VERSION "HNNBNNNYNNNNNNNNNNNNNNNNNNNNNNNNNNNNNNNNNN/4/%%%/4/'%**4NNN///"

NS_ :

BS_:

BU_: BAP_Tester ELV Gateway_Max HUD Kombi

BO_ 1624 Licht_vorne_01: 8 Gateway_Max
 SG_ Licht_Vorne_01_CRC : 0|8@1+ (1,0) [0|255] ""  Vector__XXX
 SG_ Licht_Vorne_01_BZ : 8|4@1+ (1,0) [0|15] ""  Vector__XXX
 SG_ LV_Standlicht_Anzeige : 12|1@1+ (1.0,0.0) [0.0|1] ""  Kombi
 SG_ LV_Abblendlicht_Anzeige : 13|1@1+ (1.0,0.0) [0.0|1] ""  Kombi
 SG_ LV_Fernlicht_Anzeige : 14|1@1+ (1.0,0.0) [0.0|1] ""  Kombi
 SG_ LV_Nebellicht_Anzeige : 15|1@1+ (1.0,0.0) [0.0|1] ""  Kombi
 SG_ LV_Nebelschlusslicht_Anzeige : 16|1@1+ (1.0,0.0) [0.0|1] ""  Kombi
 SG_ LV_Tagfahrlicht_Anzeige : 17|1@1+ (1.0,0.0) [0.0|1] ""  Kombi
 SG_ LV_AFL_aktiv_Anzeige : 18|1@1+ (1.0,0.0) [0.0|1] ""  Kombi
 SG_ LV_AFL_defekt : 19|1@1+ (1.0,0.0) [0.0|1] ""  Kombi
 SG_ LV_Blinker_li_def : 20|1@1+ (1.0,0.0) [0.0|1] ""  Kombi
 SG_ LV_Standlicht_li_def : 21|1@1+ (1.0,0.0) [0.0|1] ""  Kombi
 SG_ LV_Abblendlicht_li_def : 22|1@1+ (1.0,0.0) [0.0|1] ""  Kombi
 SG_ LV_Fernlicht_li_def : 23|1@1+ (1.0,0.0) [0.0|1] ""  Kombi
 SG_ LV_Nebellicht_li_def : 24|1@1+ (1.0,0.0) [0.0|1] ""  Kombi
 SG_ LV_Blk_li_Seite_def : 25|1@1+ (1.0,0.0) [0.0|1] ""  Kombi
 SG_ LV_Tagfahrlicht_li_def : 26|1@1+ (1.0,0.0) [0.0|1] ""  Kombi
 SG_ LV_FLA_aktiv_Anzeige : 27|1@1+ (1.0,0.0) [0.0|1] ""  Kombi
 SG_ LV_FLA_defekt : 28|1@1+ (1.0,0.0) [0.0|1] ""  Kombi
 SG_ LV_FLA_Sensor_blockiert : 29|1@1+ (1.0,0.0) [0.0|1] ""  Kombi
 SG_ LV_Blinker_re_def : 30|1@1+ (1.0,0.0) [0.0|1] ""  Kombi
 SG_ LV_Standlicht_re_def : 31|1@1+ (1.0,0.0) [0.0|1] ""  Kombi
 SG_ LV_Abblendlicht_re_def : 32|1@1+ (1.0,0.0) [0.0|1] ""  Kombi
 SG_ LV_Fernlicht_re_def : 33|1@1+ (1.0,0.0) [0.0|1] ""  Kombi
 SG_ LV_Nebellicht_re_def : 34|1@1+ (1.0,0.0) [0.0|1] ""  Kombi
 SG_ LV_Blk_re_Seite_def : 35|1@1+ (1.0,0.0) [0.0|1] ""  Kombi
 SG_ LV_Tagfahrlicht_re_def : 36|1@1+ (1.0,0.0) [0.0|1] ""  Kombi
 SG_ LV_Aussenlicht_def : 37|1@1+ (1.0,0.0) [0.0|1] ""  Kombi
 SG_ LV_Abblendlicht_TFL_li_def : 38|1@1+ (1.0,0.0) [0.0|1] ""  Kombi
 SG_ LV_Nebellicht_TFL_li_def : 39|1@1+ (1.0,0.0) [0.0|1] ""  Kombi
 SG_ LV_Standlicht_TFL_li_def : 40|1@1+ (1.0,0.0) [0.0|1] ""  Kombi
 SG_ LV_Abblend_Fernlicht_li_def : 41|1@1+ (1.0,0.0) [0.0|1] ""  Kombi
 SG_ LV_Abblendlicht_TFL_re_def : 42|1@1+ (1.0,0.0) [0.0|1] ""  Kombi
 SG_ LV_Nebellicht_TFL_re_def : 43|1@1+ (1.0,0.0) [0.0|1] ""  Kombi
 SG_ LV_Standlicht_TFL_re_def : 44|1@1+ (1.0,0.0) [0.0|1] ""  Kombi
 SG_ LV_Abblend_Fernlicht_re_def : 45|1@1+ (1.0,0.0) [0.0|1] ""  Kombi
 SG_ LV_Abbiegelicht_li_def : 46|1@1+ (1.0,0.0) [0.0|1] ""  Kombi
 SG_ LV_Abbiegelicht_re_def : 47|1@1+ (1.0,0.0) [0.0|1] ""  Kombi
 SG_ BCM1_Linksverkehr : 48|1@1+ (1.0,0.0) [0.0|1] ""  Vector__XXX
 SG_ BCM1_Licht_Dunkelheit_aktiv : 49|1@1+ (1.0,0.0) [0.0|1] ""  Kombi
 SG_ LV_LED_Scheinwerfer_li_def : 50|1@1+ (1.0,0.0) [0.0|1] ""  Kombi
 SG_ LV_LED_Scheinwerfer_re_def : 51|1@1+ (1.0,0.0) [0.0|1] ""  Kombi
 SG_ LV_Blinker_VL_aktiv : 52|1@1+ (1.0,0.0) [0.0|1] ""  Vector__XXX
 SG_ LV_Blinker_VR_aktiv : 53|1@1+ (1.0,0.0) [0.0|1] ""  Vector__XXX
 SG_ LV_MXB_Status_Anzeige : 54|2@1+ (1.0,0.0) [0.0|3] ""  Vector__XXX

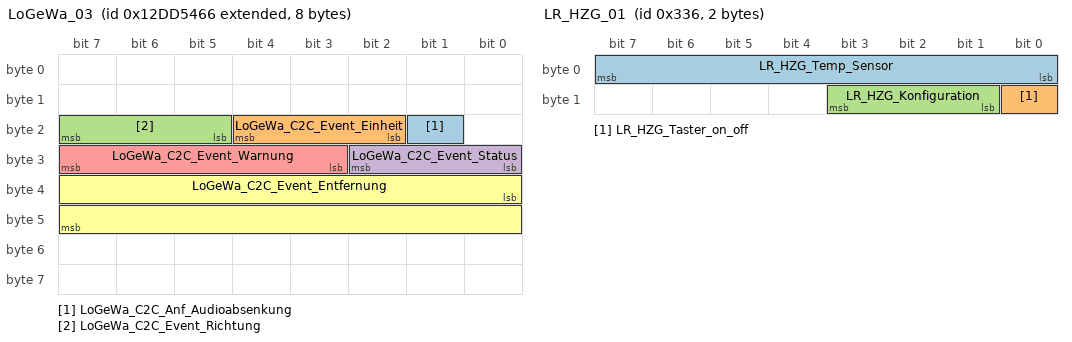
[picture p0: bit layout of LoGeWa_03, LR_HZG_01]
BO_ 2463978598 LoGeWa_03: 8 Gateway_Max
 SG_ LoGeWa_C2C_Anf_Audioabsenkung : 17|1@1+ (1.0,0.0) [0.0|1] ""  Vector__XXX
 SG_ LoGeWa_C2C_Event_Einheit : 18|3@1+ (1.0,0.0) [0.0|7] ""  HUD,Kombi
 SG_ LoGeWa_C2C_Event_Richtung : 21|3@1+ (1.0,0.0) [0.0|7] ""  HUD,Kombi
 SG_ LoGeWa_C2C_Event_Status : 24|3@1+ (1.0,0.0) [0.0|7] ""  HUD,Kombi
 SG_ LoGeWa_C2C_Event_Warnung : 27|5@1+ (1.0,0.0) [0.0|31] ""  HUD,Kombi
 SG_ LoGeWa_C2C_Event_Entfernung : 32|16@1+ (0.1,0) [0.0|6553.4] "Unit_None"  HUD,Kombi

BO_ 822 LR_HZG_01: 2 Gateway_Max
 SG_ LR_HZG_Temp_Sensor : 0|8@1+ (1,-50) [-50|104] "Unit_DegreCelsi"  Vector__XXX
 SG_ LR_HZG_Taster_on_off : 8|1@1+ (1.0,0.0) [0.0|1] ""  Vector__XXX
 SG_ LR_HZG_Konfiguration : 9|3@1+ (1.0,0.0) [0.0|7] ""  Vector__XXX

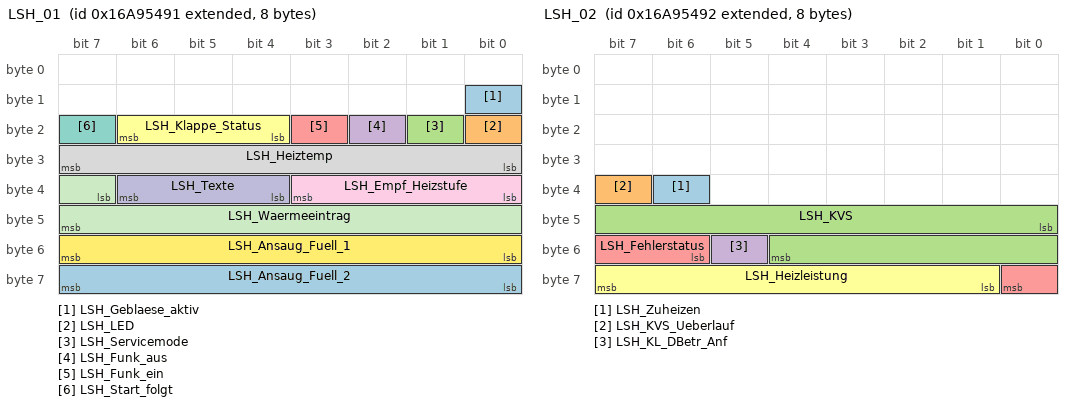
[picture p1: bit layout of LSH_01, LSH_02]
BO_ 2527679633 LSH_01: 8 Gateway_Max
 SG_ LSH_Geblaese_aktiv : 8|1@1+ (1.0,0.0) [0.0|1] ""  Gateway_Max
 SG_ LSH_LED : 16|1@1+ (1.0,0.0) [0.0|1] ""  Gateway_Max
 SG_ LSH_Servicemode : 17|1@1+ (1.0,0.0) [0.0|1] ""  Gateway_Max
 SG_ LSH_Funk_aus : 18|1@1+ (1.0,0.0) [0.0|1] ""  Gateway_Max
 SG_ LSH_Funk_ein : 19|1@1+ (1.0,0.0) [0.0|1] ""  Gateway_Max
 SG_ LSH_Klappe_Status : 20|3@1+ (1.0,0.0) [0.0|7] ""  Gateway_Max
 SG_ LSH_Start_folgt : 23|1@1+ (1.0,0.0) [0.0|1] ""  Gateway_Max
 SG_ LSH_Heiztemp : 24|8@1+ (2,-40) [-40|360] "Unit_DegreCelsi"  Gateway_Max
 SG_ LSH_Empf_Heizstufe : 32|4@1+ (1.0,0.0) [0.0|15] ""  Gateway_Max
 SG_ LSH_Texte : 36|3@1+ (1.0,0.0) [0.0|7] ""  Gateway_Max
 SG_ LSH_Waermeeintrag : 39|9@1+ (5,0) [0|2500] "Unit_Minut"  Gateway_Max
 SG_ LSH_Ansaug_Fuell_1 : 48|8@1+ (0.75,-40) [-40.00|142.25] "Unit_DegreCelsi"  Gateway_Max
 SG_ LSH_Ansaug_Fuell_2 : 56|8@1+ (0.75,-40) [-40.00|142.25] "Unit_DegreCelsi"  Gateway_Max

BO_ 2527679634 LSH_02: 8 Gateway_Max
 SG_ LSH_Zuheizen : 38|1@1+ (1.0,0.0) [0.0|1] ""  Gateway_Max
 SG_ LSH_KVS_Ueberlauf : 39|1@1+ (1.0,0.0) [0.0|1] ""  Gateway_Max
 SG_ LSH_KVS : 40|13@1+ (1,0) [0|8191] "Unit_MilliLiter"  Gateway_Max
 SG_ LSH_KL_DBetr_Anf : 53|1@1+ (1.0,0.0) [0.0|1] ""  Gateway_Max
 SG_ LSH_Fehlerstatus : 54|3@1+ (1.0,0.0) [0.0|7] ""  Gateway_Max
 SG_ LSH_Heizleistung : 57|7@1+ (1,0) [0|100] "Unit_PerCent"  Gateway_Max

BO_ 917 LWR_AFS_01: 8 Gateway_Max
 SG_ AFS_Abbiegelicht_li_Anf : 0|1@1+ (1.0,0.0) [0.0|1] ""  Vector__XXX
 SG_ AFS_Abbiegelicht_re_Anf : 1|1@1+ (1.0,0.0) [0.0|1] ""  Vector__XXX
 SG_ AFS_Abbiegelicht_Dimm_Anf : 2|1@1+ (1.0,0.0) [0.0|1] ""  Vector__XXX
 SG_ AFS_Verfuegbarkeit_GLW : 3|1@1+ (1.0,0.0) [0.0|1] ""  Vector__XXX
 SG_ AFS_Status_adaptive_LV : 4|1@1+ (1.0,0.0) [0.0|1] ""  Vector__XXX
 SG_ AFS_Fernlicht_li_defekt : 5|1@1+ (1.0,0.0) [0.0|1] ""  Vector__XXX
 SG_ AFS_Fernlicht_re_defekt : 6|1@1+ (1.0,0.0) [0.0|1] ""  Vector__XXX
 SG_ AFS_Fernlicht_Status : 7|1@1+ (1.0,0.0) [0.0|1] ""  Vector__XXX
 SG_ LWR_AFS_01_BZ : 8|4@1+ (1,0) [0|15] ""  Vector__XXX
 SG_ AFS_Lampe : 12|1@1+ (1.0,0.0) [0.0|1] ""  Kombi
 SG_ LWR_Lampe : 13|1@1+ (1.0,0.0) [0.0|1] ""  Kombi
 SG_ AFS_Fehlertext : 14|1@1+ (1.0,0.0) [0.0|1] ""  Kombi
 SG_ AFS_LED_Blinkmode : 15|1@1+ (1.0,0.0) [0.0|1] ""  Kombi
 SG_ LWR_Touristenmodus_aktiv : 16|1@1+ (1.0,0.0) [0.0|1] ""  Vector__XXX
 SG_ AFS_Charisma_FahrPr : 17|4@1+ (1.0,0.0) [0.0|15] ""  Vector__XXX
 SG_ AFS_Charisma_Status : 21|2@1+ (1.0,0.0) [0.0|3] ""  Vector__XXX
 SG_ AFS_Allwetterlicht : 24|1@1+ (1.0,0.0) [0.0|1] ""  Vector__XXX
 SG_ LWR_Touristenmodus_verbaut : 25|1@1+ (1.0,0.0) [0.0|1] ""  Vector__XXX
 SG_ AFS_adaptive_LV_verbaut : 26|1@1+ (1.0,0.0) [0.0|1] ""  Vector__XXX
 SG_ LWR_Reisemodus_Texte : 27|2@1+ (1.0,0.0) [0.0|3] ""  Kombi
 SG_ GLW_Sensor_blockiert : 29|1@1+ (1.0,0.0) [0.0|1] ""  Vector__XXX
 SG_ LWR_Pos_Schrittmotor : 32|8@1+ (0.4,0) [0.0|100.0] "Unit_PerCent"  Vector__XXX
 SG_ LWR_Hoehenwert_VL : 40|8@1+ (1,-127) [-127|126] ""  Vector__XXX
 SG_ LWR_Hoehenwert_HL : 48|8@1+ (1,-127) [-127|126] ""  Vector__XXX
 SG_ AFS_Ersatzlicht_Links : 56|1@1+ (1.0,0.0) [0.0|1] ""  Vector__XXX
 SG_ AFS_Ersatzlicht_Rechts : 57|1@1+ (1.0,0.0) [0.0|1] ""  Vector__XXX
 SG_ LWR_AFS_Grundeinstellung : 58|1@1+ (1.0,0.0) [0.0|1] ""  Vector__XXX
 SG_ LWR_AFS_Parametrisierung : 59|1@1+ (1.0,0.0) [0.0|1] ""  Vector__XXX
 SG_ LWR_Initialisierungslauf : 60|1@1+ (1.0,0.0) [0.0|1] ""  Vector__XXX
 SG_ LWR_Sicherheitsposition : 61|1@1+ (1.0,0.0) [0.0|1] ""  Vector__XXX
 SG_ LWR_Modus : 62|1@1+ (1.0,0.0) [0.0|1] ""  Vector__XXX

BO_ 1153 MainUnit_01: 8 Gateway_Max
 SG_ ZR_LoGeWa_Event_Kombiwarnung : 0|4@1+ (1.0,0.0) [0.0|15] ""  Kombi
 SG_ Nav_FoD_Status : 4|3@1+ (1.0,0.0) [0.0|7] ""  HUD,Kombi
 SG_ MIB_ASW_Diagnose : 7|1@1+ (1.0,0.0) [0.0|1] ""  Vector__XXX
 SG_ ZR_Lichter_Tag : 8|1@1+ (1.0,0.0) [0.0|1] ""  Vector__XXX
 SG_ MIB_Tongenerator_PH_verfuegbar : 9|3@1+ (1.0,0.0) [0.0|7] ""  Vector__XXX
 SG_ MMI_Counter_Bedienevent : 12|4@1+ (1.0,0.0) [0.0|15] ""  Vector__XXX
 SG_ DSSS_Warning : 16|5@1+ (1.0,0.0) [0.0|31] ""  Kombi
 SG_ ZR_Kindersicherung_RSE : 21|1@1+ (1.0,0.0) [0.0|1] ""  Vector__XXX
 SG_ ZR_RSE_aktivieren : 22|1@1+ (1.0,0.0) [0.0|1] ""  Vector__XXX
 SG_ MMI_SDS_aktiv : 23|1@1+ (1.0,0.0) [0.0|1] ""  Vector__XXX
 SG_ MU_SecondDisplay : 24|3@1+ (1.0,0.0) [0.0|7] ""  Vector__XXX
 SG_ MMI_Telefon_aktiv : 27|1@1+ (1.0,0.0) [0.0|1] ""  Vector__XXX
 SG_ MMI_Gurt_Mic_ref : 28|1@1+ (1.0,0.0) [0.0|1] ""  Vector__XXX
 SG_ ZR_Sta_Inszenierung : 29|2@1+ (1.0,0.0) [0.0|3] ""  Vector__XXX
 SG_ ZR_AppConnect_Zustand : 31|1@1+ (1.0,0.0) [0.0|1] ""  Vector__XXX
 SG_ MU_Update_Time : 32|8@1+ (0.1,0) [0.0|25.5] "Unit_Hours"  Vector__XXX
 SG_ ZR_Parken_Sondermodus : 48|4@1+ (1.0,0.0) [0.0|15] ""  Vector__XXX

BO_ 1639 Mem_BFS_01: 8 Gateway_Max
 SG_ Mem_BFS_01_CRC : 0|8@1+ (1,0) [0|255] ""  Vector__XXX
 SG_ Mem_BFS_01_BZ : 8|4@1+ (1,0) [0|15] ""  Vector__XXX
 SG_ BFS_Fond_Bed_Ack : 12|1@1+ (1.0,0.0) [0.0|1] ""  Vector__XXX
 SG_ BFS_Lehne_nicht_verriegelt : 13|1@1+ (1.0,0.0) [0.0|1] ""  Vector__XXX
 SG_ BFS_Klapptisch_offen : 14|1@1+ (1.0,0.0) [0.0|1] ""  Vector__XXX
 SG_ BFS_Gurtbringer_Sperre : 15|1@1+ (1.0,0.0) [0.0|1] ""  Vector__XXX
 SG_ BFS_Sitzsym_Fahrt_aktiv : 16|1@1+ (1.0,0.0) [0.0|1] ""  Vector__XXX
 SG_ BFS_Sitzfahrt_aktiv : 17|1@1+ (1.0,0.0) [0.0|1] ""  Vector__XXX
 SG_ BFS_SLV_aktiv : 18|1@1+ (1.0,0.0) [0.0|1] ""  Vector__XXX
 SG_ BFS_SHV_aktiv : 19|1@1+ (1.0,0.0) [0.0|1] ""  Vector__XXX
 SG_ BFS_LNV_aktiv : 20|1@1+ (1.0,0.0) [0.0|1] ""  Vector__XXX
 SG_ BFS_SNV_aktiv : 21|1@1+ (1.0,0.0) [0.0|1] ""  Vector__XXX
 SG_ BFS_KSV_aktiv : 22|1@1+ (1.0,0.0) [0.0|1] ""  Vector__XXX
 SG_ BFS_LKV_aktiv : 23|1@1+ (1.0,0.0) [0.0|1] ""  Vector__XXX
 SG_ BFS_STV_aktiv : 24|1@1+ (1.0,0.0) [0.0|1] ""  Vector__XXX
 SG_ BFS_LHV_aktiv : 25|1@1+ (1.0,0.0) [0.0|1] ""  Vector__XXX
 SG_ BFS_LWV_aktiv : 26|1@1+ (1.0,0.0) [0.0|1] ""  Vector__XXX
 SG_ BFS_GHV_aktiv : 27|1@1+ (1.0,0.0) [0.0|1] ""  Vector__XXX
 SG_ BFS_KSS_Fahrt_aktiv : 28|1@1+ (1.0,0.0) [0.0|1] ""  Vector__XXX
 SG_ BFS_MMB_lokal_Stop : 29|1@1+ (1.0,0.0) [0.0|1] ""  Vector__XXX
 SG_ BFS_Ruhestellung_Status : 30|1@1+ (1.0,0.0) [0.0|1] ""  Vector__XXX
 SG_ BFS_Seat_Locked : 31|1@1+ (1.0,0.0) [0.0|1] ""  Vector__XXX
 SG_ BFS_MMB_storage : 32|4@1+ (1.0,0.0) [0.0|15] ""  Vector__XXX
 SG_ BFS_MMB_tipp : 36|1@1+ (1.0,0.0) [0.0|1] ""  Vector__XXX
 SG_ BFS_MMB_tast : 37|1@1+ (1.0,0.0) [0.0|1] ""  Vector__XXX
 SG_ BFS_MMB_store_LED_on : 38|1@1+ (1.0,0.0) [0.0|1] ""  Vector__XXX
 SG_ BFS_MMB_storage_beep : 39|1@1+ (1.0,0.0) [0.0|1] ""  Kombi
 SG_ BFS_MMB_store : 40|1@1+ (1.0,0.0) [0.0|1] ""  Vector__XXX
 SG_ BFS_MMB_glob_stop : 41|1@1+ (1.0,0.0) [0.0|1] ""  Vector__XXX
 SG_ BFS_FSV_ausgeklappt : 42|1@1+ (1.0,0.0) [0.0|1] ""  Vector__XXX
 SG_ BFS_Klappfunktion_Aktiv : 51|1@1+ (1.0,0.0) [0.0|1] ""  Vector__XXX
 SG_ BFS_Klappfunktion_Bed_Ack : 52|2@1+ (1.0,0.0) [0.0|3] ""  Vector__XXX
 SG_ BFS_Klappfunktion_Beschraenkung : 54|2@1+ (1.0,0.0) [0.0|3] ""  Vector__XXX
 SG_ BFS_Klappfunktion_Status : 56|2@1+ (1.0,0.0) [0.0|3] ""  Vector__XXX

BO_ 2463978884 Mem_BFS_Fond_02: 8 Gateway_Max
 SG_ Mem_BFS_Fond_02_CRC : 0|8@1+ (1,0) [0|255] ""  Kombi
 SG_ Mem_BFS_Fond_02_BZ : 8|4@1+ (1,0) [0|15] ""  Kombi
 SG_ Mem_BFSFo_Warn_Dreh_entriegelt : 12|3@1+ (1.0,0.0) [0.0|7] ""  Kombi
 SG_ Mem_BFSFo_Warn_Verriegelung : 15|2@1+ (1.0,0.0) [0.0|3] ""  Vector__XXX
 SG_ HBFS_Kopfst_unten : 17|1@1+ (1.0,0.0) [0.0|1] ""  Vector__XXX
 SG_ HBFS_Fahrposition : 18|1@1+ (1.0,0.0) [0.0|1] ""  Vector__XXX
 SG_ Mem_HBFS_Seat_Attention : 24|3@1+ (1.0,0.0) [0.0|7] ""  Vector__XXX
 SG_ HBFS_Komfortposition_Status : 27|2@1+ (1.0,0.0) [0.0|3] ""  Vector__XXX
 SG_ HBFS_Komfortposition_Beschraenku : 29|2@1+ (1.0,0.0) [0.0|3] ""  Vector__XXX
 SG_ HBFS_Komfortposition_Aktiv : 31|1@1+ (1.0,0.0) [0.0|1] ""  Vector__XXX
 SG_ HBFS_Anfahrt_Komfortposition : 32|2@1+ (1.0,0.0) [0.0|3] ""  Vector__XXX
 SG_ HBFS_Anfahrt_Klappfunktion : 34|2@1+ (1.0,0.0) [0.0|3] ""  Vector__XXX
 SG_ HBFS_Klappfunktion_Status : 36|2@1+ (1.0,0.0) [0.0|3] ""  Vector__XXX
 SG_ HBFS_Klappfunktion_Beschraenkung : 38|2@1+ (1.0,0.0) [0.0|3] ""  Vector__XXX
 SG_ HBFS_EasyEntry_Aktiv : 48|1@1+ (1.0,0.0) [0.0|1] ""  Vector__XXX
 SG_ HBFS_EasyEntry_Beschraenkung : 49|2@1+ (1.0,0.0) [0.0|3] ""  Vector__XXX
 SG_ HBFS_EasyEntry_Status : 51|2@1+ (1.0,0.0) [0.0|3] ""  Vector__XXX
 SG_ HBFS_Anfahrt_EasyEntry : 53|2@1+ (1.0,0.0) [0.0|3] ""  Vector__XXX
 SG_ HBFS_Klappfunktion_Aktiv : 55|1@1+ (1.0,0.0) [0.0|1] ""  Vector__XXX
 SG_ Zielpositio_Hoeh_BFS_fur_EA_HBFS : 56|8@1+ (1,0) [0|255] ""  Vector__XXX

BO_ 2463978889 Mem_BFS_Fond_03: 8 Gateway_Max
 SG_ Mem_BFS_Fond_03_CRC : 0|8@1+ (1,0) [0|255] ""  Kombi
 SG_ Mem_BFS_Fond_03_BZ : 8|4@1+ (1,0) [0|15] ""  Kombi
 SG_ Mem_HBFSFo_Warnung_Softstop : 12|2@1+ (1.0,0.0) [0.0|3] ""  Vector__XXX
 SG_ Mem_HBFSFo_Stoerung : 14|2@1+ (1.0,0.0) [0.0|3] ""  Kombi
 SG_ Mem_HBFSFo_globaler_Lehnenwinkel : 16|8@1+ (1,0) [0|253] ""  Vector__XXX
 SG_ Mem_HBFSFo_globaler_Sitzflachenw : 24|8@1+ (1,0) [0|253] ""  Vector__XXX
 SG_ Mem_HBFSFo_Sperre_Sitzdisplay : 32|1@1+ (1.0,0.0) [0.0|1] ""  Vector__XXX
 SG_ Mem_HBFSFo_Abschaltanf_SRAB : 33|2@1+ (1.0,0.0) [0.0|3] ""  Vector__XXX
 SG_ Mem_HBFSFo_Anzeige_Komfort_HBFS : 35|3@1+ (1.0,0.0) [0.0|7] ""  Kombi
 SG_ Mem_HBFSFo_Status_Schalter_Ki_Si : 38|2@1+ (1.0,0.0) [0.0|3] ""  Vector__XXX
 SG_ Mem_HBFSFo_ARMTuer_aktiv : 40|1@1+ (1.0,0.0) [0.0|1] ""  Vector__XXX
 SG_ Mem_HBFSFo_ARMTunnel_aktiv : 41|1@1+ (1.0,0.0) [0.0|1] ""  Vector__XXX
 SG_ Mem_HBFSFo_SHV_aktiv : 42|1@1+ (1.0,0.0) [0.0|1] ""  Vector__XXX
 SG_ Mem_HBFSFo_SLV_aktiv : 43|1@1+ (1.0,0.0) [0.0|1] ""  Vector__XXX
 SG_ Mem_HBFSFo_SLV_hinten : 44|1@1+ (1.0,0.0) [0.0|1] ""  Vector__XXX
 SG_ Mem_HBFSFo_BATV_aktiv : 45|1@1+ (1.0,0.0) [0.0|1] ""  Vector__XXX
 SG_ Mem_HBFSFo_EE_Entriegl_Motor : 46|1@1+ (1.0,0.0) [0.0|1] ""  Vector__XXX
 SG_ Mem_HBFSFo_EE_Verr_Sensor_re : 47|3@1+ (1.0,0.0) [0.0|7] ""  Vector__XXX
 SG_ Mem_HBFSFo_Verr_Sensor_oben_re : 50|3@1+ (1.0,0.0) [0.0|7] ""  Vector__XXX
 SG_ Mem_HBFSFo_Verr_Sensor_unten_re : 53|3@1+ (1.0,0.0) [0.0|7] ""  Vector__XXX
 SG_ Mem_HBFSFo_LNV_aktiv : 56|1@1+ (1.0,0.0) [0.0|1] ""  Vector__XXX
 SG_ Mem_HBFSFo_SNV_aktiv : 57|1@1+ (1.0,0.0) [0.0|1] ""  Vector__XXX
 SG_ Mem_HBFSFo_KSV_aktiv : 58|1@1+ (1.0,0.0) [0.0|1] ""  Vector__XXX
 SG_ Mem_HBFSFo_LKV_aktiv : 59|1@1+ (1.0,0.0) [0.0|1] ""  Vector__XXX
 SG_ Mem_HBFSFo_STV_aktiv : 60|1@1+ (1.0,0.0) [0.0|1] ""  Vector__XXX
 SG_ Mem_HBFSFo_BANV_aktiv : 61|1@1+ (1.0,0.0) [0.0|1] ""  Vector__XXX
 SG_ Mem_HBFSFo_LED_EA_Taster : 62|2@1+ (1.0,0.0) [0.0|3] ""  Vector__XXX

BO_ 1178 Mem_FS_01: 8 Gateway_Max
 SG_ Mem_FS_01_MQB_CRC : 0|8@1+ (1,0) [0|255] ""  Vector__XXX
 SG_ Mem_FS_01_MQB_BZ : 8|4@1+ (1,0) [0|15] ""  Vector__XXX
 SG_ FS_Fond_Bed_enable : 12|1@1+ (1.0,0.0) [0.0|1] ""  Vector__XXX
 SG_ FS_Lehne_nicht_verriegelt : 13|1@1+ (1.0,0.0) [0.0|1] ""  Vector__XXX
 SG_ FS_Spezialposition_anfahren : 14|1@1+ (1.0,0.0) [0.0|1] ""  Vector__XXX
 SG_ FS_Gurtbringer_Sperre : 15|1@1+ (1.0,0.0) [0.0|1] ""  Vector__XXX
 SG_ FS_BFS_Sitzsym_Anfahrt : 16|1@1+ (1.0,0.0) [0.0|1] ""  Vector__XXX
 SG_ FS_Sitzfahrt_aktiv : 17|1@1+ (1.0,0.0) [0.0|1] ""  Vector__XXX
 SG_ FS_SLV_aktiv : 18|1@1+ (1.0,0.0) [0.0|1] ""  Vector__XXX
 SG_ FS_SHV_aktiv : 19|1@1+ (1.0,0.0) [0.0|1] ""  Vector__XXX
 SG_ FS_LNV_aktiv : 20|1@1+ (1.0,0.0) [0.0|1] ""  Vector__XXX
 SG_ FS_SNV_aktiv : 21|1@1+ (1.0,0.0) [0.0|1] ""  Vector__XXX
 SG_ FS_KSV_aktiv : 22|1@1+ (1.0,0.0) [0.0|1] ""  Vector__XXX
 SG_ FS_LKV_aktiv : 23|1@1+ (1.0,0.0) [0.0|1] ""  Vector__XXX
 SG_ FS_STV_aktiv : 24|1@1+ (1.0,0.0) [0.0|1] ""  Vector__XXX
 SG_ FS_LHV_aktiv : 25|1@1+ (1.0,0.0) [0.0|1] ""  Vector__XXX
 SG_ FS_LWV_aktiv : 26|1@1+ (1.0,0.0) [0.0|1] ""  Vector__XXX
 SG_ FS_GHV_aktiv : 27|1@1+ (1.0,0.0) [0.0|1] ""  Vector__XXX
 SG_ FS_BFS_KSS_Anfahrt : 28|1@1+ (1.0,0.0) [0.0|1] ""  Vector__XXX
 SG_ FS_MMB_lokal_Stop : 29|1@1+ (1.0,0.0) [0.0|1] ""  Vector__XXX
 SG_ FS_MMB_storage : 32|4@1+ (1.0,0.0) [0.0|15] ""  Vector__XXX
 SG_ FS_MMB_tipp : 36|1@1+ (1.0,0.0) [0.0|1] ""  Vector__XXX
 SG_ FS_MMB_tast : 37|1@1+ (1.0,0.0) [0.0|1] ""  Vector__XXX
 SG_ FS_MMB_store_LED_on : 38|1@1+ (1.0,0.0) [0.0|1] ""  Vector__XXX
 SG_ FS_MMB_storage_beep : 39|1@1+ (1.0,0.0) [0.0|1] ""  Kombi
 SG_ FS_MMB_store : 40|1@1+ (1.0,0.0) [0.0|1] ""  Vector__XXX
 SG_ FS_MMB_glob_stop : 41|1@1+ (1.0,0.0) [0.0|1] ""  Vector__XXX
 SG_ FS_EE_Fond_FS_enable : 42|1@1+ (1.0,0.0) [0.0|1] ""  Vector__XXX
 SG_ FS_EE_Fond_BFS_enable : 43|1@1+ (1.0,0.0) [0.0|1] ""  Vector__XXX
 SG_ FS_BFS_Fond_Verst_enable : 44|1@1+ (1.0,0.0) [0.0|1] ""  Vector__XXX
 SG_ FS_EE_BFS_enable : 45|1@1+ (1.0,0.0) [0.0|1] ""  Vector__XXX

BO_ 956 Mem_FS_Fond_01: 8 Gateway_Max
 SG_ Mem_FS_Fond_01_CRC : 0|8@1+ (1,0) [0|255] ""  Kombi
 SG_ Mem_FS_Fond_01_BZ : 8|4@1+ (1,0) [0|15] ""  Kombi
 SG_ Mem_FSFo_Lordose_hoch : 12|1@1+ (1.0,0.0) [0.0|1] ""  Vector__XXX
 SG_ Mem_FSFo_Lordose_runter : 13|1@1+ (1.0,0.0) [0.0|1] ""  Vector__XXX
 SG_ Mem_FSFo_Lordose_vor : 14|1@1+ (1.0,0.0) [0.0|1] ""  Vector__XXX
 SG_ Mem_FSFo_Lordose_zurueck : 15|1@1+ (1.0,0.0) [0.0|1] ""  Vector__XXX
 SG_ Mem_FSFo_Massage_Geschw : 16|3@1+ (1.0,0.0) [0.0|7] ""  Vector__XXX
 SG_ Mem_FSFo_Massage_Intens : 19|3@1+ (1.0,0.0) [0.0|7] ""  Vector__XXX
 SG_ Mem_FSFo_MMB_storage : 22|2@1+ (1.0,0.0) [0.0|3] ""  Vector__XXX
 SG_ Mem_FSFo_Massage_Prg : 24|3@1+ (1.0,0.0) [0.0|7] ""  Vector__XXX
 SG_ Mem_FSFo_MMB_tast : 27|1@1+ (1.0,0.0) [0.0|1] ""  Vector__XXX
 SG_ Mem_FSFo_MMB_tipp : 28|1@1+ (1.0,0.0) [0.0|1] ""  Vector__XXX
 SG_ Mem_FSFo_MMB_glob_Stop : 29|1@1+ (1.0,0.0) [0.0|1] ""  Vector__XXX
 SG_ Mem_FSFo_Sitztiefe_vor : 30|1@1+ (1.0,0.0) [0.0|1] ""  Vector__XXX
 SG_ Mem_FSFo_Sitztiefe_zur : 31|1@1+ (1.0,0.0) [0.0|1] ""  Vector__XXX
 SG_ Mem_FSFo_MMB_store : 32|1@1+ (1.0,0.0) [0.0|1] ""  Vector__XXX
 SG_ Mem_FSFo_MMB_storage_beep : 33|1@1+ (1.0,0.0) [0.0|1] ""  Vector__XXX
 SG_ Mem_FSFo_MMB_store_LED_on : 34|1@1+ (1.0,0.0) [0.0|1] ""  Vector__XXX
 SG_ Mem_HFSFo_EA_Taster : 35|1@1+ (1.0,0.0) [0.0|1] ""  Vector__XXX
 SG_ Mem_FSFo_MMB_lokal_Stop : 36|1@1+ (1.0,0.0) [0.0|1] ""  Vector__XXX
 SG_ Mem_FSFo_Sitzfahrt_aktiv : 37|1@1+ (1.0,0.0) [0.0|1] ""  Vector__XXX
 SG_ Mem_HFSFo_Unlocked : 38|2@1+ (1.0,0.0) [0.0|3] ""  Vector__XXX
 SG_ Mem_FSFo_Warn_Verriegelung : 40|2@1+ (1.0,0.0) [0.0|3] ""  Vector__XXX
 SG_ Mem_FSFo_Business_anfahren : 42|1@1+ (1.0,0.0) [0.0|1] ""  Vector__XXX
 SG_ Mem_FSFo_Relax_anfahren : 43|1@1+ (1.0,0.0) [0.0|1] ""  Vector__XXX
 SG_ Mem_FSFo_Warn_Dreh_entriegelt : 56|3@1+ (1.0,0.0) [0.0|7] ""  Kombi
 SG_ Mem_HFS_Seat_Attention : 59|3@1+ (1.0,0.0) [0.0|7] ""  Vector__XXX

BO_ 2463978890 Mem_FS_Fond_03: 8 Gateway_Max
 SG_ Mem_FS_Fond_03_CRC : 0|8@1+ (1,0) [0|255] ""  Kombi
 SG_ Mem_FS_Fond_03_BZ : 8|4@1+ (1,0) [0|15] ""  Kombi
 SG_ Mem_HFSFo_Warnung_Softstop : 12|2@1+ (1.0,0.0) [0.0|3] ""  Vector__XXX
 SG_ Mem_HFSFo_Stoerung : 14|2@1+ (1.0,0.0) [0.0|3] ""  Kombi
 SG_ Mem_HFSFo_globaler_Lehnenwinkel : 16|8@1+ (1,0) [0|253] ""  Vector__XXX
 SG_ Mem_HFSFo_globaler_Sitzflachenwi : 24|8@1+ (1,0) [0|253] ""  Vector__XXX
 SG_ Mem_HFSFo_Sperre_Sitzdisplay : 32|1@1+ (1.0,0.0) [0.0|1] ""  Vector__XXX
 SG_ Mem_HFSFo_Abschaltanf_SRAB : 33|2@1+ (1.0,0.0) [0.0|3] ""  Vector__XXX
 SG_ Mem_HFSFo_Anzeige_Komfort_HFS : 35|3@1+ (1.0,0.0) [0.0|7] ""  Kombi
 SG_ Mem_HFSFo_Status_Schalter_Ki_Si : 38|2@1+ (1.0,0.0) [0.0|3] ""  Vector__XXX
 SG_ Mem_HFSFo_ARMTuer_aktiv : 40|1@1+ (1.0,0.0) [0.0|1] ""  Vector__XXX
 SG_ Mem_HFSFo_ARMTunnel_aktiv : 41|1@1+ (1.0,0.0) [0.0|1] ""  Vector__XXX
 SG_ Mem_HFSFo_SHV_aktiv : 42|1@1+ (1.0,0.0) [0.0|1] ""  Vector__XXX
 SG_ Mem_HFSFo_SLV_aktiv : 43|1@1+ (1.0,0.0) [0.0|1] ""  Vector__XXX
 SG_ Mem_HFSFo_SLV_hinten : 44|1@1+ (1.0,0.0) [0.0|1] ""  Vector__XXX
 SG_ Mem_HFSFo_BATV_aktiv : 45|1@1+ (1.0,0.0) [0.0|1] ""  Vector__XXX
 SG_ Mem_HFSFo_EE_Verr_Sensor_li : 46|3@1+ (1.0,0.0) [0.0|7] ""  Vector__XXX
 SG_ Mem_HFSFo_Verr_Sensor_oben_li : 49|3@1+ (1.0,0.0) [0.0|7] ""  Vector__XXX
 SG_ Mem_HFSFo_Verr_Sensor_unten_li : 52|3@1+ (1.0,0.0) [0.0|7] ""  Vector__XXX
 SG_ Mem_HFSFo_LNV_aktiv : 55|1@1+ (1.0,0.0) [0.0|1] ""  Vector__XXX
 SG_ Mem_HFSFo_SNV_aktiv : 56|1@1+ (1.0,0.0) [0.0|1] ""  Vector__XXX
 SG_ Mem_HFSFo_KSV_aktiv : 57|1@1+ (1.0,0.0) [0.0|1] ""  Vector__XXX
 SG_ Mem_HFSFo_LKV_aktiv : 58|1@1+ (1.0,0.0) [0.0|1] ""  Vector__XXX
 SG_ Mem_HFSFo_STV_aktiv : 59|1@1+ (1.0,0.0) [0.0|1] ""  Vector__XXX
 SG_ Mem_HFSFo_BANV_aktiv : 60|1@1+ (1.0,0.0) [0.0|1] ""  Vector__XXX
 SG_ Mem_HFSFo_LED_EA_Taster : 61|2@1+ (1.0,0.0) [0.0|3] ""  Vector__XXX
 SG_ Mem_HFSFo_EA_Position : 63|1@1+ (1.0,0.0) [0.0|1] ""  Vector__XXX

BO_ 1171 MFG_01: 8 Vector__XXX
 SG_ MFG_01_CRC : 0|8@1+ (1,0) [0|255] ""  Gateway_Max
 SG_ MFG_01_BZ : 8|4@1+ (1,0) [0|15] ""  Gateway_Max
 SG_ MF_ZV_Lock : 12|1@1+ (1.0,0.0) [0.0|1] ""  Gateway_Max
 SG_ MF_Motorweiterlauf : 13|1@1+ (1.0,0.0) [0.0|1] ""  Gateway_Max,Kombi
 SG_ MF_Abzugssperre : 14|1@1+ (1.0,0.0) [0.0|1] ""  Gateway_Max
 SG_ MF_Anlassersperre : 15|1@1+ (1.0,0.0) [0.0|1] ""  Gateway_Max
 SG_ MF_Variante : 16|3@1+ (1.0,0.0) [0.0|7] ""  Gateway_Max
 SG_ MF_Schluessel_scan : 19|1@1+ (1.0,0.0) [0.0|1] ""  Gateway_Max
 SG_ MF_Laderelais : 20|1@1+ (1.0,0.0) [0.0|1] ""  Gateway_Max
 SG_ MF_StartStopp_Info : 21|2@1+ (1.0,0.0) [0.0|3] ""  Gateway_Max
 SG_ MF_Fernbed_ein : 23|1@1+ (1.0,0.0) [0.0|1] ""  Gateway_Max
 SG_ MF_Standlicht : 24|1@1+ (1.0,0.0) [0.0|1] ""  Gateway_Max
 SG_ MF_Fahrlicht : 25|1@1+ (1.0,0.0) [0.0|1] ""  Gateway_Max
 SG_ MF_interm_Fernlicht : 26|1@1+ (1.0,0.0) [0.0|1] ""  Gateway_Max
 SG_ MF_Warnblinker : 27|1@1+ (1.0,0.0) [0.0|1] ""  Gateway_Max
 SG_ MF_Fussraumbel : 28|1@1+ (1.0,0.0) [0.0|1] ""  Gateway_Max
 SG_ MF_Innenraumbel : 29|1@1+ (1.0,0.0) [0.0|1] ""  Gateway_Max
 SG_ MF_Innenraumbel_Unterdrueck : 30|1@1+ (1.0,0.0) [0.0|1] ""  Gateway_Max
 SG_ MF_Notstart : 31|1@1+ (1.0,0.0) [0.0|1] ""  Gateway_Max
 SG_ MF_Blk_li : 32|1@1+ (1.0,0.0) [0.0|1] ""  Gateway_Max
 SG_ MF_Blk_re : 33|1@1+ (1.0,0.0) [0.0|1] ""  Gateway_Max
 SG_ MF_Lichthupe : 34|1@1+ (1.0,0.0) [0.0|1] ""  Gateway_Max
 SG_ MF_Fernlicht : 35|1@1+ (1.0,0.0) [0.0|1] ""  Gateway_Max
 SG_ MF_HFS_verriegeln : 36|1@1+ (1.0,0.0) [0.0|1] ""  Gateway_Max
 SG_ MF_HFS_entriegeln : 37|1@1+ (1.0,0.0) [0.0|1] ""  Gateway_Max
 SG_ MF_HBFS_verriegeln : 38|1@1+ (1.0,0.0) [0.0|1] ""  Gateway_Max
 SG_ MF_HBFS_entriegeln : 39|1@1+ (1.0,0.0) [0.0|1] ""  Gateway_Max
 SG_ MF_Tippwischen : 40|1@1+ (1.0,0.0) [0.0|1] ""  Gateway_Max
 SG_ MF_Frontintervall : 41|1@1+ (1.0,0.0) [0.0|1] ""  Gateway_Max
 SG_ MF_Wischerstufe_1 : 42|1@1+ (1.0,0.0) [0.0|1] ""  Gateway_Max
 SG_ MF_Wischerstufe_2 : 43|1@1+ (1.0,0.0) [0.0|1] ""  Gateway_Max
 SG_ MF_Frontwaschen : 44|1@1+ (1.0,0.0) [0.0|1] ""  Gateway_Max
 SG_ MF_nachtr_Stopp_Anf : 45|1@1+ (1.0,0.0) [0.0|1] ""  Gateway_Max
 SG_ MF_Heckintervall : 46|1@1+ (1.0,0.0) [0.0|1] ""  Gateway_Max
 SG_ MF_Heckwaschen : 47|1@1+ (1.0,0.0) [0.0|1] ""  Gateway_Max
 SG_ MF_Summer : 48|1@1+ (1.0,0.0) [0.0|1] ""  Gateway_Max,Kombi
 SG_ MF_Alarm_Blinkertakt : 49|1@1+ (1.0,0.0) [0.0|1] ""  Gateway_Max
 SG_ MF_Alarm_Blinker : 50|1@1+ (1.0,0.0) [0.0|1] ""  Gateway_Max
 SG_ MF_TFL_Abschaltung : 51|1@1+ (1.0,0.0) [0.0|1] ""  Gateway_Max
 SG_ MF_interm_Takt : 52|1@1+ (1.0,0.0) [0.0|1] ""  Gateway_Max
 SG_ MF_Tuerentriegelung_hinten : 53|1@1+ (1.0,0.0) [0.0|1] ""  Gateway_Max
 SG_ MF_interm_Fahrlicht : 54|1@1+ (1.0,0.0) [0.0|1] ""  Gateway_Max
 SG_ MF_Signalhorn : 55|1@1+ (1.0,0.0) [0.0|1] ""  Gateway_Max
 SG_ MF_FH_FT_hoch : 56|1@1+ (1.0,0.0) [0.0|1] ""  Gateway_Max
 SG_ MF_FH_FT_tief : 57|1@1+ (1.0,0.0) [0.0|1] ""  Gateway_Max
 SG_ MF_FH_BT_hoch : 58|1@1+ (1.0,0.0) [0.0|1] ""  Gateway_Max
 SG_ MF_FH_BT_tief : 59|1@1+ (1.0,0.0) [0.0|1] ""  Gateway_Max
 SG_ MF_FT_verriegeln : 60|1@1+ (1.0,0.0) [0.0|1] ""  Gateway_Max
 SG_ MF_FT_entriegeln : 61|1@1+ (1.0,0.0) [0.0|1] ""  Gateway_Max
 SG_ MF_BT_verriegeln : 62|1@1+ (1.0,0.0) [0.0|1] ""  Gateway_Max
 SG_ MF_BT_entriegeln : 63|1@1+ (1.0,0.0) [0.0|1] ""  Gateway_Max

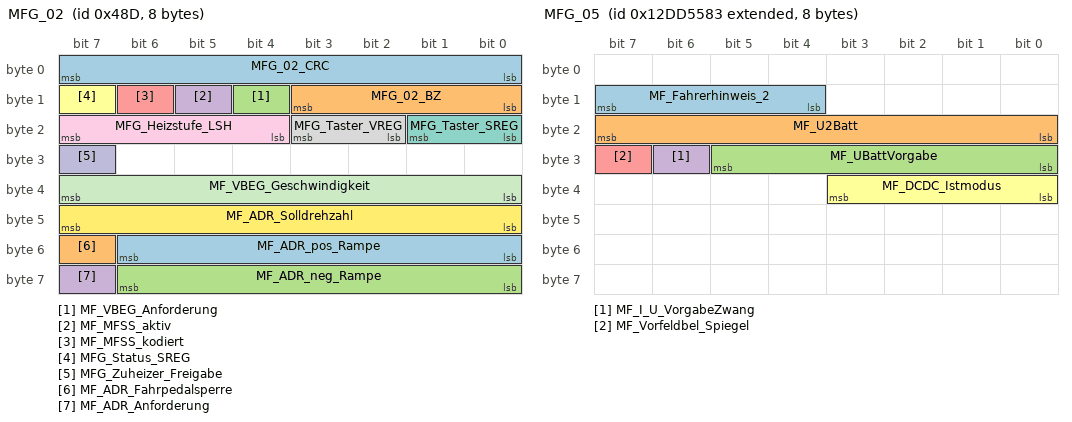
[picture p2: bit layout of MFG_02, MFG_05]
BO_ 1165 MFG_02: 8 Vector__XXX
 SG_ MFG_02_CRC : 0|8@1+ (1,0) [0|255] ""  Gateway_Max
 SG_ MFG_02_BZ : 8|4@1+ (1,0) [0|15] ""  Gateway_Max
 SG_ MF_VBEG_Anforderung : 12|1@1+ (1.0,0.0) [0.0|1] ""  Gateway_Max
 SG_ MF_MFSS_aktiv : 13|1@1+ (1.0,0.0) [0.0|1] ""  Gateway_Max
 SG_ MF_MFSS_kodiert : 14|1@1+ (1.0,0.0) [0.0|1] ""  Gateway_Max
 SG_ MFG_Status_SREG : 15|1@1+ (1.0,0.0) [0.0|1] ""  Gateway_Max
 SG_ MFG_Taster_SREG : 16|2@1+ (1.0,0.0) [0.0|3] ""  Gateway_Max
 SG_ MFG_Taster_VREG : 18|2@1+ (1.0,0.0) [0.0|3] ""  Gateway_Max
 SG_ MFG_Heizstufe_LSH : 20|4@1+ (1.0,0.0) [0.0|15] ""  Gateway_Max
 SG_ MFG_Zuheizer_Freigabe : 31|1@1+ (1.0,0.0) [0.0|1] ""  Gateway_Max
 SG_ MF_VBEG_Geschwindigkeit : 32|8@1+ (1,0) [0|254] "Unit_KiloMeterPerHour"  Gateway_Max
 SG_ MF_ADR_Solldrehzahl : 40|8@1+ (20,0) [0|5100] "Unit_MinutInver"  Gateway_Max
 SG_ MF_ADR_pos_Rampe : 48|7@1+ (10,0) [0|1000] ""  Gateway_Max
 SG_ MF_ADR_Fahrpedalsperre : 55|1@1+ (1.0,0.0) [0.0|1] ""  Gateway_Max
 SG_ MF_ADR_neg_Rampe : 56|7@1+ (10,0) [0|1000] ""  Gateway_Max
 SG_ MF_ADR_Anforderung : 63|1@1+ (1.0,0.0) [0.0|1] ""  Gateway_Max

BO_ 1164 MFG_03: 8 Vector__XXX
 SG_ MFG_Infotainment_Autark : 12|1@1+ (1.0,0.0) [0.0|1] ""  Gateway_Max
 SG_ MFG_Klappe_Status : 13|3@1+ (1.0,0.0) [0.0|7] ""  Gateway_Max
 SG_ MFG_LSH_DBetr_Ein : 16|1@1+ (1.0,0.0) [0.0|1] ""  Gateway_Max
 SG_ MFG_LSH_Betriebsdauer : 17|7@1+ (1,0) [0|120] "Unit_Minut"  Gateway_Max
 SG_ MFG_LSH_DBetr_Bestaet : 24|1@1+ (1.0,0.0) [0.0|1] ""  Gateway_Max
 SG_ MFG_LSH_Ansteuerung : 25|2@1+ (1.0,0.0) [0.0|3] ""  Gateway_Max
 SG_ MF_Radiomute : 27|1@1+ (1.0,0.0) [0.0|1] ""  Gateway_Max
 SG_ MF_Relais_2_Batterie : 28|1@1+ (1.0,0.0) [0.0|1] ""  Gateway_Max
 SG_ MF_Batteriediagnose : 29|3@1+ (1.0,0.0) [0.0|7] ""  Gateway_Max
 SG_ MFG_AppConnect_Anf : 32|2@1+ (1.0,0.0) [0.0|3] ""  Gateway_Max
 SG_ MF_Lampenausfall : 34|1@1+ (1.0,0.0) [0.0|1] ""  Gateway_Max
 SG_ MF_Blinker_L_Sta : 35|1@1+ (1.0,0.0) [0.0|1] ""  Gateway_Max
 SG_ MF_Blinker_R_Sta : 36|1@1+ (1.0,0.0) [0.0|1] ""  Gateway_Max
 SG_ MF_interm_Nebelscheinwerfer : 37|1@1+ (1.0,0.0) [0.0|1] ""  Gateway_Max
 SG_ MF_Generatordiagnose : 38|2@1+ (1.0,0.0) [0.0|3] ""  Gateway_Max
 SG_ MF_Heck_entriegeln : 40|1@1+ (1.0,0.0) [0.0|1] ""  Gateway_Max
 SG_ MF_Heck_verriegeln : 41|1@1+ (1.0,0.0) [0.0|1] ""  Gateway_Max
 SG_ MF_2BatSOCzugering : 42|1@1+ (1.0,0.0) [0.0|1] ""  Gateway_Max,Kombi
 SG_ MF_Fahrerhinweis : 43|3@1+ (1.0,0.0) [0.0|7] ""  Gateway_Max,Kombi
 SG_ MF_ZV_Unlock : 46|1@1+ (1.0,0.0) [0.0|1] ""  Gateway_Max
 SG_ MF_Tuerverriegelung_hinten : 47|1@1+ (1.0,0.0) [0.0|1] ""  Gateway_Max
 SG_ MF_2BattAb : 48|1@1+ (1.0,0.0) [0.0|1] ""  Gateway_Max,Kombi
 SG_ MF_2BattHlkAnf : 49|1@1+ (1.0,0.0) [0.0|1] ""  Gateway_Max
 SG_ MF_2BattLadWarn : 50|1@1+ (1.0,0.0) [0.0|1] ""  Gateway_Max,Kombi
 SG_ MF_2BattLlaAnf : 51|1@1+ (1.0,0.0) [0.0|1] ""  Gateway_Max
 SG_ MF_2BattSpannungsAnf : 52|2@1+ (1.0,0.0) [0.0|3] ""  Gateway_Max
 SG_ MF_NotStartAktiv : 54|1@1+ (1.0,0.0) [0.0|1] ""  Gateway_Max,Kombi
 SG_ MF_ExterneLadungWarn : 55|1@1+ (1.0,0.0) [0.0|1] ""  Gateway_Max,Kombi
 SG_ MF_LSH_Zielzeit : 56|4@1+ (10,0) [0|130] "Unit_Minut"  Gateway_Max
 SG_ MF_LSH_Abschaltstufe : 60|3@1+ (1.0,0.0) [0.0|7] ""  Gateway_Max
 SG_ MF_LSH_Einschaltverbot : 63|1@1+ (1.0,0.0) [0.0|1] ""  Gateway_Max

BO_ 2463978883 MFG_05: 8 Vector__XXX
 SG_ MF_Fahrerhinweis_2 : 12|4@1+ (1.0,0.0) [0.0|15] ""  Gateway_Max,Kombi
 SG_ MF_U2Batt : 16|8@1+ (0.01,12.5) [12.50|15.00] "Unit_Volt"  Gateway_Max
 SG_ MF_UBattVorgabe : 24|6@1+ (0.1,12) [12.0|18.0] "Unit_Volt"  Gateway_Max
 SG_ MF_I_U_VorgabeZwang : 30|1@1+ (1.0,0.0) [0.0|1] ""  Gateway_Max
 SG_ MF_Vorfeldbel_Spiegel : 31|1@1+ (1.0,0.0) [0.0|1] ""  Gateway_Max
 SG_ MF_DCDC_Istmodus : 32|4@1+ (1.0,0.0) [0.0|15] ""  Gateway_Max

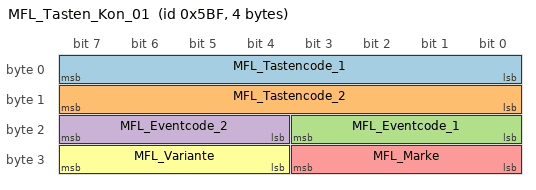
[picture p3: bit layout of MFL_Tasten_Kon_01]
BO_ 1471 MFL_Tasten_Kon_01: 4 Gateway_Max
 SG_ MFL_Tastencode_1 : 0|8@1+ (1.0,0.0) [0.0|255] ""  HUD,Kombi
 SG_ MFL_Tastencode_2 : 8|8@1+ (1.0,0.0) [0.0|255] ""  HUD,Kombi
 SG_ MFL_Eventcode_1 : 16|4@1+ (1.0,0.0) [0.0|15] ""  HUD,Kombi
 SG_ MFL_Eventcode_2 : 20|4@1+ (1.0,0.0) [0.0|15] ""  HUD,Kombi
 SG_ MFL_Marke : 24|4@1+ (1.0,0.0) [0.0|15] ""  HUD,Kombi
 SG_ MFL_Variante : 28|4@1+ (1,0) [0|15] ""  HUD,Kombi

BO_ 1600 Motor_07: 8 Gateway_Max
 SG_ MO_QBit_Ansaugluft_Temp : 0|1@1+ (1.0,0.0) [0.0|1] ""  Vector__XXX
 SG_ MO_QBit_Oel_Temp : 1|1@1+ (1.0,0.0) [0.0|1] ""  Vector__XXX
 SG_ MO_QBit_Kuehlmittel_Temp : 2|1@1+ (1.0,0.0) [0.0|1] ""  Kombi
 SG_ MO_KL15_Abschaltempfehlung : 3|1@1+ (1.0,0.0) [0.0|1] ""  Vector__XXX
 SG_ MO_HYB_Fehler_HV_Netz : 4|1@1+ (1.0,0.0) [0.0|1] ""  Vector__XXX
 SG_ MO_aktives_Getriebeheizen : 5|1@1+ (1.0,0.0) [0.0|1] ""  Vector__XXX
 SG_ MO_Absperrventil_oeffnen : 6|2@1+ (1.0,0.0) [0.0|3] ""  Vector__XXX
 SG_ MO_Ansaugluft_Temp : 8|8@1+ (0.75,-48) [-48.00|141.75] "Unit_DegreCelsi"  Vector__XXX
 SG_ MO_Oel_Temp : 16|8@1+ (1,-60) [-60|192] "Unit_DegreCelsi"  HUD,Kombi
 SG_ MO_Kuehlmittel_Temp : 24|8@1+ (0.75,-48) [-48.00|141.75] "Unit_DegreCelsi"  Kombi
 SG_ MO_Hoeheninfo : 32|8@1+ (0.00781,0) [0.00000|1.98374] ""  Vector__XXX
 SG_ MO_Kennfeldk : 40|1@1+ (1.0,0.0) [0.0|1] ""  Vector__XXX
 SG_ MO_Versionsinfo_02 : 41|5@1+ (1.0,0.0) [0.0|31] ""  Vector__XXX
 SG_ MO_QBit_Hoeheninfo : 46|1@1+ (1.0,0.0) [0.0|1] ""  Vector__XXX
 SG_ MO_Getriebe_kuehlen : 47|1@1+ (1.0,0.0) [0.0|1] ""  Vector__XXX
 SG_ MO_Mom_Traegheit_02 : 48|5@1+ (0.01,0) [0.00|0.31] "Unit_KiloGramMeterSquar"  Vector__XXX
 SG_ MO_Heizungspumpenansteuerung : 53|4@1+ (10,0) [0|100] "Unit_PerCent"  Vector__XXX
 SG_ MO_SpannungsAnf : 57|1@1+ (1.0,0.0) [0.0|1] ""  Vector__XXX
 SG_ MO_Nachlaufzeit_Heizungspumpe : 58|6@1+ (15,0) [0|945] "Unit_Secon"  Vector__XXX

BO_ 1607 Motor_09: 8 Gateway_Max
 SG_ MO_ITM_Kuehlmittel_Temp : 0|8@1+ (0.75,-48) [-45.75|143.25] "Unit_DegreCelsi"  Kombi
 SG_ MO_E85_Sensor : 8|4@1+ (10,0) [0|100] "Unit_PerCent"  Vector__XXX
 SG_ SCR_Anz_Motorstarts : 12|4@1+ (1.0,0.0) [0.0|15] ""  Vector__XXX
 SG_ SCR_Reichweite : 16|15@1+ (1,0) [0|32766] "Unit_KiloMeter"  Vector__XXX
 SG_ MO_Ethanol_Spuelhinweis : 31|1@1+ (1.0,0.0) [0.0|1] ""  Vector__XXX
 SG_ SCR_Warnstufe_1 : 32|1@1+ (1.0,0.0) [0.0|1] ""  Vector__XXX
 SG_ SCR_Warnstufe_2 : 33|1@1+ (1.0,0.0) [0.0|1] ""  Vector__XXX
 SG_ SCR_Text : 34|3@1+ (1.0,0.0) [0.0|7] ""  Vector__XXX
 SG_ SCR_Akustik : 37|2@1+ (1.0,0.0) [0.0|3] ""  Vector__XXX
 SG_ SCR_verbaut : 39|1@1+ (1.0,0.0) [0.0|1] ""  Kombi
 SG_ MO_Kraftstofffilter_Wasser : 40|1@1+ (1.0,0.0) [0.0|1] ""  Kombi
 SG_ SCR_Systemfehler : 41|1@1+ (1.0,0.0) [0.0|1] ""  Vector__XXX
 SG_ SCR_Inducement_Strategie : 42|2@1+ (1.0,0.0) [0.0|3] ""  Vector__XXX
 SG_ MO_CO2_Faktor : 44|12@1+ (1,0) [1|4094] "Unit_GramPerLiter"  Vector__XXX
 SG_ MO_MKB_MUX M  : 56|2@1+ (1.0,0.0) [0.0|3] ""  Kombi
 SG_ MO_MKB_01 m0  : 59|5@1+ (1.0,0.0) [0.0|31] ""  Kombi
 SG_ MO_MKB_02 m1  : 59|5@1+ (1.0,0.0) [0.0|31] ""  Kombi
 SG_ MO_MKB_03 m2  : 59|5@1+ (1.0,0.0) [0.0|31] ""  Kombi
 SG_ MO_MKB_04 m3  : 59|5@1+ (1.0,0.0) [0.0|31] ""  Kombi

CM_ BO_ 2527679633 "Botschaft mit Signalen der Luftzusatzheizung";
CM_ BO_ 917 "MLB";
CM_ BO_ 1639 "MLBevo";
CM_ BO_ 1178 "ab MQB 7.2";
CM_ BO_ 956 "MLBevo";
CM_ BO_ 1171 "ab MQB 7.2 gültig";
CM_ BO_ 1600 "ab MQB mit QBit Höheneinfo und MO_Versionsinfo_02";

CM_ SG_ 1624 BCM1_Licht_Dunkelheit_aktiv "Licht aktiv aufgrund von Dunkelheit (nicht bei Autobahn-, Tagfahr- oder Regenlicht)";
CM_ SG_ 1624 BCM1_Linksverkehr "Information über Aufbauzustand des Fzg:
0 = Scheinwerfer für Rechtsverkehr
1 = Scheinwerfer für Linksverkehr";
CM_ SG_ 1624 Licht_Vorne_01_CRC "Für MLB:
'Berechnung siehe Lastenheft 'Kommunikationsabsicherung für FlexRay und CAN''

Ab MQB und MLBevo:
'Berechnung siehe Lastenheft 'End-to-End Kommunikationsabsicherung''

Endwerte siehe Begleitdokument 'S-PDU Kennungsfolgen'";
CM_ SG_ 1624 LV_Abbiegelicht_li_def "Fehlerstatus Abbiegelicht vorne links
";
CM_ SG_ 1624 LV_Abbiegelicht_re_def "Fehlerstatus Abbiegelicht vorne rechts
";
CM_ SG_ 1624 LV_Abblend_Fernlicht_li_def "Fehlerstatus Abblendlicht und Fernlicht links ";
CM_ SG_ 1624 LV_Abblend_Fernlicht_re_def "Fehlerstatus Abblendlicht und Fernlicht rechts";
CM_ SG_ 1624 LV_Abblendlicht_Anzeige "Abblendlicht aktiv";
CM_ SG_ 1624 LV_Abblendlicht_li_def "Fehlerstatus Abblendlicht vorne links 
";
CM_ SG_ 1624 LV_Abblendlicht_re_def "Fehlerstatus Abblendlicht vorne rechts
";
CM_ SG_ 1624 LV_Abblendlicht_TFL_li_def "Fehlerstatus Abblendlicht und Tagfahrlicht links
";
CM_ SG_ 1624 LV_Abblendlicht_TFL_re_def "Fehlerstatus Abblendlicht und Tagfahrlicht rechts ";
CM_ SG_ 1624 LV_AFL_aktiv_Anzeige "Anzeige AFL-Funktion";
CM_ SG_ 1624 LV_AFL_defekt "Fehlerstatus AFL
";
CM_ SG_ 1624 LV_Aussenlicht_def "Aussenlicht kann nicht mehr korrekt angesteuert werden (EEPROM Codierung kann nicht mehr ausgelesen werden)
";
CM_ SG_ 1624 LV_Blinker_li_def "Fehlerstatus Blinker vorne links
";
CM_ SG_ 1624 LV_Blinker_re_def "Fehlerstatus Blinker vorne rechts
";
CM_ SG_ 1624 LV_Blinker_VL_aktiv "Blinker vorne links
";
CM_ SG_ 1624 LV_Blinker_VR_aktiv "Blinker vorne links
";
CM_ SG_ 1624 LV_Blk_li_Seite_def "Fehlerstatus Seitenblinker links
";
CM_ SG_ 1624 LV_Blk_re_Seite_def "Fehlerstatus Blinker Seite rechts
";
CM_ SG_ 1624 LV_Fernlicht_Anzeige "Fernlicht_aktiv";
CM_ SG_ 1624 LV_Fernlicht_li_def "Fehlerstatus Fernlicht vorne links
";
CM_ SG_ 1624 LV_Fernlicht_re_def "Fehlerstatus Fernlicht vorne rechts
";
CM_ SG_ 1624 LV_FLA_aktiv_Anzeige "Ansteuerung FLA-Lampe im Kombi (BCM1 Bedienmaster)";
CM_ SG_ 1624 LV_FLA_defekt "Fehlerstatus FLA (Anzeige des entsprechenden Fehlertext im Kombi)";
CM_ SG_ 1624 LV_FLA_Sensor_blockiert "Status FLA-Sensor (Anzeige des entsprechenden Fehlertext im Kombi)";
CM_ SG_ 1624 LV_LED_Scheinwerfer_li_def "Fehlerstatus LED-Scheinwerfer links
";
CM_ SG_ 1624 LV_LED_Scheinwerfer_re_def "Fehlerstatus LED-Scheinwerfer rechts";
CM_ SG_ 1624 LV_MXB_Status_Anzeige "Aktueller Status des Fernlichts / MxB zur Signalisierung im Kombi.";
CM_ SG_ 1624 LV_Nebellicht_Anzeige "Nebellicht_aktiv
";
CM_ SG_ 1624 LV_Nebellicht_li_def "Fehlerstatus Nebelscheinwerfer vorne links
";
CM_ SG_ 1624 LV_Nebellicht_re_def "Fehlerstatus Nebelscheinwerfer vorne rechts
";
CM_ SG_ 1624 LV_Nebellicht_TFL_li_def "Fehlerstatus Nebellicht und Tagfahrlicht links ";
CM_ SG_ 1624 LV_Nebellicht_TFL_re_def "Fehlerstatus Nebellicht und Tagfahrlicht rechts";
CM_ SG_ 1624 LV_Nebelschlusslicht_Anzeige "Nebelschlusslicht_aktiv
";
CM_ SG_ 1624 LV_Standlicht_Anzeige "Anzeige Standlicht
";
CM_ SG_ 1624 LV_Standlicht_li_def "Fehlerstatus Standlicht vorne links
";
CM_ SG_ 1624 LV_Standlicht_re_def "Fehlerstatus Standlicht vorne rechts
";
CM_ SG_ 1624 LV_Standlicht_TFL_li_def "Fehlerstatus Standlicht und Tagfahrlicht links ";
CM_ SG_ 1624 LV_Standlicht_TFL_re_def "Fehlerstatus Standlicht und Tagfahrlicht rechts ";
CM_ SG_ 1624 LV_Tagfahrlicht_Anzeige "Anzeige Tagfahrlicht
";
CM_ SG_ 1624 LV_Tagfahrlicht_li_def "Fehlerstatus Tagfahrlicht links
";
CM_ SG_ 1624 LV_Tagfahrlicht_re_def "Fehlerstatus Tagfahrlicht rechts";

CM_ SG_ 2463978598 LoGeWa_C2C_Anf_Audioabsenkung "Anforderung der Audioabsenkung im Infotainment, aufgrund empfangener Car-2-Car Nachricht (z.B. SonderEinsatzFahrzeuge)";
CM_ SG_ 2463978598 LoGeWa_C2C_Event_Einheit "Einheit der Entfernung des Events für Kombianzeige von Car2Car";
CM_ SG_ 2463978598 LoGeWa_C2C_Event_Entfernung "Entfernung des Events für Kombianzeige von Car2Car";
CM_ SG_ 2463978598 LoGeWa_C2C_Event_Richtung "Richtung des Events für Kombianzeige von Car2Car";
CM_ SG_ 2463978598 LoGeWa_C2C_Event_Status "Status der Anzeige des Events für Kombianzeige von Car2Car";
CM_ SG_ 2463978598 LoGeWa_C2C_Event_Warnung "Typ des Events für Kombianzeige von Car2Car";

CM_ SG_ 822 LR_HZG_Konfiguration "Konfiguration der Heizmatte der Lenkradheizung";
CM_ SG_ 822 LR_HZG_Taster_on_off "Anforderung des Schalters am MFL: Lenkradheizung aus/ein
(Regelung der LR_HZG ist im SMLS)";
CM_ SG_ 822 LR_HZG_Temp_Sensor "Temperaturwert Lenkradheizung";

CM_ SG_ 2527679633 LSH_Ansaug_Fuell_1 "Luftstandheizungsansaugtemperaturfühler 1";
CM_ SG_ 2527679633 LSH_Ansaug_Fuell_2 "Luftstandheizungsansaugtemperaturfühler 2";
CM_ SG_ 2527679633 LSH_Empf_Heizstufe "Heizstufen";
CM_ SG_ 2527679633 LSH_Funk_aus "LSH über Funksignal ausschalten";
CM_ SG_ 2527679633 LSH_Funk_ein "LSH über Funksignal einschalten";
CM_ SG_ 2527679633 LSH_Geblaese_aktiv "Anzeige der Luftstandheizung, dass das interne Gebläse aktiv ist.
0 = Gebläse inaktiv
1 = Gebläse aktiv";
CM_ SG_ 2527679633 LSH_Heiztemp "Luftheizungswärmetauschertemperatur";
CM_ SG_ 2527679633 LSH_Klappe_Status "Status Luftklappe";
CM_ SG_ 2527679633 LSH_LED "Funktionslampe Luftstandheizung";
CM_ SG_ 2527679633 LSH_Servicemode "Luftstandheizung Servicemode";
CM_ SG_ 2527679633 LSH_Start_folgt "Thema Start/Stop: Im Stop-Modus muß das KBT einen Wiederstart anfordern, da ein STH-Start notwendig ist.";
CM_ SG_ 2527679633 LSH_Texte "Anforderung der untersch. Anzeigetexte im Mitteldisplay d. Kombi.

0: Keine Anzeige
1: Kein Standheizungsbetrieb wegen Batteriemanagementeinschränkung
2: Kein Standheizungsbetrieb wegen Kraftstoffmangels
3: Kein Standheizungsbetrieb wegen internem Sy";
CM_ SG_ 2527679633 LSH_Waermeeintrag "Signal enthält die Brenndauer der Luftstandheizung in 5min-Schritten";

CM_ SG_ 2527679634 LSH_Fehlerstatus "Fehlerstatus Luftstandheizung";
CM_ SG_ 2527679634 LSH_Heizleistung "Heizleistung in %";
CM_ SG_ 2527679634 LSH_KL_DBetr_Anf "Sicherheitsabfrage der Luftstandheizung, ob Dauerstandheizbetrieb wirklich gestartet werden soll.
Bestätigungsbit für Anforderung KL_LSH_DBetr_Ein";
CM_ SG_ 2527679634 LSH_KVS "Kraftstoffverbrauch";
CM_ SG_ 2527679634 LSH_KVS_Ueberlauf "Kraftstoffverbrauch Ueberlauf";
CM_ SG_ 2527679634 LSH_Zuheizen "Rückmeldung von der Luftstandheizung, dass das Gerät im Zuheizbetrieb ist.";

CM_ SG_ 917 AFS_Abbiegelicht_Dimm_Anf "Beschreibt ob das Abbiegelicht gedimmt oder hart einschalten werden soll. Dimmkurve ist Empfänger hinterlegt.";
CM_ SG_ 917 AFS_Abbiegelicht_li_Anf "Anforderung das Abbiegelicht links einzuschalten";
CM_ SG_ 917 AFS_Abbiegelicht_re_Anf "Anforderung das Abbiegelicht rechts einzuschalten";
CM_ SG_ 917 AFS_adaptive_LV_verbaut "Verfügbarkeit der adaptiven Lichtverteilung im AFS-SG.
(Das BCM steuert mit diesem Signal die Einblendung des entsprechenden Menüs)";
CM_ SG_ 917 AFS_Allwetterlicht "Status ¿Allwetterlicht¿ - Licht für schlechte Sichtverhältnisse
(bei Defekt -> nicht aktiv)";
CM_ SG_ 917 AFS_Charisma_FahrPr "MLBevo: Aktuelles Fahrprogramm des Charisma-Teilnehmers (siehe Systemlastenheft Drive Select)
MQB: Istwert der Kennlinie (siehe Systemlastenheft MQB FPA)";
CM_ SG_ 917 AFS_Charisma_Status "Charisma Systemstatus des Charisma-Teilnehmers

Wert 0x3 ist nur für Fahrzeuge ab MQB relevant";
CM_ SG_ 917 AFS_Ersatzlicht_Links "Bei aktivierter Ersatzlichtfunktion wird das Abblendlicht ausgeschaltet und eine Ersatzlichtquelle eingeschaltet (z.Zt. B7)";
CM_ SG_ 917 AFS_Ersatzlicht_Rechts "Bei aktivierter Ersatzlichtfunktion wird das Abblendlicht ausgeschaltet und eine Ersatzlichtquelle eingeschaltet (z.Zt. B7)";
CM_ SG_ 917 AFS_Fehlertext "Fehlertext wird im Kombi angezeigt (z.Zt nur bei VW)";
CM_ SG_ 917 AFS_Fernlicht_li_defekt "Beschreibt ob das Fernlicht des linken Scheinwerfers defekt ist";
CM_ SG_ 917 AFS_Fernlicht_re_defekt "Beschreibt ob das Fernlicht des rechten Scheinwerfers defekt ist";
CM_ SG_ 917 AFS_Fernlicht_Status "Beschreibt ob das Fernlicht aktiv oder inaktiv ist";
CM_ SG_ 917 AFS_Lampe "Status der Fehlerlampe: aktuell anliegender Fehlerzustand des dynamischen oder statischen Kurvenlichtes";
CM_ SG_ 917 AFS_LED_Blinkmode "Lampe soll im Warnfall mit 1Hz blinken, wenn das Bit gesetzt ist (z.Zt nur bei VW)";
CM_ SG_ 917 AFS_Status_adaptive_LV "Gibt den Status der adaptiven Lichtverteilung an";
CM_ SG_ 917 AFS_Verfuegbarkeit_GLW "Beschreibt die Verfügbarkeit der Gleitenden Leuchtweite / Fernlichtassistenz - Verfügbarkeit bedeutet, dass die Funktion Gleitende Leuchtweite möglich ist";
CM_ SG_ 917 GLW_Sensor_blockiert "Das Signal zeigt an, dass die Kamera zur Zeit keine Sicht hat. 
Verhalten wie Fernlichassisten. 
Weiterleitung des Signals vom BCM an das KOMBI";
CM_ SG_ 917 LWR_AFS_Grundeinstellung "Grundeinstellung des Abblendlichtes am Lichteinstellkasten im Service oder Bandende mit Tester erfolgt! (auch für das dynamische Kurvernlicht)";
CM_ SG_ 917 LWR_AFS_Parametrisierung "Parametrisierung wählt die Fahrzeugvariante und die AFS-Variante aus";
CM_ SG_ 917 LWR_Hoehenwert_HL "Aktueller Höhensensorwert Hinten Links
MSS LB überträgt den Aktueller Höhensensorwert Vorne Rechts.

0x7F = 0 mm";
CM_ SG_ 917 LWR_Hoehenwert_VL "Aktueller Höhensensorwert Vorne Links

0x7F = 0 mm";
CM_ SG_ 917 LWR_Initialisierungslauf "Initialisierungslauf der Schrittmotoren, erfolgt defaultmäßig beim Motorstart";
CM_ SG_ 917 LWR_Lampe "Status der Fehlerlampe: aktuell anliegender Fehlerzustand";
CM_ SG_ 917 LWR_Modus "Schnelle oder langsame Regelart der LWR";
CM_ SG_ 917 LWR_Pos_Schrittmotor "Position des Aktuators in Prozent des maximalen Stellweges; vor dem Initialisierungslauf (Motorstart) wird der Initwert ausgegeben: 
0% : tiefste Stellung (auf Block) des Schrittmotors;
100% : maximaler Verstellweg des Schrittmotors (nicht die Grenze de";
CM_ SG_ 917 LWR_Reisemodus_Texte "Anzeige der eingestellten Verkehrsart bei aktivem Touristenlicht";
CM_ SG_ 917 LWR_Sicherheitsposition "LWR Sicherheitsposition beider Scheinwerfers";
CM_ SG_ 917 LWR_Touristenmodus_aktiv "Über MMI sendet BCM1 eine Anforderung Touristenmodus an die LWR. Diese sendet als Rückmeldung an BCM1, dass der Touristenmodus aktiv geschaltet wurde";
CM_ SG_ 917 LWR_Touristenmodus_verbaut "Verfügbarkeit der Touristenfunktion im AFS/LWR-SG.
(Das BCM steuert mit diesem Signal die Einblendung des entsprechenden Menüs)";

CM_ SG_ 1153 DSSS_Warning "DSSS - Driving Safety Support System Meldungen";
CM_ SG_ 1153 MIB_ASW_Diagnose "Diagnose Rückmeldung vom MIB zu Heckradar Entry. ASW Warnton Verfügbarkeit.";
CM_ SG_ 1153 MIB_Tongenerator_PH_verfuegbar "Verfügbarkeit des Tongenerators im MIB für die Nutzung durch die Parkhilfe";
CM_ SG_ 1153 MMI_Counter_Bedienevent "Signal wird inkrementiert, wenn Bedienevent stattgefunden hat.";
CM_ SG_ 1153 MMI_Gurt_Mic_ref "Referenzsignal für das Gurtmikrofon Steuergerät zur Signalisierung ob der Downlink aktiv oder inaktiv ist";
CM_ SG_ 1153 MMI_SDS_aktiv "Signal wird gesetzt, solange die Sprachbedienung aktiv ist.";
CM_ SG_ 1153 MU_SecondDisplay "Dient zur Überwachung der zweiten LVDS Leitung.";
CM_ SG_ 1153 MU_Update_Time "Ermöglicht auslesen der Historiendaten, wann ein Update lief";
CM_ SG_ 1153 Nav_FoD_Status "FoD Status der Navigation";
CM_ SG_ 1153 ZR_AppConnect_Zustand "Ist Zustand des AppConnect Kontextes im MIB";
CM_ SG_ 1153 ZR_Kindersicherung_RSE "Sperren der Rearseat Unit (Komplette Weckfähigkeit)";
CM_ SG_ 1153 ZR_Lichter_Tag "Berechnete Kennzeichnung des Sonnenstandes über bzw. oder unter Horizont.";
CM_ SG_ 1153 ZR_LoGeWa_Event_Kombiwarnung "Event für Kombiwarnung";
CM_ SG_ 1153 ZR_Parken_Sondermodus "Rückkanal zum pilotierten Parken zur Signalisierung Status Sondermodus";
CM_ SG_ 1153 ZR_RSE_aktivieren "Weckfähigkeit der RSE";
CM_ SG_ 1153 ZR_Sta_Inszenierung "MIB sendet Status über Inszenierungssound (welcome sound) an BCM1
Zweck: Synchronisierung mit weiteren Teilnehmern der Startupinszenierung";

CM_ SG_ 1639 BFS_Fond_Bed_Ack "Bestätigung Beifahrersitzverstellung vom Fond";
CM_ SG_ 1639 BFS_FSV_ausgeklappt "Zustandssignalisierung der el. mech. Fußstütze (eingeklappt oder ausgeklappt)";
CM_ SG_ 1639 BFS_GHV_aktiv "Verstellung Gurthoehe
";
CM_ SG_ 1639 BFS_Gurtbringer_Sperre "Freigabesignal für den Gurtzubringer";
CM_ SG_ 1639 BFS_Klappfunktion_Aktiv "Lehnenklappung aktiv";
CM_ SG_ 1639 BFS_Klappfunktion_Bed_Ack "Bestätigung Beifahrersitzklappung vom Beifahrersitz";
CM_ SG_ 1639 BFS_Klappfunktion_Beschraenkung "Signalisiert eine Verstelleinschränkung des Beifahrersitz  (für BAP Visualisierung)";
CM_ SG_ 1639 BFS_Klappfunktion_Status "dient der Signalisierung für eine Verstelleinschränkung, da der Sitz sich in Ruhestellung befindet.";
CM_ SG_ 1639 BFS_Klapptisch_offen "Signalisiert eine Verstelleinschränkung des Beifahrersitz  (für BAP Visualisierung)";
CM_ SG_ 1639 BFS_KSS_Fahrt_aktiv "Komfortseitensichtfahrt (BFS)";
CM_ SG_ 1639 BFS_KSV_aktiv "Kopfstuetzenverstellung BFS
";
CM_ SG_ 1639 BFS_Lehne_nicht_verriegelt "Fahrer Sitz Lehne Verstellung Verriegelt Status

Verwendung nur im  Bentley";
CM_ SG_ 1639 BFS_LHV_aktiv "Verstellung Lordose Höhe
";
CM_ SG_ 1639 BFS_LKV_aktiv "Verstellung Lehnenkopf
";
CM_ SG_ 1639 BFS_LNV_aktiv "Verstellung Lehnenneigung
";
CM_ SG_ 1639 BFS_LWV_aktiv "Lordose W Verstellung
";
CM_ SG_ 1639 BFS_MMB_glob_stop "Abbruch Memoryverstellung";
CM_ SG_ 1639 BFS_MMB_lokal_Stop "mit dem lokal Stop moechte man, dass ein Sitz mit Pneumatik - Lordose sich im Memoryfall wie ein Sitz mit elektromechanischer Lordose verhaelt. Nur lokler Abbruch im TIP-Betrieb.";
CM_ SG_ 1639 BFS_MMB_storage "Speichern auf Memoryposition";
CM_ SG_ 1639 BFS_MMB_storage_beep "Quittierungston Sitzmemory BFS (Anforderung Kombi)

";
CM_ SG_ 1639 BFS_MMB_store "Speichern der Sitzposition
";
CM_ SG_ 1639 BFS_MMB_store_LED_on "LED für Speichern
";
CM_ SG_ 1639 BFS_MMB_tast "Memoryverstellung im Tastbetrieb";
CM_ SG_ 1639 BFS_MMB_tipp "Memoryverstellung im Tippbetrieb";
CM_ SG_ 1639 BFS_Ruhestellung_Status "dient der Signalisierung für eine Verstelleinschränkung, da der Sitz sich in Ruhestellung befindet.";
CM_ SG_ 1639 BFS_Seat_Locked "Anzeige des gesperrten Beifahrersitzes aufgrund ungültiger Sitzposition.";
CM_ SG_ 1639 BFS_SHV_aktiv "Sitzhöhenverstellung
";
CM_ SG_ 1639 BFS_Sitzfahrt_aktiv "Aktive Sitzfahrt";
CM_ SG_ 1639 BFS_Sitzsym_Fahrt_aktiv "Sitzsymetriefahrt
";
CM_ SG_ 1639 BFS_SLV_aktiv "Sitzlängsverstellung
";
CM_ SG_ 1639 BFS_SNV_aktiv "Verstellung Sitzneigung
";
CM_ SG_ 1639 BFS_STV_aktiv "Sitztiefeverstellung
";
CM_ SG_ 1639 Mem_BFS_01_BZ "4bit Botschaftszähler, wird mit jeder Sendebotschaft inkrementiert";
CM_ SG_ 1639 Mem_BFS_01_CRC "Für MLB:
Berechnung siehe Lastenheft 'Kommunikationsabsicherung für FlexRay und CAN'
Ab MQB und MLBevo:
Berechnung siehe Lastenheft 'End-to-End Kommunikationsabsicherung'

Endwerte siehe Begleitdokument 'S-PDU Kennungsfolgen'";

CM_ SG_ 2463978884 HBFS_Anfahrt_EasyEntry "Anfahren der EasyEntry-Positionen HBFS";
CM_ SG_ 2463978884 HBFS_Anfahrt_Klappfunktion "Anfahren der Klappfunktionsposition";
CM_ SG_ 2463978884 HBFS_Anfahrt_Komfortposition "Anfahren der Komfort-Positionen HBFS";
CM_ SG_ 2463978884 HBFS_EasyEntry_Aktiv "Aktive EasyEntry fahrt";
CM_ SG_ 2463978884 HBFS_EasyEntry_Beschraenkung "Beschränkung einer EasyEntry-Fahrt";
CM_ SG_ 2463978884 HBFS_EasyEntry_Status "Status EasyEntry";
CM_ SG_ 2463978884 HBFS_Fahrposition "Fahrposition oder Ladeposition rechts";
CM_ SG_ 2463978884 HBFS_Klappfunktion_Aktiv "Lehnenklappung aktiv";
CM_ SG_ 2463978884 HBFS_Klappfunktion_Beschraenkung "Dient zur Darstellung von Vor- / Abbruchbedingungen der Klappfunktion";
CM_ SG_ 2463978884 HBFS_Klappfunktion_Status "Längsverstellung vor (Wird bei Rechtslenker vom TSG HL gesendet)";
CM_ SG_ 2463978884 HBFS_Komfortposition_Aktiv "Aktive Komfortpositionsfahrt";
CM_ SG_ 2463978884 HBFS_Komfortposition_Beschraenku "Beschränkung einer Komfortpositionsfahrt";
CM_ SG_ 2463978884 HBFS_Komfortposition_Status "Status Komfortposition";
CM_ SG_ 2463978884 HBFS_Kopfst_unten "Kopfstütze unten rechts";
CM_ SG_ 2463978884 Mem_BFS_Fond_02_BZ "4bit Botschaftszähler, wird mit jeder Sendebotschaft inkrementiert";
CM_ SG_ 2463978884 Mem_BFS_Fond_02_CRC "Für MLB:
Berechnung siehe Lastenheft 'Kommunikationsabsicherung für FlexRay und CAN'
Ab MQB und MLBevo:
Berechnung siehe Lastenheft 'End-to-End Kommunikationsabsicherung'

Endwerte siehe Begleitdokument 'S-PDU Kennungsfolgen'";
CM_ SG_ 2463978884 Mem_BFSFo_Warn_Dreh_entriegelt "Notentriegelung BFSFo
Lehnenneigung falsch BFSFo
Kissenneigung falsch BFSFo";
CM_ SG_ 2463978884 Mem_BFSFo_Warn_Verriegelung "Sitzdrehung hinten rechts";
CM_ SG_ 2463978884 Mem_HBFS_Seat_Attention "HMI Warnmeldung für unzulässige Sitzpositionen MCC";
CM_ SG_ 2463978884 Zielpositio_Hoeh_BFS_fur_EA_HBFS "Zielposition_Hoeh_FS_fur EA_HFS";

CM_ SG_ 2463978889 Mem_BFS_Fond_03_BZ "4bit Botschaftszähler, wird mit jeder Sendebotschaft inkrementiert";
CM_ SG_ 2463978889 Mem_BFS_Fond_03_CRC "Für MLB:
Berechnung siehe Lastenheft 'Kommunikationsabsicherung für FlexRay und CAN'
Ab MQB und MLBevo:
Berechnung siehe Lastenheft 'End-to-End Kommunikationsabsicherung'

Endwerte siehe Begleitdokument 'S-PDU Kennungsfolgen'";
CM_ SG_ 2463978889 Mem_HBFSFo_Abschaltanf_SRAB "Lehnenwinkel SRAB HBFS";
CM_ SG_ 2463978889 Mem_HBFSFo_Anzeige_Komfort_HBFS "Meldung Komfortposition überschritten HBFS";
CM_ SG_ 2463978889 Mem_HBFSFo_ARMTuer_aktiv "Verstellung Armlehne Tuer";
CM_ SG_ 2463978889 Mem_HBFSFo_ARMTunnel_aktiv "Verstellung Armlehne  Tunnel";
CM_ SG_ 2463978889 Mem_HBFSFo_BANV_aktiv "Verstellung Beinauflageneigung";
CM_ SG_ 2463978889 Mem_HBFSFo_BATV_aktiv "Verstellung Beinauflagentiefe";
CM_ SG_ 2463978889 Mem_HBFSFo_EE_Entriegl_Motor "EasyEntry Entriegelungsmotor rechts";
CM_ SG_ 2463978889 Mem_HBFSFo_EE_Verr_Sensor_re "EasyEntry Verriegelungssensor rechts außen";
CM_ SG_ 2463978889 Mem_HBFSFo_globaler_Lehnenwinkel "globaler Lehnenwinkel HBFS";
CM_ SG_ 2463978889 Mem_HBFSFo_globaler_Sitzflachenw "globaler Sitzflächenwinkel HBFS";
CM_ SG_ 2463978889 Mem_HBFSFo_KSV_aktiv "Verstellung Kopfstütze";
CM_ SG_ 2463978889 Mem_HBFSFo_LED_EA_Taster "EasyEntry Taster rechts LED Rotanzeige";
CM_ SG_ 2463978889 Mem_HBFSFo_LKV_aktiv "Verstellung Lehnenkopf";
CM_ SG_ 2463978889 Mem_HBFSFo_LNV_aktiv "Verstellung Lehnenneigung";
CM_ SG_ 2463978889 Mem_HBFSFo_SHV_aktiv "Verstellung Sitzhöhe";
CM_ SG_ 2463978889 Mem_HBFSFo_SLV_aktiv "Sitzlängsverstellung";
CM_ SG_ 2463978889 Mem_HBFSFo_SLV_hinten "SLV rechts (hinterste Position)";
CM_ SG_ 2463978889 Mem_HBFSFo_SNV_aktiv "Verstellung Sitzneigung";
CM_ SG_ 2463978889 Mem_HBFSFo_Sperre_Sitzdisplay "Aufforderung MCC4-ABT Sperre/Kindersicherung HBFS zu aktivieren, durch Betätigung Hardkey HBFS für kindgerechte Sitzposition";
CM_ SG_ 2463978889 Mem_HBFSFo_Status_Schalter_Ki_Si "Status Schalter HBFS an ZAE";
CM_ SG_ 2463978889 Mem_HBFSFo_Stoerung "Störung des HBFS-Sitz-SG an Kombi";
CM_ SG_ 2463978889 Mem_HBFSFo_STV_aktiv "Verstellung Sitztiefe";
CM_ SG_ 2463978889 Mem_HBFSFo_Verr_Sensor_oben_re "Lehne oben rechts (Verriegelung)";
CM_ SG_ 2463978889 Mem_HBFSFo_Verr_Sensor_unten_re "Lehne unten rechts (Verriegelung)";
CM_ SG_ 2463978889 Mem_HBFSFo_Warnung_Softstop "HMI Warnung nach Softstop Lehnenverstellung";

CM_ SG_ 1178 FS_BFS_Fond_Verst_enable "Verstellung Fond (vom MMI)
";
CM_ SG_ 1178 FS_BFS_KSS_Anfahrt "Komfortseitensicht Anfahrt BFS";
CM_ SG_ 1178 FS_BFS_Sitzsym_Anfahrt "Sitzsymetrie Anfahrt BFS";
CM_ SG_ 1178 FS_EE_BFS_enable "EasyEntry Freigabe für Befahrersitz.";
CM_ SG_ 1178 FS_EE_Fond_BFS_enable "EE Fond rechts

";
CM_ SG_ 1178 FS_EE_Fond_FS_enable "EE Fond links
";
CM_ SG_ 1178 FS_Fond_Bed_enable "Freigabe für Fondsitzverstellungen";
CM_ SG_ 1178 FS_GHV_aktiv "Verstellung Gurthöhe
";
CM_ SG_ 1178 FS_Gurtbringer_Sperre "Freigabesignal für den Gurtzubringer";
CM_ SG_ 1178 FS_KSV_aktiv "Verstellung Kopfstütze
";
CM_ SG_ 1178 FS_Lehne_nicht_verriegelt "Fahrer Sitz Lehne Verstellung Verriegelt Status

Verwendung nur im Bentley";
CM_ SG_ 1178 FS_LHV_aktiv "Verstellung Lordose Höhe
";
CM_ SG_ 1178 FS_LKV_aktiv "Verstellung Lehnenkopf
";
CM_ SG_ 1178 FS_LNV_aktiv "Verstellung Lehnenneigung
";
CM_ SG_ 1178 FS_LWV_aktiv "Verstellung Lordose W
";
CM_ SG_ 1178 FS_MMB_glob_stop "Abbruch Memoryverstellung";
CM_ SG_ 1178 FS_MMB_lokal_Stop "mit dem lokal Stop moechte man, dass ein Sitz mit Pneumatik - Lordose sich im Memoryfall wie ein Sitz mit elektromechanischer Lordose verhaelt. Nur lokler Abbruch im TIP-Betrieb.";
CM_ SG_ 1178 FS_MMB_storage "Memory-Positionstaste, Funkschlüssel-Memory-ID, Benutzerkonto-Nummer";
CM_ SG_ 1178 FS_MMB_storage_beep "Quittierungston Sitzmemory FS (Anforderung Kombi)";
CM_ SG_ 1178 FS_MMB_store "Memoryposition Speichern";
CM_ SG_ 1178 FS_MMB_store_LED_on "LED für Speichern
";
CM_ SG_ 1178 FS_MMB_tast "Memoryverstellung im Tastbetrieb";
CM_ SG_ 1178 FS_MMB_tipp "Memoryverstellung im Tippbetrieb";
CM_ SG_ 1178 FS_SHV_aktiv "Verstellung Sitzhöhe

";
CM_ SG_ 1178 FS_Sitzfahrt_aktiv "Aktive Sitzfahrt Fahrersitz
";
CM_ SG_ 1178 FS_SLV_aktiv "Sitzlängsverstellung
";
CM_ SG_ 1178 FS_SNV_aktiv "Verstellung Sitzneigung
";
CM_ SG_ 1178 FS_Spezialposition_anfahren "paralell zu diesem Signal wird eine Botschaft auf den KCAN gesendet in der spezielle Anforderungen für den Empfänger stehen. 
Dieses Signal dient zusätzlich der Checksummenabsicherung bei einer Remotverstellung ";
CM_ SG_ 1178 FS_STV_aktiv "Verstellung Sitztiefe
";
CM_ SG_ 1178 Mem_FS_01_MQB_BZ "4bit Botschaftszähler, wird mit jeder Sendebotschaft inkrementiert";
CM_ SG_ 1178 Mem_FS_01_MQB_CRC "Für MLB:
Berechnung siehe Lastenheft 'Kommunikationsabsicherung für FlexRay und CAN'
Ab MQB und MLBevo:
Berechnung siehe Lastenheft 'End-to-End Kommunikationsabsicherung'

Endwerte siehe Begleitdokument 'S-PDU Kennungsfolgen'";

CM_ SG_ 956 Mem_FS_Fond_01_BZ "4bit Botschaftszähler, wird mit jeder Sendebotschaft inkrementiert";
CM_ SG_ 956 Mem_FS_Fond_01_CRC "Für MLB:
Berechnung siehe Lastenheft 'Kommunikationsabsicherung für FlexRay und CAN'
Ab MQB und MLBevo:
Berechnung siehe Lastenheft 'End-to-End Kommunikationsabsicherung'

Endwerte siehe Begleitdokument 'S-PDU Kennungsfolgen'";
CM_ SG_ 956 Mem_FSFo_Business_anfahren "Befehl um Business Position an zufahren";
CM_ SG_ 956 Mem_FSFo_Lordose_hoch "Anforderung Lordosenwölbung nach oben zu verschieben.";
CM_ SG_ 956 Mem_FSFo_Lordose_runter "Anforderung Lordosenwölbung nach unten zu verschieben.";
CM_ SG_ 956 Mem_FSFo_Lordose_vor "Anforderung Lordosenwölbung pneumatisch zu vergrößern.";
CM_ SG_ 956 Mem_FSFo_Lordose_zurueck "Anforderung Lordosenwölbung zu verkleinern.";
CM_ SG_ 956 Mem_FSFo_Massage_Geschw "Weiterleitung  der gewünschten Massage Geschwindigkeit ans IVB und zugleich Anforderungsbestätigung für LEDs am Klima-SG.";
CM_ SG_ 956 Mem_FSFo_Massage_Intens "Weiterleitung  der gewünschten Massage Intensität ans IVB und zugleich Anforderungsbestätigung für LEDs am Klima-SG.";
CM_ SG_ 956 Mem_FSFo_Massage_Prg "Weiterleitung  des gewünschten Massageprogramms ans IVB und zugleich Anforderungsbestätigung für LEDs am Klima-SG.";
CM_ SG_ 956 Mem_FSFo_MMB_glob_Stop "Globaler Abbruch für automatische Funktionen";
CM_ SG_ 956 Mem_FSFo_MMB_lokal_Stop "mit dem lokal Stop moechte man, dass ein Sitz mit Pneumatik - Lordose sich im Memoryfall wie ein Sitz mit elektromechanischer Lordose verhaelt. Nur lokler Abbruch im TIP-Betrieb.";
CM_ SG_ 956 Mem_FSFo_MMB_storage "Angabe der zu speichernden oder einzustellenden Memoryposition";
CM_ SG_ 956 Mem_FSFo_MMB_storage_beep "Quittierungston Sitzmemory  (Anforderung Kombi)";
CM_ SG_ 956 Mem_FSFo_MMB_store "Aufforderung Memory-Position Mem_HL_MMB_store zu speichern";
CM_ SG_ 956 Mem_FSFo_MMB_store_LED_on "LED zur Anzeige der Speicherbereitschaft";
CM_ SG_ 956 Mem_FSFo_MMB_tast "Einstellung der Memoryposition im  Tastbetrieb";
CM_ SG_ 956 Mem_FSFo_MMB_tipp "Einstellung der Memoryposition im  Tippbetrieb";
CM_ SG_ 956 Mem_FSFo_Relax_anfahren "Befehl um Relax Position an zufahren";
CM_ SG_ 956 Mem_FSFo_Sitzfahrt_aktiv "Signalisiert eine aktive Sitzfahrt.";
CM_ SG_ 956 Mem_FSFo_Sitztiefe_vor "Anforderung Sitztiefe nach vorne zu verlängern.";
CM_ SG_ 956 Mem_FSFo_Sitztiefe_zur "Anforderung Sitztiefe nach vorne zu verlängern.";
CM_ SG_ 956 Mem_FSFo_Warn_Dreh_entriegelt "Notentriegelung FSFo
Lehnenneigung falsch FSFo
Kissenneigung falsch FSFo";
CM_ SG_ 956 Mem_FSFo_Warn_Verriegelung "Sitzdrehung hinten links";
CM_ SG_ 956 Mem_HFS_Seat_Attention "HMI Warnmeldung für unzulässige Sitzpositionen MCC";
CM_ SG_ 956 Mem_HFSFo_EA_Taster "EasyEntry Taster links";
CM_ SG_ 956 Mem_HFSFo_Unlocked "Warnmeldung Drehteller nicht verriegelt, besessen und Fahrzeug wird in Bewegung versetzt";

CM_ SG_ 2463978890 Mem_FS_Fond_03_BZ "4bit Botschaftszähler, wird mit jeder Sendebotschaft inkrementiert";
CM_ SG_ 2463978890 Mem_FS_Fond_03_CRC "Für MLB:
Berechnung siehe Lastenheft 'Kommunikationsabsicherung für FlexRay und CAN'
Ab MQB und MLBevo:
Berechnung siehe Lastenheft 'End-to-End Kommunikationsabsicherung'

Endwerte siehe Begleitdokument 'S-PDU Kennungsfolgen'";
CM_ SG_ 2463978890 Mem_HFSFo_Abschaltanf_SRAB "Lehnenwinkel SRAB HFS";
CM_ SG_ 2463978890 Mem_HFSFo_Anzeige_Komfort_HFS "Meldung Komfortposition überschritten HFS";
CM_ SG_ 2463978890 Mem_HFSFo_ARMTuer_aktiv "Verstellung Armlehne Tuer";
CM_ SG_ 2463978890 Mem_HFSFo_ARMTunnel_aktiv "Verstellung Armlehne Tunnel";
CM_ SG_ 2463978890 Mem_HFSFo_BANV_aktiv "Verstellung Beinauflageneigung";
CM_ SG_ 2463978890 Mem_HFSFo_BATV_aktiv "Verstellung Beinauflagentiefe";
CM_ SG_ 2463978890 Mem_HFSFo_EA_Position "Sitz links EA Position";
CM_ SG_ 2463978890 Mem_HFSFo_EE_Verr_Sensor_li "EasyEntry Verriegelungssensor links außen & innen";
CM_ SG_ 2463978890 Mem_HFSFo_globaler_Lehnenwinkel "globaler Lehnenwinkel HFS";
CM_ SG_ 2463978890 Mem_HFSFo_globaler_Sitzflachenwi "globaler Sitzflächenwinkel HFS";
CM_ SG_ 2463978890 Mem_HFSFo_KSV_aktiv "Verstellung Kopfstütze";
CM_ SG_ 2463978890 Mem_HFSFo_LED_EA_Taster "EasyEntry Taster links LED Rotanzeige";
CM_ SG_ 2463978890 Mem_HFSFo_LKV_aktiv "Verstellung Lehnenkopf";
CM_ SG_ 2463978890 Mem_HFSFo_LNV_aktiv "Verstellung Lehnenneigung";
CM_ SG_ 2463978890 Mem_HFSFo_SHV_aktiv "Verstellung Sitzhöhe";
CM_ SG_ 2463978890 Mem_HFSFo_SLV_aktiv "Sitzlängsverstellung";
CM_ SG_ 2463978890 Mem_HFSFo_SLV_hinten "SLV links (hinterste Position)";
CM_ SG_ 2463978890 Mem_HFSFo_SNV_aktiv "Verstellung Sitzneigung";
CM_ SG_ 2463978890 Mem_HFSFo_Sperre_Sitzdisplay "Aufforderung MCC4-ABT Sperre/Kindersicherung HFS zu aktivieren, durch Betätigung Hardkey HFS für kindgerechte Sitzposition";
CM_ SG_ 2463978890 Mem_HFSFo_Status_Schalter_Ki_Si "Status Schalter HFS an ZAE";
CM_ SG_ 2463978890 Mem_HFSFo_Stoerung "Störung des HFS-Sitz-SG an Kombi";
CM_ SG_ 2463978890 Mem_HFSFo_STV_aktiv "Verstellung Sitztiefe";
CM_ SG_ 2463978890 Mem_HFSFo_Verr_Sensor_oben_li "Lehne oben links (Verriegelung)";
CM_ SG_ 2463978890 Mem_HFSFo_Verr_Sensor_unten_li "Lehne unten links (Verriegelung)";
CM_ SG_ 2463978890 Mem_HFSFo_Warnung_Softstop "HMI Warnung nach Softstop Lehnenverstellung";

CM_ SG_ 1171 MF_Abzugssperre "Schlüsselabzugssperre";
CM_ SG_ 1171 MF_Alarm_Blinker "Taxialarmblinken, wie DWA ohne Fanfare";
CM_ SG_ 1171 MF_Alarm_Blinkertakt "Ansteuerung Blinker bei Alarm. Signal wird getaktet.
0 = Blinker für Alarm aus
1 = Blinker für Alarm ein";
CM_ SG_ 1171 MF_Anlassersperre "Notarzt 230V-Steckdose";
CM_ SG_ 1171 MF_Blk_li "Versehrte oder Fahrschule; Prio über Fernbedienung ein";
CM_ SG_ 1171 MF_Blk_re "Versehrte oder Fahrschule; Prio über Fernbedienung ein";
CM_ SG_ 1171 MF_BT_entriegeln "Beifahrertür entriegeln";
CM_ SG_ 1171 MF_BT_verriegeln "Beifahrertür verriegeln";
CM_ SG_ 1171 MF_Fahrlicht "statisch oder auch mit Blink_modi für interm.  Fahrlicht";
CM_ SG_ 1171 MF_Fernbed_ein "Fernbedienung für Petri+Lehr; Versehrte und Fahrschule";
CM_ SG_ 1171 MF_Fernlicht "Versehrte oder Fahrschule; Oder-Verknüpfung";
CM_ SG_ 1171 MF_FH_BT_hoch "Versehrte";
CM_ SG_ 1171 MF_FH_BT_tief "Versehrte";
CM_ SG_ 1171 MF_FH_FT_hoch "Versehrte";
CM_ SG_ 1171 MF_FH_FT_tief "Versehrte";
CM_ SG_ 1171 MF_Frontintervall "Versehrte oder Fahrschule; Oder-Verknüpfung";
CM_ SG_ 1171 MF_Frontwaschen "Versehrte oder Fahrschule; Oder-Verknüpfung";
CM_ SG_ 1171 MF_FT_entriegeln "Fahrertür entriegeln";
CM_ SG_ 1171 MF_FT_verriegeln "Fahrertür verriegeln";
CM_ SG_ 1171 MF_Fussraumbel "Fussraumbeleuchtung, Fahrschule";
CM_ SG_ 1171 MF_HBFS_entriegeln "Hinten Beifahrertür entriegeln";
CM_ SG_ 1171 MF_HBFS_verriegeln "Hinten Beifahrertür verriegeln";
CM_ SG_ 1171 MF_Heckintervall "Versehrte oder Fahrschule; Oder-Verknüpfung";
CM_ SG_ 1171 MF_Heckwaschen "Versehrte oder Fahrschule; Oder-Verknüpfung";
CM_ SG_ 1171 MF_HFS_entriegeln "Hinten Fahrertür entriegeln";
CM_ SG_ 1171 MF_HFS_verriegeln "Hinten Fahrertür verriegeln";
CM_ SG_ 1171 MF_Innenraumbel "sämtliche Beleuchtungen akitivieren (Fussraum, Tür u.a.)";
CM_ SG_ 1171 MF_Innenraumbel_Unterdrueck "Unterdrückung des Innenlichts/Fussraumbeleuchtung, sowie Schließblinken";
CM_ SG_ 1171 MF_interm_Fahrlicht "Ansteuerung intermittierendes Abblendlicht";
CM_ SG_ 1171 MF_interm_Fernlicht "mit Blink_modi für SoSi oder Taxialarm";
CM_ SG_ 1171 MF_interm_Takt "Taktung von intermittierenden Fernlicht/Fahrlicht bei einer Einsatzfahrt
0 = Licht aus
1 = Licht ein";
CM_ SG_ 1171 MF_Laderelais "Signal für die Auswertung zur Anzeige der Batterie-Schwach-Anzeige im Kombi";
CM_ SG_ 1171 MF_Lichthupe "Versehrte oder Fahrschule; Oder-Verknuepfung
";
CM_ SG_ 1171 MF_Motorweiterlauf "Motorstop Behoerdenfahrzeug";
CM_ SG_ 1171 MF_nachtr_Stopp_Anf "Dieses Signal dient dem Motor als Trigger, dass ein nachträglicher Motorstopp eingeleitet werden kann, wenn es die Bedingungen des StSt Koordinators dies zulassen.";
CM_ SG_ 1171 MF_Notstart "Signal zeigt an, dass ein Notstart über DBMC erfolgte.

Verwendung in Verbindung mit Signal MF_Variante = DBMC.";
CM_ SG_ 1171 MF_Schluessel_scan "Anforderung eines Innenraumscans - Schlüsselsuche";
CM_ SG_ 1171 MF_Signalhorn "Versehrte, Fahrschule oder Taxi (bei Alarm)";
CM_ SG_ 1171 MF_Standlicht "statisch oder auch mit Blink_modi für Taxialarm";
CM_ SG_ 1171 MF_StartStopp_Info "Stopp-Freigabe und Start-Anforderung an den Start-Stopp-Koordinator";
CM_ SG_ 1171 MF_Summer "Warnsummer für Funkhauptschalter und Fahrschulpedal";
CM_ SG_ 1171 MF_TFL_Abschaltung "Abschaltung des Tagfahrlicht
0 = keine Auswirkung
1 = Tagfahrlicht deaktiviert";
CM_ SG_ 1171 MF_Tippwischen "Versehrte oder Fahrschule; Oder-Verknüpfung";
CM_ SG_ 1171 MF_Tuerentriegelung_hinten "Bei von innen verriegelten Fahrzeug Türen hinten entriegeln
0 = keine Auswirkung
1 = Türen hinten entriegeln
";
CM_ SG_ 1171 MF_Variante "Sonderfahrzeugvariante
0 = keine Sonderfunktion 
1 = Sondersignalfahrzeug
2 = Taxi 
3 = Fahrhilfe 
4 = Fahrschule+Extra 
5 = SSF
6 =  DBMC
7 = Arbeitsmaschine";
CM_ SG_ 1171 MF_Warnblinker "Versehrte";
CM_ SG_ 1171 MF_Wischerstufe_1 "Versehrte oder Fahrschule; Oder-Verknüpfung";
CM_ SG_ 1171 MF_Wischerstufe_2 "Versehrte oder Fahrschule; Oder-Verknüpfung";
CM_ SG_ 1171 MF_ZV_Lock "Verriegelungsanforderung durch MFG analog Meldung einer Locktasterbetätigung durch TSG.";
CM_ SG_ 1171 MFG_01_BZ "4bit Botschaftszähler, wird in jeder Sendebotschaft inkrementiert
";
CM_ SG_ 1171 MFG_01_CRC "Für MLB:
'Berechnung siehe Lastenheft 'Kommunikationsabsicherung für FlexRay und CAN''

Ab MQB und MLBevo:
'Berechnung siehe Lastenheft 'End-to-End Kommunikationsabsicherung''

Endwerte siehe Begleitdokument 'S-PDU Kennungsfolgen'";

CM_ SG_ 1165 MF_ADR_Anforderung "Anforderung der Arbeitsdrehzahlanhebung";
CM_ SG_ 1165 MF_ADR_Fahrpedalsperre "Aktivierung der Fahrpedalsperre";
CM_ SG_ 1165 MF_ADR_neg_Rampe "Gradient Abschaltung ADR";
CM_ SG_ 1165 MF_ADR_pos_Rampe "Gradient Drehzahl Einschaltung ADR";
CM_ SG_ 1165 MF_ADR_Solldrehzahl "Solldrehzahl der Arbeitsdrehzahlregelung";
CM_ SG_ 1165 MF_MFSS_aktiv "Status der Funktion Motor-Fern-Start-Stopp";
CM_ SG_ 1165 MF_MFSS_kodiert "MFG/ KFG zeigt Kodierstatus auf MFSS";
CM_ SG_ 1165 MF_VBEG_Anforderung "Anforderung Geschwindigkeitsbegrenzung";
CM_ SG_ 1165 MF_VBEG_Geschwindigkeit "Geschwindigkeitsbegrenzung KFG";
CM_ SG_ 1165 MFG_02_BZ "Botschaftszähler";
CM_ SG_ 1165 MFG_02_CRC "Für MLB:
'Berechnung siehe Lastenheft 'Kommunikationsabsicherung für FlexRay und CAN''

Ab MQB und MLBevo:
'Berechnung siehe Lastenheft 'End-to-End Kommunikationsabsicherung''

Endwerte siehe Begleitdokument 'S-PDU Kennungsfolgen'

Kennungsfolge:";
CM_ SG_ 1165 MFG_Heizstufe_LSH "Vom Klimabedienteil gesendete Heizstufe der Luftstandheizung";
CM_ SG_ 1165 MFG_Status_SREG "Über das Signal wird dem Motorsteuergerät der Freischaltstatus der Funktion Stand Regeneration (SREG) übermittelt.";
CM_ SG_ 1165 MFG_Taster_SREG "Über den Taster SREG wird die Funktion im MSG aktiviert. Ein fehlerhafter Schaltzustand wird berücksichtigt";
CM_ SG_ 1165 MFG_Taster_VREG "Über den Taster VREG wird die Funktion im MSG aktiviert. Ein fehlerhafter Schaltzustand wird berücksichtigt";
CM_ SG_ 1165 MFG_Zuheizer_Freigabe "Freigabe Zuheizer";

CM_ SG_ 1164 MF_2BatSOCzugering "Anzeige bei geringer Ladung der Zweitbatterie";
CM_ SG_ 1164 MF_2BattAb "Batterie Ab Warnung der Zweitbatterie";
CM_ SG_ 1164 MF_2BattHlkAnf "Anforderung einer HLK - Stufe an das BEM";
CM_ SG_ 1164 MF_2BattLadWarn "Anzeige das bei Motorlauf die Zweitbatterie entladen wird im KI";
CM_ SG_ 1164 MF_2BattLlaAnf "Anforderung einer Drehzahlanhebung an das BEM";
CM_ SG_ 1164 MF_2BattSpannungsAnf "Mindestspannugnsanforderung der Zusatbatterie an den BEM";
CM_ SG_ 1164 MF_Batteriediagnose "Erstellt für Zusatzbatterie Crafter";
CM_ SG_ 1164 MF_Blinker_L_Sta "Status Blinker links Sonderaufbauten";
CM_ SG_ 1164 MF_Blinker_R_Sta "Status Blinker rechts Sonderaufbauten";
CM_ SG_ 1164 MF_ExterneLadungWarn "Warnung bei Motorlauf das externer Ladestecker gesteckt ist im KI";
CM_ SG_ 1164 MF_Fahrerhinweis "Fahrerhinweis Kombiinstrument";
CM_ SG_ 1164 MF_Generatordiagnose "Neu erstellt für Crafter";
CM_ SG_ 1164 MF_Heck_entriegeln "Entriegelung Heck über KFG";
CM_ SG_ 1164 MF_Heck_verriegeln "Verriegelung Heck über KFG";
CM_ SG_ 1164 MF_interm_Nebelscheinwerfer "Intermittierender Nebelscheinwerfer bei einer Einsatzfahrt";
CM_ SG_ 1164 MF_Lampenausfall "Meldung Lampenausfall Aufbauhersteller";
CM_ SG_ 1164 MF_LSH_Abschaltstufe "Abschaltstufen der Luftstandheizung an der Zweitbatterie. Das Signal dient der Steuerung des Klima SG an der ersten Batterie und der LSH an der zweiten Batterie durch das Zweitbatterie Em im KFG";
CM_ SG_ 1164 MF_LSH_Einschaltverbot "Statussignal für das Einschaltverbot der Luftstandheizung an der Zweitbatterie, Steuerung durch das Zweitbatterie EM im KFG.
0 volle Verfuegbarkeit Standheizung/-lueftung
1 Standheizung/-lueftung nicht aktivierbar";
CM_ SG_ 1164 MF_LSH_Zielzeit "Definition der Zielzeit für die Luftstandheizung an der zweiten Batterie, Steuerung durch das Zweitbatterie EM im KFG.";
CM_ SG_ 1164 MF_NotStartAktiv "Anzeige Notstart Aktiv für den Zeitraum der Schließung des Notstartrelais";
CM_ SG_ 1164 MF_Radiomute "Wird bei Sonderfahrzeugen wie Polizei dafür verwendet, um das Radio bei einem eingehenden Funkspruch zu muten.";
CM_ SG_ 1164 MF_Relais_2_Batterie "Zeigt den Zustand des vom KFG angesteuerten Laderelais einer verbauten 2. Batterie an";
CM_ SG_ 1164 MF_Tuerverriegelung_hinten "Internes Verriegeln der hinteren Türen";
CM_ SG_ 1164 MF_ZV_Unlock "Globales entriegeln über KFG";
CM_ SG_ 1164 MFG_AppConnect_Anf "AppConnect Anforderung durch das KFG";
CM_ SG_ 1164 MFG_Infotainment_Autark "Das Signal gibt an ob die Energieversorgung für ein Infotainment im Fahrzeug Autarkbetrieb sichergestellt ist";
CM_ SG_ 1164 MFG_Klappe_Status "Einstellung der Luftklappenposition an der Luftstandheizung";
CM_ SG_ 1164 MFG_LSH_Ansteuerung "Ansteuerung LSH";
CM_ SG_ 1164 MFG_LSH_Betriebsdauer "Betriebsdauer LSH";
CM_ SG_ 1164 MFG_LSH_DBetr_Bestaet "Bestätigung des KFGs an die LSH, dass Dauerbetrieb tatsächlich angefordert ist.";
CM_ SG_ 1164 MFG_LSH_DBetr_Ein "Dauerbetrieb der Luftstandheizung Ein";

CM_ SG_ 2463978883 MF_DCDC_Istmodus "aktuelle Betriebsart des NV DC/DC Wandlers";
CM_ SG_ 2463978883 MF_Fahrerhinweis_2 "Fahrerhinweis Kombiinstrument für Camperfunktionen";
CM_ SG_ 2463978883 MF_I_U_VorgabeZwang "Ladestrom und Spannungsvorgabe sind als Zwangsvorgaben der Zusatzbatterie zu behandeln";
CM_ SG_ 2463978883 MF_U2Batt "Spannung der Zweitbatterie";
CM_ SG_ 2463978883 MF_UBattVorgabe "Ladespannungsempfehlung Zusatz Batterie";
CM_ SG_ 2463978883 MF_Vorfeldbel_Spiegel "Schaltet die Vorfeldbeleuchtung der Außenspiegel";

CM_ SG_ 1471 MFL_Eventcode_1 "Siehe Q-LAH MFL-Protokoll";
CM_ SG_ 1471 MFL_Eventcode_2 "Siehe Q-LAH MFL-Protokoll";
CM_ SG_ 1471 MFL_Marke "Marke für markenspezifische Variantennummer des MFL";
CM_ SG_ 1471 MFL_Tastencode_1 "Beschreibt die Funktion einer fest zugeordneten Taste/Walze auf dem MFL. Bei Betätigung ändert sich der Wert von 0x0 auf den jeweiligen Tastencode.";
CM_ SG_ 1471 MFL_Tastencode_2 "Beschreibt die Funktion einer fest zugeordneten Taste/Walze auf dem MFL. Ist MFL_Tastencode_1 wegen Betätigung einer Taste/Walze bereits mit einem Wert ungleich 0x0 belegt, so ändert sich bei Betätigung einer weiteren Taste/Walze der Wert dieses Signals v";
CM_ SG_ 1471 MFL_Variante "Markenspezifische Variantennummer des MFL";

CM_ SG_ 1600 MO_Absperrventil_oeffnen "Signal an Klima-SG das Absperrrventil anzusteuern. Ab D4 auch 0x3 Ventil_schließen.

Im MQB wird hier der Soll-Status des Absperrventils ausgegeben.
Achtung: bei z. B. klemmendem Ventil entspricht das Signal nicht dem tatsächlichen Status!";
CM_ SG_ 1600 MO_aktives_Getriebeheizen "Information für Getriebe, ob ein Ventil für Getriebheizen angesteuert werden muss";
CM_ SG_ 1600 MO_Ansaugluft_Temp "In Fahrzeugen ohne Außentemperatur vom Kombi kann aus der Ansauglufttemperatur auf die Außentemperatur geschlossen werden. Beim SDI ist das mit einer gewissen Genauigkeit gegeben. Genutzt wird es vom ASG.";
CM_ SG_ 1600 MO_Getriebe_kuehlen "Anforderung Getriebekühlventilansteuerung";
CM_ SG_ 1600 MO_Heizungspumpenansteuerung "Anforderung Heizungspumpenansteuerung
MQB und Hybrid: Status der Heizungsunterstützungspumpe am MSG
";
CM_ SG_ 1600 MO_Hoeheninfo "Korrekturfaktor Höhe (1 entspricht 1013 mbar)";
CM_ SG_ 1600 MO_HYB_Fehler_HV_Netz "Im HV-Bordnetz ist fehlerbedingt kein generatorischer Betrieb möglich. Das 12V-Bordnetz wird über den DC/DC-Wandler allein aus der Traktionsbatterie gespeist. Um diesen Zustand möglichst lange aufrechterhalten zu können, sollten Komfort-Verbraucher abgesc";
CM_ SG_ 1600 MO_Kennfeldk "Die Kennfeldkühlung ist in diesem Fahrzeug verbaut und hat keinen Systemfehler";
CM_ SG_ 1600 MO_KL15_Abschaltempfehlung "Kessy Abschaltempfehlung nach Verlassen des Fahrzeugs";
CM_ SG_ 1600 MO_Kuehlmittel_Temp "Kuehlmitteltemperatur";
CM_ SG_ 1600 MO_Mom_Traegheit_02 "Massenträgheit (J) der Motors bzw. der Antriebsmaschinen in kgm².

Zur Berücksichtigung des E-Motor in Hybrid-Projekten:
in MLB-Projekten wird nur der J-Wert des Verbrennungsmotors und nicht der J-Wert des E-Motors berücksichtigt.
In MQB/MLBevo-Projek";
CM_ SG_ 1600 MO_Nachlaufzeit_Heizungspumpe "Nachlaufzeit für Heizungspumpe für Turboladerschutz";
CM_ SG_ 1600 MO_Oel_Temp "Realer Meßbereich ca. -40..150 Grad";
CM_ SG_ 1600 MO_QBit_Ansaugluft_Temp "
";
CM_ SG_ 1600 MO_QBit_Hoeheninfo "Qualifizierungsbit der Höheninfo. Gesetzt bei Ersatzwert, Init oder Fehler.";
CM_ SG_ 1600 MO_QBit_Kuehlmittel_Temp "
";
CM_ SG_ 1600 MO_SpannungsAnf "Forderung des Motor-SGs zur Spannungsanhebung";
CM_ SG_ 1600 MO_Versionsinfo_02 "Versioninformation vom Motor zur Steuerung bei inkompatiblen KMatrix-Änderung bzw. Einführung von neuen Funktionen, die in den Empfängern verriegelt werden müssen. Zu jedem Ereignis wird ein fixer Zählerstand zugeordnet, um dem Empfänger die funktionale Ä";

CM_ SG_ 1607 MO_CO2_Faktor "dynamischer Umrechnungsfaktor von l in CO2";
CM_ SG_ 1607 MO_E85_Sensor "Information über den E85 Gehalt (%-mass.) im Ottokraftstoff";
CM_ SG_ 1607 MO_Ethanol_Spuelhinweis "Hinweis das der Fahrer beim nächsten Tanken Ethanol armen Sprit tanken soll.";
CM_ SG_ 1607 MO_ITM_Kuehlmittel_Temp "Kuehlmitteltemperatur: Ersatzkühlmitteltemperatur für Motoren mit ITM (Thermomanagement)

ACHTUNG: Ab MQB wird in diesem Signal das Anzeigeplateau durch das MSG dargestellt!";
CM_ SG_ 1607 MO_Kraftstofffilter_Wasser "Für Schlechtkraftstoffländer wird das Wasserabscheidevolumen im Dieselkraftstofffilter mit einem  Wassersensor überwacht. Ist das Volumen erschöpft, erfolgt im Kombi eine entsprechende Anzeige.";
CM_ SG_ 1607 MO_MKB_01 "Motorkennbuchstabe 1";
CM_ SG_ 1607 MO_MKB_02 "Motorkennbuchstabe 2";
CM_ SG_ 1607 MO_MKB_03 "Motorkennbuchstabe 3";
CM_ SG_ 1607 MO_MKB_04 "Motorkennbuchstabe 4";
CM_ SG_ 1607 MO_MKB_MUX "Die vier Motorkennbuchstaben werden gemultiplext in MO_MKB übertragen. Das Signal MO_MKB_MUX stellt das Steuersignal für diesen Multiplexer dar.";
CM_ SG_ 1607 SCR_Akustik "Ansteuerung von Summer/Gong bei Aktivieren der SCR-Warnungen.
Bedienung des Signals nur bei Dieseln mit SCR-System. Andere senden Initwert.";
CM_ SG_ 1607 SCR_Anz_Motorstarts "Anzahl noch möglicher Motorstarts, wenn Reichweite = 0 ist
0..13 = Anzeige 'x mögliche Restarts'
14 = Eingeschränkte Fahrfunktion (z. Zt. Audi)
15 = keine Einschränkung (Anzeige Reichweite)
Bedienung des Signals nur bei Dieseln mit SCR-System.";
CM_ SG_ 1607 SCR_Inducement_Strategie "Art des Motor-Inducement-Konzepts. Abhängig von diesem Signal sind die Warntexte zwischen 'Kein Motorstart (in...km)' und 'eingeschränkte Fahrbarkeit (in ...km)' auszuwählen.";
CM_ SG_ 1607 SCR_Reichweite "Gesamtreichweite in km der aktuellen SCR-Tankfüllung, sofern die Reichweite kleiner 2400 km ist. Bei einer Reichweite größer 2400 km wird grundsätzlich der Initwert (32767) übertragen. Bedienung des Signals nur bei Dieseln mit SCR-System.";
CM_ SG_ 1607 SCR_Systemfehler "Ansteuerung Anzeige für SCR-Systemfehler";
CM_ SG_ 1607 SCR_Text "Warntext (z. B. in Kombination mit SCR Warnstufe und SCR-Systemfehler).
Bedienung des Signals nur bei Dieseln mit SCR-System. Andere senden Initwert.";
CM_ SG_ 1607 SCR_verbaut "Die SCR-Signale deren Initwert ungleich 0 sind, werden nur dann ausgewertet, wenn SCR_verbaut == 1 den Verbau des SCR Systems zeigt.";
CM_ SG_ 1607 SCR_Warnstufe_1 "Ansteuerung der SCR Füllstandswarnlampe (Stufe 1) (gelbe Lampe) SCR_Warnstufe_1 (Prio 2).
Bedienung des Signals nur bei Dieseln mit SCR-System. Andere senden Initwert.";
CM_ SG_ 1607 SCR_Warnstufe_2 "Ansteuerung der SCR Füllstandswarnlampe (Stufe 2) (Blinkbit für gelbe Lampe oder rote Lampe) SCR_Warnstufe_2 (Prio 1).
Bedienung des Signals nur bei Dieseln mit SCR-System. Andere senden Initwert.";
BA_DEF_REL_ BU_SG_REL_  "GenSigTimeoutTime" INT 0 65535;
BA_DEF_ BO_  "DiagRequest" ENUM "No", "Yes";
BA_DEF_ BO_  "DiagResponse" ENUM "No", "Yes";
BA_DEF_ BO_  "DiagState" ENUM "No", "Yes";
BA_DEF_ BO_  "GenMsgChkConstant" HEX 0 4095;
BA_DEF_ BO_  "GenMsgCycleTime" INT 0 65535;
BA_DEF_ BO_  "GenMsgCycleTimeFast" INT 0 65535;
BA_DEF_ BO_  "GenMsgDelayTime" INT 0 100000;
BA_DEF_ BO_  "GenMsgILSupport" ENUM "No", "Yes";
BA_DEF_ BO_  "GenMsgNrOfRepetition" INT 0 100;
BA_DEF_ BO_  "GenMsgPDUConstants" STRING;
BA_DEF_ BO_  "GenMsgSendType" ENUM "Cyclic", "not_used", "not_used", "not_used", "not_used", "not_used", "not_used", "IfActive", "NoMsgSendType";
BA_DEF_ BO_  "GenMsgStartDelayTime" INT 0 100000;
BA_DEF_ BO_  "NmMessage" ENUM "No", "Yes";
BA_DEF_ BO_  "NmhMessage" ENUM "No", "Yes";
BA_DEF_ BO_  "MsgType" ENUM "Application", "NM ", "NMH", "TP2.0", "ISO-TP ", "BAP", "EID", "KS", "XCP_PRE_CONFIGURED", "XCP_RUNTIME_CONFIGURED";
BA_DEF_ BO_  "VAGTP20_API" HEX 0 255;
BA_DEF_ BO_  "VAGTP20_DynConnection" ENUM "No", "Yes";
BA_DEF_ BO_  "VAGTP20_DynSetup" ENUM "No", "Yes";
BA_DEF_ BO_  "VAGTP20_StatConnection" ENUM "No", "Yes";
BA_DEF_ BO_  "CANFD_BRS" ENUM "0", "1";
BA_DEF_ BO_  "VFrameFormat" ENUM "StandardCAN", "ExtendedCAN", "reserved", "reserved", "reserved", "reserved", "reserved", "reserved", "reserved", "reserved", "reserved", "reserved", "reserved", "reserved", "StandardCAN_FD", "ExtendedCAN_FD";
BA_DEF_ SG_  "GenSigActiveRepetitions" INT -2147483648 2147483647;
BA_DEF_ SG_  "GenSigInactiveValue" INT -2147483648 2147483647;
BA_DEF_ SG_  "GenSigSendType" ENUM "Cyclic", "OnWrite", "OnWriteWithRepetition", "OnChange", "OnChangeWithRepetition", "IfActive", "IfActiveWithRepetition", "NoSigSendType", "OnChangeAndIfActive", "OnChangeAndIfActiveWithRepetition";
BA_DEF_ SG_  "GenSigStartValue" INT -2147483648 2147483647;
BA_DEF_ SG_  "NWM-WakeupAllowed" ENUM "No", "Yes";
BA_DEF_ SG_  "GenSigFuncType" ENUM "NoFunction", "MsgCounter", "CRC-8", "XOR", "XOR-2", "DatedBit", "SW-Kl15", "CHK", "Constant", "Protocol", "CRC-8-SAE_J1850", "CRC-32", "DataLength", "DataID", "MsgCounter16", "SOK-Signatur", "Cluster";
BA_DEF_ SG_  "GenSigSwitchedByIgnition" ENUM "No", "Yes";
BA_DEF_ SG_  "Fehlerwert" HEX 0 2147483647;
BA_DEF_ SG_  "GenSigMissingSourceValue" HEX 0 2147483647;
BA_DEF_DEF_REL_  "GenSigTimeoutTime" 0;
BA_DEF_DEF_  "DiagRequest" "No";
BA_DEF_DEF_  "DiagResponse" "No";
BA_DEF_DEF_  "DiagState" "No";
BA_DEF_DEF_  "GenMsgChkConstant" 0;
BA_DEF_DEF_  "GenMsgCycleTime" 0;
BA_DEF_DEF_  "GenMsgCycleTimeFast" 0;
BA_DEF_DEF_  "GenMsgDelayTime" 0;
BA_DEF_DEF_  "GenMsgILSupport" "No";
BA_DEF_DEF_  "GenMsgNrOfRepetition" 0;
BA_DEF_DEF_  "GenMsgPDUConstants" "";
BA_DEF_DEF_  "GenMsgSendType" "NoMsgSendType";
BA_DEF_DEF_  "GenMsgStartDelayTime" 0;
BA_DEF_DEF_  "NmMessage" "No";
BA_DEF_DEF_  "NmhMessage" "No";
BA_DEF_DEF_  "MsgType" "Application";
BA_DEF_DEF_  "VAGTP20_API" 0;
BA_DEF_DEF_  "VAGTP20_DynConnection" "No";
BA_DEF_DEF_  "VAGTP20_DynSetup" "No";
BA_DEF_DEF_  "VAGTP20_StatConnection" "No";
BA_DEF_DEF_  "CANFD_BRS" "1";
BA_DEF_DEF_  "VFrameFormat" "StandardCAN";
BA_DEF_DEF_  "GenSigActiveRepetitions" 0;
BA_DEF_DEF_  "GenSigInactiveValue" 0;
BA_DEF_DEF_  "GenSigSendType" "NoSigSendType";
BA_DEF_DEF_  "GenSigStartValue" 0;
BA_DEF_DEF_  "NWM-WakeupAllowed" "No";
BA_DEF_DEF_  "GenSigFuncType" "NoFunction";
BA_DEF_DEF_  "GenSigSwitchedByIgnition" "Yes";
BA_DEF_DEF_  "Fehlerwert" 0;
BA_DEF_DEF_  "GenSigMissingSourceValue" 0;
BA_ "GenMsgCycleTime" BO_ 1624 1000;
BA_ "GenMsgDelayTime" BO_ 1624 50;
BA_ "GenMsgILSupport" BO_ 1624 1;
BA_ "GenMsgPDUConstants" BO_ 1624 "0x46,0x0f,0xe0,0xcc,0xbe,0xb1,0xd7,0xf1,0x1f,0x31,0xc1,0x25,0xb4,0x3e,0xc8,0xa3";
BA_ "GenMsgSendType" BO_ 1624 0;
BA_ "VFrameFormat" BO_ 1624 14;
BA_ "GenMsgCycleTime" BO_ 2463978598 200;
BA_ "GenMsgDelayTime" BO_ 2463978598 100;
BA_ "GenMsgILSupport" BO_ 2463978598 1;
BA_ "GenMsgSendType" BO_ 2463978598 0;
BA_ "VFrameFormat" BO_ 2463978598 15;
BA_ "GenMsgCycleTime" BO_ 822 120;
BA_ "GenMsgILSupport" BO_ 822 1;
BA_ "GenMsgSendType" BO_ 822 0;
BA_ "VFrameFormat" BO_ 822 14;
BA_ "GenMsgCycleTime" BO_ 2527679633 200;
BA_ "GenMsgILSupport" BO_ 2527679633 1;
BA_ "GenMsgSendType" BO_ 2527679633 0;
BA_ "VFrameFormat" BO_ 2527679633 15;
BA_ "GenMsgCycleTime" BO_ 2527679634 200;
BA_ "GenMsgILSupport" BO_ 2527679634 1;
BA_ "GenMsgSendType" BO_ 2527679634 0;
BA_ "VFrameFormat" BO_ 2527679634 15;
BA_ "GenMsgCycleTime" BO_ 917 100;
BA_ "GenMsgDelayTime" BO_ 917 10;
BA_ "GenMsgILSupport" BO_ 917 1;
BA_ "GenMsgSendType" BO_ 917 0;
BA_ "VFrameFormat" BO_ 917 14;
BA_ "GenMsgCycleTime" BO_ 1153 500;
BA_ "GenMsgCycleTimeFast" BO_ 1153 50;
BA_ "GenMsgDelayTime" BO_ 1153 50;
BA_ "GenMsgILSupport" BO_ 1153 1;
BA_ "GenMsgNrOfRepetition" BO_ 1153 5;
BA_ "GenMsgSendType" BO_ 1153 0;
BA_ "VFrameFormat" BO_ 1153 14;
BA_ "GenMsgCycleTime" BO_ 1639 100;
BA_ "GenMsgDelayTime" BO_ 1639 50;
BA_ "GenMsgILSupport" BO_ 1639 1;
BA_ "GenMsgPDUConstants" BO_ 1639 "0x65,0x98,0x5a,0x75,0xc8,0xc2,0xb1,0x73,0xa5,0xf4,0x72,0xf2,0x8d,0x20,0x9b,0x78";
BA_ "GenMsgSendType" BO_ 1639 0;
BA_ "VFrameFormat" BO_ 1639 14;
BA_ "GenMsgCycleTime" BO_ 2463978884 100;
BA_ "GenMsgDelayTime" BO_ 2463978884 50;
BA_ "GenMsgILSupport" BO_ 2463978884 1;
BA_ "GenMsgPDUConstants" BO_ 2463978884 "0xe5,0x1a,0x9d,0xab,0x5b,0x8f,0x46,0xd8,0x47,0x5f,0xa6,0x05,0x25,0x58,0xbd,0x17";
BA_ "GenMsgSendType" BO_ 2463978884 0;
BA_ "VFrameFormat" BO_ 2463978884 15;
BA_ "GenMsgCycleTime" BO_ 2463978889 200;
BA_ "GenMsgDelayTime" BO_ 2463978889 50;
BA_ "GenMsgILSupport" BO_ 2463978889 1;
BA_ "GenMsgPDUConstants" BO_ 2463978889 "0xb9,0x10,0x32,0xe5,0x9c,0x92,0x71,0x3d,0x4d,0x6d,0x46,0x18,0xa9,0xf3,0x7d,0x37";
BA_ "GenMsgSendType" BO_ 2463978889 0;
BA_ "VFrameFormat" BO_ 2463978889 15;
BA_ "GenMsgCycleTime" BO_ 1178 100;
BA_ "GenMsgDelayTime" BO_ 1178 50;
BA_ "GenMsgILSupport" BO_ 1178 1;
BA_ "GenMsgPDUConstants" BO_ 1178 "0xd0,0xc5,0xac,0x82,0xb1,0xfb,0x24,0x4d,0xc0,0x20,0x4b,0xbc,0x86,0x3b,0x22,0x25";
BA_ "GenMsgSendType" BO_ 1178 0;
BA_ "VFrameFormat" BO_ 1178 14;
BA_ "GenMsgCycleTime" BO_ 956 100;
BA_ "GenMsgDelayTime" BO_ 956 50;
BA_ "GenMsgILSupport" BO_ 956 1;
BA_ "GenMsgPDUConstants" BO_ 956 "0x44,0xca,0xd6,0xa3,0x16,0x1a,0x1d,0x9c,0xe3,0x55,0x85,0xe0,0x9b,0x82,0x8b,0xeb";
BA_ "GenMsgSendType" BO_ 956 0;
BA_ "VFrameFormat" BO_ 956 14;
BA_ "GenMsgCycleTime" BO_ 2463978890 200;
BA_ "GenMsgDelayTime" BO_ 2463978890 50;
BA_ "GenMsgILSupport" BO_ 2463978890 1;
BA_ "GenMsgPDUConstants" BO_ 2463978890 "0xba,0xd2,0x62,0x4e,0x72,0xe8,0x4b,0xd9,0x35,0x68,0x92,0x0d,0x5d,0xae,0xf6,0x50";
BA_ "GenMsgSendType" BO_ 2463978890 0;
BA_ "VFrameFormat" BO_ 2463978890 15;
BA_ "GenMsgChkConstant" BO_ 1171 151;
BA_ "GenMsgCycleTime" BO_ 1171 200;
BA_ "GenMsgDelayTime" BO_ 1171 20;
BA_ "GenMsgILSupport" BO_ 1171 1;
BA_ "GenMsgPDUConstants" BO_ 1171 "0x97,0x97,0x97,0x97,0x97,0x97,0x97,0x97,0x97,0x97,0x97,0x97,0x97,0x97,0x97,0x97";
BA_ "GenMsgSendType" BO_ 1171 0;
BA_ "VFrameFormat" BO_ 1171 14;
BA_ "GenMsgCycleTime" BO_ 1165 200;
BA_ "GenMsgILSupport" BO_ 1165 1;
BA_ "GenMsgPDUConstants" BO_ 1165 "0x84,0xcb,0x82,0xa1,0x41,0xe2,0xfa,0x9a,0x90,0x5e,0x51,0xe3,0xe8,0xc4,0x7f,0xf1";
BA_ "GenMsgSendType" BO_ 1165 0;
BA_ "VFrameFormat" BO_ 1165 14;
BA_ "GenMsgCycleTime" BO_ 1164 200;
BA_ "GenMsgCycleTimeFast" BO_ 1164 50;
BA_ "GenMsgDelayTime" BO_ 1164 20;
BA_ "GenMsgILSupport" BO_ 1164 1;
BA_ "GenMsgNrOfRepetition" BO_ 1164 5;
BA_ "GenMsgSendType" BO_ 1164 0;
BA_ "VFrameFormat" BO_ 1164 14;
BA_ "GenMsgCycleTime" BO_ 2463978883 100;
BA_ "GenMsgILSupport" BO_ 2463978883 1;
BA_ "GenMsgSendType" BO_ 2463978883 0;
BA_ "VFrameFormat" BO_ 2463978883 15;
BA_ "GenMsgCycleTimeFast" BO_ 1471 1000;
BA_ "GenMsgDelayTime" BO_ 1471 30;
BA_ "GenMsgILSupport" BO_ 1471 1;
BA_ "GenMsgNrOfRepetition" BO_ 1471 5;
BA_ "VFrameFormat" BO_ 1471 14;
BA_ "GenMsgCycleTime" BO_ 1600 500;
BA_ "GenMsgILSupport" BO_ 1600 1;
BA_ "GenMsgSendType" BO_ 1600 0;
BA_ "VFrameFormat" BO_ 1600 14;
BA_ "GenMsgCycleTime" BO_ 1607 500;
BA_ "GenMsgILSupport" BO_ 1607 1;
BA_ "GenMsgSendType" BO_ 1607 0;
BA_ "VFrameFormat" BO_ 1607 14;
BA_ "GenSigSendType" SG_ 1624 BCM1_Licht_Dunkelheit_aktiv 3;
BA_ "GenSigSwitchedByIgnition" SG_ 1624 BCM1_Licht_Dunkelheit_aktiv 0;
BA_ "GenSigSendType" SG_ 1624 BCM1_Linksverkehr 0;
BA_ "GenSigSwitchedByIgnition" SG_ 1624 BCM1_Linksverkehr 0;
BA_ "GenSigSendType" SG_ 1624 Licht_Vorne_01_BZ 0;
BA_ "GenSigFuncType" SG_ 1624 Licht_Vorne_01_BZ 1;
BA_ "GenSigSendType" SG_ 1624 Licht_Vorne_01_CRC 0;
BA_ "GenSigFuncType" SG_ 1624 Licht_Vorne_01_CRC 2;
BA_ "GenSigSendType" SG_ 1624 LV_Abbiegelicht_li_def 0;
BA_ "GenSigSwitchedByIgnition" SG_ 1624 LV_Abbiegelicht_li_def 0;
BA_ "GenSigSendType" SG_ 1624 LV_Abbiegelicht_re_def 0;
BA_ "GenSigSwitchedByIgnition" SG_ 1624 LV_Abbiegelicht_re_def 0;
BA_ "GenSigSendType" SG_ 1624 LV_Abblend_Fernlicht_li_def 0;
BA_ "GenSigSwitchedByIgnition" SG_ 1624 LV_Abblend_Fernlicht_li_def 0;
BA_ "GenSigSendType" SG_ 1624 LV_Abblend_Fernlicht_re_def 0;
BA_ "GenSigSwitchedByIgnition" SG_ 1624 LV_Abblend_Fernlicht_re_def 0;
BA_ "GenSigSendType" SG_ 1624 LV_Abblendlicht_Anzeige 3;
BA_ "GenSigSwitchedByIgnition" SG_ 1624 LV_Abblendlicht_Anzeige 0;
BA_ "GenSigSendType" SG_ 1624 LV_Abblendlicht_li_def 0;
BA_ "GenSigSwitchedByIgnition" SG_ 1624 LV_Abblendlicht_li_def 0;
BA_ "GenSigSendType" SG_ 1624 LV_Abblendlicht_re_def 0;
BA_ "GenSigSwitchedByIgnition" SG_ 1624 LV_Abblendlicht_re_def 0;
BA_ "GenSigSendType" SG_ 1624 LV_Abblendlicht_TFL_li_def 0;
BA_ "GenSigSwitchedByIgnition" SG_ 1624 LV_Abblendlicht_TFL_li_def 0;
BA_ "GenSigSendType" SG_ 1624 LV_Abblendlicht_TFL_re_def 0;
BA_ "GenSigSwitchedByIgnition" SG_ 1624 LV_Abblendlicht_TFL_re_def 0;
BA_ "GenSigSendType" SG_ 1624 LV_AFL_aktiv_Anzeige 3;
BA_ "GenSigSwitchedByIgnition" SG_ 1624 LV_AFL_aktiv_Anzeige 0;
BA_ "GenSigSendType" SG_ 1624 LV_AFL_defekt 3;
BA_ "GenSigSwitchedByIgnition" SG_ 1624 LV_AFL_defekt 0;
BA_ "GenSigSendType" SG_ 1624 LV_Aussenlicht_def 0;
BA_ "GenSigSwitchedByIgnition" SG_ 1624 LV_Aussenlicht_def 0;
BA_ "GenSigSendType" SG_ 1624 LV_Blinker_li_def 0;
BA_ "GenSigSwitchedByIgnition" SG_ 1624 LV_Blinker_li_def 0;
BA_ "GenSigSendType" SG_ 1624 LV_Blinker_re_def 0;
BA_ "GenSigSwitchedByIgnition" SG_ 1624 LV_Blinker_re_def 0;
BA_ "GenSigSendType" SG_ 1624 LV_Blinker_VL_aktiv 3;
BA_ "GenSigSwitchedByIgnition" SG_ 1624 LV_Blinker_VL_aktiv 0;
BA_ "GenSigSendType" SG_ 1624 LV_Blinker_VR_aktiv 3;
BA_ "GenSigSwitchedByIgnition" SG_ 1624 LV_Blinker_VR_aktiv 0;
BA_ "GenSigSendType" SG_ 1624 LV_Blk_li_Seite_def 0;
BA_ "GenSigSwitchedByIgnition" SG_ 1624 LV_Blk_li_Seite_def 0;
BA_ "GenSigSendType" SG_ 1624 LV_Blk_re_Seite_def 0;
BA_ "GenSigSwitchedByIgnition" SG_ 1624 LV_Blk_re_Seite_def 0;
BA_ "GenSigSendType" SG_ 1624 LV_Fernlicht_Anzeige 3;
BA_ "GenSigSwitchedByIgnition" SG_ 1624 LV_Fernlicht_Anzeige 0;
BA_ "GenSigSendType" SG_ 1624 LV_Fernlicht_li_def 0;
BA_ "GenSigSwitchedByIgnition" SG_ 1624 LV_Fernlicht_li_def 0;
BA_ "GenSigSendType" SG_ 1624 LV_Fernlicht_re_def 0;
BA_ "GenSigSwitchedByIgnition" SG_ 1624 LV_Fernlicht_re_def 0;
BA_ "GenSigSendType" SG_ 1624 LV_FLA_aktiv_Anzeige 3;
BA_ "GenSigSwitchedByIgnition" SG_ 1624 LV_FLA_aktiv_Anzeige 0;
BA_ "GenSigSendType" SG_ 1624 LV_FLA_defekt 0;
BA_ "GenSigSwitchedByIgnition" SG_ 1624 LV_FLA_defekt 0;
BA_ "GenSigSendType" SG_ 1624 LV_FLA_Sensor_blockiert 0;
BA_ "GenSigSwitchedByIgnition" SG_ 1624 LV_FLA_Sensor_blockiert 0;
BA_ "GenSigSendType" SG_ 1624 LV_LED_Scheinwerfer_li_def 0;
BA_ "GenSigSwitchedByIgnition" SG_ 1624 LV_LED_Scheinwerfer_li_def 0;
BA_ "GenSigSendType" SG_ 1624 LV_LED_Scheinwerfer_re_def 0;
BA_ "GenSigSwitchedByIgnition" SG_ 1624 LV_LED_Scheinwerfer_re_def 0;
BA_ "GenSigSendType" SG_ 1624 LV_MXB_Status_Anzeige 3;
BA_ "GenSigSwitchedByIgnition" SG_ 1624 LV_MXB_Status_Anzeige 0;
BA_ "GenSigSendType" SG_ 1624 LV_Nebellicht_Anzeige 3;
BA_ "GenSigSwitchedByIgnition" SG_ 1624 LV_Nebellicht_Anzeige 0;
BA_ "GenSigSendType" SG_ 1624 LV_Nebellicht_li_def 0;
BA_ "GenSigSwitchedByIgnition" SG_ 1624 LV_Nebellicht_li_def 0;
BA_ "GenSigSendType" SG_ 1624 LV_Nebellicht_re_def 0;
BA_ "GenSigSwitchedByIgnition" SG_ 1624 LV_Nebellicht_re_def 0;
BA_ "GenSigSendType" SG_ 1624 LV_Nebellicht_TFL_li_def 0;
BA_ "GenSigSwitchedByIgnition" SG_ 1624 LV_Nebellicht_TFL_li_def 0;
BA_ "GenSigSendType" SG_ 1624 LV_Nebellicht_TFL_re_def 0;
BA_ "GenSigSwitchedByIgnition" SG_ 1624 LV_Nebellicht_TFL_re_def 0;
BA_ "GenSigSendType" SG_ 1624 LV_Nebelschlusslicht_Anzeige 3;
BA_ "GenSigSwitchedByIgnition" SG_ 1624 LV_Nebelschlusslicht_Anzeige 0;
BA_ "GenSigSendType" SG_ 1624 LV_Standlicht_Anzeige 3;
BA_ "GenSigSwitchedByIgnition" SG_ 1624 LV_Standlicht_Anzeige 0;
BA_ "GenSigSendType" SG_ 1624 LV_Standlicht_li_def 0;
BA_ "GenSigSwitchedByIgnition" SG_ 1624 LV_Standlicht_li_def 0;
BA_ "GenSigSendType" SG_ 1624 LV_Standlicht_re_def 0;
BA_ "GenSigSwitchedByIgnition" SG_ 1624 LV_Standlicht_re_def 0;
BA_ "GenSigSendType" SG_ 1624 LV_Standlicht_TFL_li_def 0;
BA_ "GenSigSwitchedByIgnition" SG_ 1624 LV_Standlicht_TFL_li_def 0;
BA_ "GenSigSendType" SG_ 1624 LV_Standlicht_TFL_re_def 0;
BA_ "GenSigSwitchedByIgnition" SG_ 1624 LV_Standlicht_TFL_re_def 0;
BA_ "GenSigSendType" SG_ 1624 LV_Tagfahrlicht_Anzeige 3;
BA_ "GenSigSwitchedByIgnition" SG_ 1624 LV_Tagfahrlicht_Anzeige 0;
BA_ "GenSigSendType" SG_ 1624 LV_Tagfahrlicht_li_def 0;
BA_ "GenSigSwitchedByIgnition" SG_ 1624 LV_Tagfahrlicht_li_def 0;
BA_ "GenSigSendType" SG_ 1624 LV_Tagfahrlicht_re_def 0;
BA_ "GenSigSwitchedByIgnition" SG_ 1624 LV_Tagfahrlicht_re_def 0;
BA_ "GenSigSendType" SG_ 2463978598 LoGeWa_C2C_Anf_Audioabsenkung 3;
BA_ "GenSigSwitchedByIgnition" SG_ 2463978598 LoGeWa_C2C_Anf_Audioabsenkung 0;
BA_ "GenSigSendType" SG_ 2463978598 LoGeWa_C2C_Event_Einheit 0;
BA_ "GenSigSendType" SG_ 2463978598 LoGeWa_C2C_Event_Entfernung 0;
BA_ "GenSigStartValue" SG_ 2463978598 LoGeWa_C2C_Event_Entfernung 65535;
BA_ "GenSigSendType" SG_ 2463978598 LoGeWa_C2C_Event_Richtung 0;
BA_ "GenSigSendType" SG_ 2463978598 LoGeWa_C2C_Event_Status 3;
BA_ "GenSigSendType" SG_ 2463978598 LoGeWa_C2C_Event_Warnung 0;
BA_ "GenSigSwitchedByIgnition" SG_ 2463978598 LoGeWa_C2C_Event_Warnung 0;
BA_ "GenSigSendType" SG_ 822 LR_HZG_Konfiguration 0;
BA_ "GenSigSwitchedByIgnition" SG_ 822 LR_HZG_Konfiguration 0;
BA_ "GenSigSendType" SG_ 822 LR_HZG_Taster_on_off 0;
BA_ "GenSigSwitchedByIgnition" SG_ 822 LR_HZG_Taster_on_off 0;
BA_ "GenSigSendType" SG_ 822 LR_HZG_Temp_Sensor 0;
BA_ "GenSigStartValue" SG_ 822 LR_HZG_Temp_Sensor 254;
BA_ "GenSigSwitchedByIgnition" SG_ 822 LR_HZG_Temp_Sensor 0;
BA_ "GenSigSendType" SG_ 2527679633 LSH_Ansaug_Fuell_1 0;
BA_ "GenSigStartValue" SG_ 2527679633 LSH_Ansaug_Fuell_1 254;
BA_ "GenSigSwitchedByIgnition" SG_ 2527679633 LSH_Ansaug_Fuell_1 0;
BA_ "Fehlerwert" SG_ 2527679633 LSH_Ansaug_Fuell_1 255;
BA_ "GenSigSendType" SG_ 2527679633 LSH_Ansaug_Fuell_2 0;
BA_ "GenSigStartValue" SG_ 2527679633 LSH_Ansaug_Fuell_2 254;
BA_ "GenSigSwitchedByIgnition" SG_ 2527679633 LSH_Ansaug_Fuell_2 0;
BA_ "Fehlerwert" SG_ 2527679633 LSH_Ansaug_Fuell_2 255;
BA_ "GenSigSendType" SG_ 2527679633 LSH_Empf_Heizstufe 0;
BA_ "GenSigSwitchedByIgnition" SG_ 2527679633 LSH_Empf_Heizstufe 0;
BA_ "Fehlerwert" SG_ 2527679633 LSH_Empf_Heizstufe 15;
BA_ "GenSigSendType" SG_ 2527679633 LSH_Funk_aus 0;
BA_ "GenSigSwitchedByIgnition" SG_ 2527679633 LSH_Funk_aus 0;
BA_ "GenSigSendType" SG_ 2527679633 LSH_Funk_ein 0;
BA_ "GenSigSwitchedByIgnition" SG_ 2527679633 LSH_Funk_ein 0;
BA_ "GenSigSendType" SG_ 2527679633 LSH_Geblaese_aktiv 0;
BA_ "GenSigSwitchedByIgnition" SG_ 2527679633 LSH_Geblaese_aktiv 0;
BA_ "GenSigSendType" SG_ 2527679633 LSH_Heiztemp 0;
BA_ "GenSigStartValue" SG_ 2527679633 LSH_Heiztemp 254;
BA_ "GenSigSwitchedByIgnition" SG_ 2527679633 LSH_Heiztemp 0;
BA_ "Fehlerwert" SG_ 2527679633 LSH_Heiztemp 255;
BA_ "GenSigSendType" SG_ 2527679633 LSH_Klappe_Status 0;
BA_ "GenSigSwitchedByIgnition" SG_ 2527679633 LSH_Klappe_Status 0;
BA_ "GenSigSendType" SG_ 2527679633 LSH_LED 0;
BA_ "GenSigSwitchedByIgnition" SG_ 2527679633 LSH_LED 0;
BA_ "GenSigSendType" SG_ 2527679633 LSH_Servicemode 0;
BA_ "GenSigSwitchedByIgnition" SG_ 2527679633 LSH_Servicemode 0;
BA_ "GenSigSendType" SG_ 2527679633 LSH_Start_folgt 0;
BA_ "GenSigSwitchedByIgnition" SG_ 2527679633 LSH_Start_folgt 0;
BA_ "GenSigSendType" SG_ 2527679633 LSH_Texte 0;
BA_ "GenSigSwitchedByIgnition" SG_ 2527679633 LSH_Texte 0;
BA_ "GenSigSendType" SG_ 2527679633 LSH_Waermeeintrag 0;
BA_ "GenSigStartValue" SG_ 2527679633 LSH_Waermeeintrag 510;
BA_ "GenSigSwitchedByIgnition" SG_ 2527679633 LSH_Waermeeintrag 0;
BA_ "Fehlerwert" SG_ 2527679633 LSH_Waermeeintrag 511;
BA_ "GenSigSendType" SG_ 2527679634 LSH_Fehlerstatus 0;
BA_ "GenSigSwitchedByIgnition" SG_ 2527679634 LSH_Fehlerstatus 0;
BA_ "GenSigSendType" SG_ 2527679634 LSH_Heizleistung 0;
BA_ "GenSigSwitchedByIgnition" SG_ 2527679634 LSH_Heizleistung 0;
BA_ "GenSigSendType" SG_ 2527679634 LSH_KL_DBetr_Anf 0;
BA_ "GenSigSwitchedByIgnition" SG_ 2527679634 LSH_KL_DBetr_Anf 0;
BA_ "GenSigSendType" SG_ 2527679634 LSH_KVS 0;
BA_ "GenSigSwitchedByIgnition" SG_ 2527679634 LSH_KVS 0;
BA_ "GenSigSendType" SG_ 2527679634 LSH_KVS_Ueberlauf 0;
BA_ "GenSigSwitchedByIgnition" SG_ 2527679634 LSH_KVS_Ueberlauf 0;
BA_ "GenSigSendType" SG_ 2527679634 LSH_Zuheizen 0;
BA_ "GenSigSwitchedByIgnition" SG_ 2527679634 LSH_Zuheizen 0;
BA_ "GenSigSendType" SG_ 917 AFS_Abbiegelicht_Dimm_Anf 0;
BA_ "GenSigSendType" SG_ 917 AFS_Abbiegelicht_li_Anf 0;
BA_ "GenSigSendType" SG_ 917 AFS_Abbiegelicht_re_Anf 0;
BA_ "GenSigSendType" SG_ 917 AFS_adaptive_LV_verbaut 0;
BA_ "GenSigSendType" SG_ 917 AFS_Allwetterlicht 0;
BA_ "GenSigSendType" SG_ 917 AFS_Charisma_FahrPr 0;
BA_ "GenSigSendType" SG_ 917 AFS_Charisma_Status 0;
BA_ "GenSigSendType" SG_ 917 AFS_Ersatzlicht_Links 0;
BA_ "GenSigSendType" SG_ 917 AFS_Ersatzlicht_Rechts 0;
BA_ "GenSigSendType" SG_ 917 AFS_Fehlertext 0;
BA_ "GenSigSendType" SG_ 917 AFS_Fernlicht_li_defekt 0;
BA_ "GenSigSendType" SG_ 917 AFS_Fernlicht_re_defekt 0;
BA_ "GenSigSendType" SG_ 917 AFS_Fernlicht_Status 3;
BA_ "GenSigSendType" SG_ 917 AFS_Lampe 0;
BA_ "GenSigSendType" SG_ 917 AFS_LED_Blinkmode 0;
BA_ "GenSigSendType" SG_ 917 AFS_Status_adaptive_LV 0;
BA_ "GenSigStartValue" SG_ 917 AFS_Status_adaptive_LV 1;
BA_ "GenSigSendType" SG_ 917 AFS_Verfuegbarkeit_GLW 0;
BA_ "GenSigStartValue" SG_ 917 AFS_Verfuegbarkeit_GLW 1;
BA_ "GenSigSendType" SG_ 917 GLW_Sensor_blockiert 0;
BA_ "GenSigSendType" SG_ 917 LWR_AFS_01_BZ 0;
BA_ "GenSigFuncType" SG_ 917 LWR_AFS_01_BZ 1;
BA_ "GenSigSendType" SG_ 917 LWR_AFS_Grundeinstellung 0;
BA_ "GenSigSendType" SG_ 917 LWR_AFS_Parametrisierung 0;
BA_ "GenSigSendType" SG_ 917 LWR_Hoehenwert_HL 0;
BA_ "GenSigStartValue" SG_ 917 LWR_Hoehenwert_HL 254;
BA_ "Fehlerwert" SG_ 917 LWR_Hoehenwert_HL 255;
BA_ "GenSigSendType" SG_ 917 LWR_Hoehenwert_VL 0;
BA_ "GenSigStartValue" SG_ 917 LWR_Hoehenwert_VL 254;
BA_ "Fehlerwert" SG_ 917 LWR_Hoehenwert_VL 255;
BA_ "GenSigSendType" SG_ 917 LWR_Initialisierungslauf 0;
BA_ "GenSigSendType" SG_ 917 LWR_Lampe 0;
BA_ "GenSigSendType" SG_ 917 LWR_Modus 0;
BA_ "GenSigSendType" SG_ 917 LWR_Pos_Schrittmotor 0;
BA_ "GenSigStartValue" SG_ 917 LWR_Pos_Schrittmotor 254;
BA_ "Fehlerwert" SG_ 917 LWR_Pos_Schrittmotor 255;
BA_ "GenSigSendType" SG_ 917 LWR_Reisemodus_Texte 0;
BA_ "GenSigSendType" SG_ 917 LWR_Sicherheitsposition 0;
BA_ "GenSigSendType" SG_ 917 LWR_Touristenmodus_aktiv 0;
BA_ "GenSigSendType" SG_ 917 LWR_Touristenmodus_verbaut 0;
BA_ "GenSigSendType" SG_ 1153 DSSS_Warning 3;
BA_ "GenSigSwitchedByIgnition" SG_ 1153 DSSS_Warning 0;
BA_ "GenSigSendType" SG_ 1153 MIB_ASW_Diagnose 0;
BA_ "GenSigSwitchedByIgnition" SG_ 1153 MIB_ASW_Diagnose 0;
BA_ "GenSigSendType" SG_ 1153 MIB_Tongenerator_PH_verfuegbar 3;
BA_ "GenSigSwitchedByIgnition" SG_ 1153 MIB_Tongenerator_PH_verfuegbar 0;
BA_ "GenSigSendType" SG_ 1153 MMI_Counter_Bedienevent 0;
BA_ "GenSigSwitchedByIgnition" SG_ 1153 MMI_Counter_Bedienevent 0;
BA_ "GenSigSendType" SG_ 1153 MMI_Gurt_Mic_ref 3;
BA_ "GenSigSwitchedByIgnition" SG_ 1153 MMI_Gurt_Mic_ref 0;
BA_ "GenSigSendType" SG_ 1153 MMI_SDS_aktiv 3;
BA_ "GenSigSwitchedByIgnition" SG_ 1153 MMI_SDS_aktiv 0;
BA_ "GenSigSendType" SG_ 1153 MMI_Telefon_aktiv 3;
BA_ "GenSigSwitchedByIgnition" SG_ 1153 MMI_Telefon_aktiv 0;
BA_ "GenSigSendType" SG_ 1153 MU_SecondDisplay 3;
BA_ "GenSigSwitchedByIgnition" SG_ 1153 MU_SecondDisplay 0;
BA_ "GenSigSendType" SG_ 1153 MU_Update_Time 0;
BA_ "GenSigSwitchedByIgnition" SG_ 1153 MU_Update_Time 0;
BA_ "GenSigSendType" SG_ 1153 Nav_FoD_Status 0;
BA_ "GenSigSwitchedByIgnition" SG_ 1153 Nav_FoD_Status 0;
BA_ "GenSigSendType" SG_ 1153 ZR_AppConnect_Zustand 4;
BA_ "GenSigSwitchedByIgnition" SG_ 1153 ZR_AppConnect_Zustand 0;
BA_ "GenSigSendType" SG_ 1153 ZR_Kindersicherung_RSE 3;
BA_ "GenSigSwitchedByIgnition" SG_ 1153 ZR_Kindersicherung_RSE 0;
BA_ "GenSigSendType" SG_ 1153 ZR_Lichter_Tag 3;
BA_ "GenSigSwitchedByIgnition" SG_ 1153 ZR_Lichter_Tag 0;
BA_ "GenSigSendType" SG_ 1153 ZR_LoGeWa_Event_Kombiwarnung 3;
BA_ "GenSigSwitchedByIgnition" SG_ 1153 ZR_LoGeWa_Event_Kombiwarnung 0;
BA_ "GenSigSendType" SG_ 1153 ZR_Parken_Sondermodus 3;
BA_ "GenSigSwitchedByIgnition" SG_ 1153 ZR_Parken_Sondermodus 0;
BA_ "GenSigSendType" SG_ 1153 ZR_RSE_aktivieren 3;
BA_ "GenSigSwitchedByIgnition" SG_ 1153 ZR_RSE_aktivieren 0;
BA_ "GenSigSendType" SG_ 1153 ZR_Sta_Inszenierung 4;
BA_ "GenSigSwitchedByIgnition" SG_ 1153 ZR_Sta_Inszenierung 0;
BA_ "GenSigSendType" SG_ 1639 BFS_Fond_Bed_Ack 3;
BA_ "GenSigSwitchedByIgnition" SG_ 1639 BFS_Fond_Bed_Ack 0;
BA_ "GenSigSendType" SG_ 1639 BFS_FSV_ausgeklappt 0;
BA_ "GenSigSwitchedByIgnition" SG_ 1639 BFS_FSV_ausgeklappt 0;
BA_ "GenSigSendType" SG_ 1639 BFS_GHV_aktiv 3;
BA_ "GenSigSwitchedByIgnition" SG_ 1639 BFS_GHV_aktiv 0;
BA_ "GenSigSendType" SG_ 1639 BFS_Gurtbringer_Sperre 0;
BA_ "GenSigSwitchedByIgnition" SG_ 1639 BFS_Gurtbringer_Sperre 0;
BA_ "GenSigSendType" SG_ 1639 BFS_Klappfunktion_Aktiv 3;
BA_ "GenSigSwitchedByIgnition" SG_ 1639 BFS_Klappfunktion_Aktiv 0;
BA_ "GenSigSendType" SG_ 1639 BFS_Klappfunktion_Bed_Ack 3;
BA_ "GenSigSwitchedByIgnition" SG_ 1639 BFS_Klappfunktion_Bed_Ack 0;
BA_ "GenSigSendType" SG_ 1639 BFS_Klappfunktion_Beschraenkung 3;
BA_ "GenSigSwitchedByIgnition" SG_ 1639 BFS_Klappfunktion_Beschraenkung 0;
BA_ "GenSigSendType" SG_ 1639 BFS_Klappfunktion_Status 3;
BA_ "GenSigSwitchedByIgnition" SG_ 1639 BFS_Klappfunktion_Status 0;
BA_ "GenSigSendType" SG_ 1639 BFS_Klapptisch_offen 3;
BA_ "GenSigSwitchedByIgnition" SG_ 1639 BFS_Klapptisch_offen 0;
BA_ "GenSigSendType" SG_ 1639 BFS_KSS_Fahrt_aktiv 3;
BA_ "GenSigSwitchedByIgnition" SG_ 1639 BFS_KSS_Fahrt_aktiv 0;
BA_ "GenSigSendType" SG_ 1639 BFS_KSV_aktiv 3;
BA_ "GenSigSwitchedByIgnition" SG_ 1639 BFS_KSV_aktiv 0;
BA_ "GenSigSendType" SG_ 1639 BFS_Lehne_nicht_verriegelt 3;
BA_ "GenSigSwitchedByIgnition" SG_ 1639 BFS_Lehne_nicht_verriegelt 0;
BA_ "GenSigSendType" SG_ 1639 BFS_LHV_aktiv 3;
BA_ "GenSigSwitchedByIgnition" SG_ 1639 BFS_LHV_aktiv 0;
BA_ "GenSigSendType" SG_ 1639 BFS_LKV_aktiv 3;
BA_ "GenSigSwitchedByIgnition" SG_ 1639 BFS_LKV_aktiv 0;
BA_ "GenSigSendType" SG_ 1639 BFS_LNV_aktiv 3;
BA_ "GenSigSwitchedByIgnition" SG_ 1639 BFS_LNV_aktiv 0;
BA_ "GenSigSendType" SG_ 1639 BFS_LWV_aktiv 3;
BA_ "GenSigSwitchedByIgnition" SG_ 1639 BFS_LWV_aktiv 0;
BA_ "GenSigSendType" SG_ 1639 BFS_MMB_glob_stop 3;
BA_ "GenSigSwitchedByIgnition" SG_ 1639 BFS_MMB_glob_stop 0;
BA_ "GenSigSendType" SG_ 1639 BFS_MMB_lokal_Stop 3;
BA_ "GenSigSwitchedByIgnition" SG_ 1639 BFS_MMB_lokal_Stop 0;
BA_ "GenSigSendType" SG_ 1639 BFS_MMB_storage 3;
BA_ "GenSigSwitchedByIgnition" SG_ 1639 BFS_MMB_storage 0;
BA_ "GenSigSendType" SG_ 1639 BFS_MMB_storage_beep 3;
BA_ "GenSigSwitchedByIgnition" SG_ 1639 BFS_MMB_storage_beep 0;
BA_ "GenSigSendType" SG_ 1639 BFS_MMB_store 3;
BA_ "GenSigSwitchedByIgnition" SG_ 1639 BFS_MMB_store 0;
BA_ "GenSigSendType" SG_ 1639 BFS_MMB_store_LED_on 3;
BA_ "GenSigSwitchedByIgnition" SG_ 1639 BFS_MMB_store_LED_on 0;
BA_ "GenSigSendType" SG_ 1639 BFS_MMB_tast 3;
BA_ "GenSigSwitchedByIgnition" SG_ 1639 BFS_MMB_tast 0;
BA_ "GenSigSendType" SG_ 1639 BFS_MMB_tipp 3;
BA_ "GenSigSwitchedByIgnition" SG_ 1639 BFS_MMB_tipp 0;
BA_ "GenSigSendType" SG_ 1639 BFS_Ruhestellung_Status 3;
BA_ "GenSigSwitchedByIgnition" SG_ 1639 BFS_Ruhestellung_Status 0;
BA_ "GenSigSendType" SG_ 1639 BFS_Seat_Locked 0;
BA_ "GenSigSwitchedByIgnition" SG_ 1639 BFS_Seat_Locked 0;
BA_ "GenSigSendType" SG_ 1639 BFS_SHV_aktiv 3;
BA_ "GenSigSwitchedByIgnition" SG_ 1639 BFS_SHV_aktiv 0;
BA_ "GenSigSendType" SG_ 1639 BFS_Sitzfahrt_aktiv 3;
BA_ "GenSigSwitchedByIgnition" SG_ 1639 BFS_Sitzfahrt_aktiv 0;
BA_ "GenSigSendType" SG_ 1639 BFS_Sitzsym_Fahrt_aktiv 3;
BA_ "GenSigSwitchedByIgnition" SG_ 1639 BFS_Sitzsym_Fahrt_aktiv 0;
BA_ "GenSigSendType" SG_ 1639 BFS_SLV_aktiv 3;
BA_ "GenSigSwitchedByIgnition" SG_ 1639 BFS_SLV_aktiv 0;
BA_ "GenSigSendType" SG_ 1639 BFS_SNV_aktiv 3;
BA_ "GenSigSwitchedByIgnition" SG_ 1639 BFS_SNV_aktiv 0;
BA_ "GenSigSendType" SG_ 1639 BFS_STV_aktiv 3;
BA_ "GenSigSwitchedByIgnition" SG_ 1639 BFS_STV_aktiv 0;
BA_ "GenSigSendType" SG_ 1639 Mem_BFS_01_BZ 0;
BA_ "GenSigFuncType" SG_ 1639 Mem_BFS_01_BZ 1;
BA_ "GenSigSwitchedByIgnition" SG_ 1639 Mem_BFS_01_BZ 0;
BA_ "GenSigSendType" SG_ 1639 Mem_BFS_01_CRC 0;
BA_ "GenSigFuncType" SG_ 1639 Mem_BFS_01_CRC 2;
BA_ "GenSigSwitchedByIgnition" SG_ 1639 Mem_BFS_01_CRC 0;
BA_ "GenSigSendType" SG_ 2463978884 HBFS_Anfahrt_EasyEntry 3;
BA_ "GenSigSwitchedByIgnition" SG_ 2463978884 HBFS_Anfahrt_EasyEntry 0;
BA_ "GenSigSendType" SG_ 2463978884 HBFS_Anfahrt_Klappfunktion 3;
BA_ "GenSigSwitchedByIgnition" SG_ 2463978884 HBFS_Anfahrt_Klappfunktion 0;
BA_ "GenSigSendType" SG_ 2463978884 HBFS_Anfahrt_Komfortposition 3;
BA_ "GenSigSwitchedByIgnition" SG_ 2463978884 HBFS_Anfahrt_Komfortposition 0;
BA_ "GenSigSendType" SG_ 2463978884 HBFS_EasyEntry_Aktiv 3;
BA_ "GenSigSwitchedByIgnition" SG_ 2463978884 HBFS_EasyEntry_Aktiv 0;
BA_ "GenSigSendType" SG_ 2463978884 HBFS_EasyEntry_Beschraenkung 3;
BA_ "GenSigSwitchedByIgnition" SG_ 2463978884 HBFS_EasyEntry_Beschraenkung 0;
BA_ "GenSigSendType" SG_ 2463978884 HBFS_EasyEntry_Status 3;
BA_ "GenSigSwitchedByIgnition" SG_ 2463978884 HBFS_EasyEntry_Status 0;
BA_ "GenSigSendType" SG_ 2463978884 HBFS_Fahrposition 3;
BA_ "GenSigSwitchedByIgnition" SG_ 2463978884 HBFS_Fahrposition 0;
BA_ "GenSigSendType" SG_ 2463978884 HBFS_Klappfunktion_Aktiv 3;
BA_ "GenSigSwitchedByIgnition" SG_ 2463978884 HBFS_Klappfunktion_Aktiv 0;
BA_ "GenSigSendType" SG_ 2463978884 HBFS_Klappfunktion_Beschraenkung 3;
BA_ "GenSigSwitchedByIgnition" SG_ 2463978884 HBFS_Klappfunktion_Beschraenkung 0;
BA_ "GenSigSendType" SG_ 2463978884 HBFS_Klappfunktion_Status 3;
BA_ "GenSigSwitchedByIgnition" SG_ 2463978884 HBFS_Klappfunktion_Status 0;
BA_ "GenSigSendType" SG_ 2463978884 HBFS_Komfortposition_Aktiv 3;
BA_ "GenSigSwitchedByIgnition" SG_ 2463978884 HBFS_Komfortposition_Aktiv 0;
BA_ "GenSigSendType" SG_ 2463978884 HBFS_Komfortposition_Beschraenku 3;
BA_ "GenSigSwitchedByIgnition" SG_ 2463978884 HBFS_Komfortposition_Beschraenku 0;
BA_ "GenSigSendType" SG_ 2463978884 HBFS_Komfortposition_Status 3;
BA_ "GenSigSwitchedByIgnition" SG_ 2463978884 HBFS_Komfortposition_Status 0;
BA_ "GenSigSendType" SG_ 2463978884 HBFS_Kopfst_unten 3;
BA_ "GenSigSwitchedByIgnition" SG_ 2463978884 HBFS_Kopfst_unten 0;
BA_ "GenSigSendType" SG_ 2463978884 Mem_BFS_Fond_02_BZ 0;
BA_ "GenSigFuncType" SG_ 2463978884 Mem_BFS_Fond_02_BZ 1;
BA_ "GenSigSwitchedByIgnition" SG_ 2463978884 Mem_BFS_Fond_02_BZ 0;
BA_ "GenSigSendType" SG_ 2463978884 Mem_BFS_Fond_02_CRC 0;
BA_ "GenSigFuncType" SG_ 2463978884 Mem_BFS_Fond_02_CRC 2;
BA_ "GenSigSwitchedByIgnition" SG_ 2463978884 Mem_BFS_Fond_02_CRC 0;
BA_ "GenSigSendType" SG_ 2463978884 Mem_BFSFo_Warn_Dreh_entriegelt 3;
BA_ "GenSigSwitchedByIgnition" SG_ 2463978884 Mem_BFSFo_Warn_Dreh_entriegelt 0;
BA_ "GenSigSendType" SG_ 2463978884 Mem_BFSFo_Warn_Verriegelung 3;
BA_ "GenSigSwitchedByIgnition" SG_ 2463978884 Mem_BFSFo_Warn_Verriegelung 0;
BA_ "GenSigSendType" SG_ 2463978884 Mem_HBFS_Seat_Attention 3;
BA_ "GenSigSwitchedByIgnition" SG_ 2463978884 Mem_HBFS_Seat_Attention 0;
BA_ "Fehlerwert" SG_ 2463978884 Mem_HBFS_Seat_Attention 7;
BA_ "GenSigSendType" SG_ 2463978884 Zielpositio_Hoeh_BFS_fur_EA_HBFS 3;
BA_ "GenSigSwitchedByIgnition" SG_ 2463978884 Zielpositio_Hoeh_BFS_fur_EA_HBFS 0;
BA_ "GenSigSendType" SG_ 2463978889 Mem_BFS_Fond_03_BZ 0;
BA_ "GenSigFuncType" SG_ 2463978889 Mem_BFS_Fond_03_BZ 1;
BA_ "GenSigSwitchedByIgnition" SG_ 2463978889 Mem_BFS_Fond_03_BZ 0;
BA_ "GenSigSendType" SG_ 2463978889 Mem_BFS_Fond_03_CRC 0;
BA_ "GenSigFuncType" SG_ 2463978889 Mem_BFS_Fond_03_CRC 2;
BA_ "GenSigSwitchedByIgnition" SG_ 2463978889 Mem_BFS_Fond_03_CRC 0;
BA_ "GenSigSendType" SG_ 2463978889 Mem_HBFSFo_Abschaltanf_SRAB 3;
BA_ "GenSigStartValue" SG_ 2463978889 Mem_HBFSFo_Abschaltanf_SRAB 2;
BA_ "GenSigSwitchedByIgnition" SG_ 2463978889 Mem_HBFSFo_Abschaltanf_SRAB 0;
BA_ "Fehlerwert" SG_ 2463978889 Mem_HBFSFo_Abschaltanf_SRAB 3;
BA_ "GenSigSendType" SG_ 2463978889 Mem_HBFSFo_Anzeige_Komfort_HBFS 3;
BA_ "GenSigSwitchedByIgnition" SG_ 2463978889 Mem_HBFSFo_Anzeige_Komfort_HBFS 0;
BA_ "GenSigSendType" SG_ 2463978889 Mem_HBFSFo_ARMTuer_aktiv 3;
BA_ "GenSigSwitchedByIgnition" SG_ 2463978889 Mem_HBFSFo_ARMTuer_aktiv 0;
BA_ "GenSigSendType" SG_ 2463978889 Mem_HBFSFo_ARMTunnel_aktiv 3;
BA_ "GenSigSwitchedByIgnition" SG_ 2463978889 Mem_HBFSFo_ARMTunnel_aktiv 0;
BA_ "GenSigSendType" SG_ 2463978889 Mem_HBFSFo_BANV_aktiv 3;
BA_ "GenSigSwitchedByIgnition" SG_ 2463978889 Mem_HBFSFo_BANV_aktiv 0;
BA_ "GenSigSendType" SG_ 2463978889 Mem_HBFSFo_BATV_aktiv 3;
BA_ "GenSigSwitchedByIgnition" SG_ 2463978889 Mem_HBFSFo_BATV_aktiv 0;
BA_ "GenSigSendType" SG_ 2463978889 Mem_HBFSFo_EE_Entriegl_Motor 3;
BA_ "GenSigSwitchedByIgnition" SG_ 2463978889 Mem_HBFSFo_EE_Entriegl_Motor 0;
BA_ "GenSigSendType" SG_ 2463978889 Mem_HBFSFo_EE_Verr_Sensor_re 3;
BA_ "GenSigSwitchedByIgnition" SG_ 2463978889 Mem_HBFSFo_EE_Verr_Sensor_re 0;
BA_ "Fehlerwert" SG_ 2463978889 Mem_HBFSFo_EE_Verr_Sensor_re 5;
BA_ "GenSigSendType" SG_ 2463978889 Mem_HBFSFo_globaler_Lehnenwinkel 0;
BA_ "GenSigStartValue" SG_ 2463978889 Mem_HBFSFo_globaler_Lehnenwinkel 254;
BA_ "GenSigSwitchedByIgnition" SG_ 2463978889 Mem_HBFSFo_globaler_Lehnenwinkel 0;
BA_ "Fehlerwert" SG_ 2463978889 Mem_HBFSFo_globaler_Lehnenwinkel 255;
BA_ "GenSigSendType" SG_ 2463978889 Mem_HBFSFo_globaler_Sitzflachenw 0;
BA_ "GenSigStartValue" SG_ 2463978889 Mem_HBFSFo_globaler_Sitzflachenw 254;
BA_ "GenSigSwitchedByIgnition" SG_ 2463978889 Mem_HBFSFo_globaler_Sitzflachenw 0;
BA_ "Fehlerwert" SG_ 2463978889 Mem_HBFSFo_globaler_Sitzflachenw 255;
BA_ "GenSigSendType" SG_ 2463978889 Mem_HBFSFo_KSV_aktiv 3;
BA_ "GenSigSwitchedByIgnition" SG_ 2463978889 Mem_HBFSFo_KSV_aktiv 0;
BA_ "GenSigSendType" SG_ 2463978889 Mem_HBFSFo_LED_EA_Taster 3;
BA_ "GenSigSwitchedByIgnition" SG_ 2463978889 Mem_HBFSFo_LED_EA_Taster 0;
BA_ "GenSigSendType" SG_ 2463978889 Mem_HBFSFo_LKV_aktiv 3;
BA_ "GenSigSwitchedByIgnition" SG_ 2463978889 Mem_HBFSFo_LKV_aktiv 0;
BA_ "GenSigSendType" SG_ 2463978889 Mem_HBFSFo_LNV_aktiv 3;
BA_ "GenSigSwitchedByIgnition" SG_ 2463978889 Mem_HBFSFo_LNV_aktiv 0;
BA_ "GenSigSendType" SG_ 2463978889 Mem_HBFSFo_SHV_aktiv 3;
BA_ "GenSigSwitchedByIgnition" SG_ 2463978889 Mem_HBFSFo_SHV_aktiv 0;
BA_ "GenSigSendType" SG_ 2463978889 Mem_HBFSFo_SLV_aktiv 3;
BA_ "GenSigSwitchedByIgnition" SG_ 2463978889 Mem_HBFSFo_SLV_aktiv 0;
BA_ "GenSigSendType" SG_ 2463978889 Mem_HBFSFo_SLV_hinten 3;
BA_ "GenSigSwitchedByIgnition" SG_ 2463978889 Mem_HBFSFo_SLV_hinten 0;
BA_ "GenSigSendType" SG_ 2463978889 Mem_HBFSFo_SNV_aktiv 3;
BA_ "GenSigSwitchedByIgnition" SG_ 2463978889 Mem_HBFSFo_SNV_aktiv 0;
BA_ "GenSigSendType" SG_ 2463978889 Mem_HBFSFo_Sperre_Sitzdisplay 3;
BA_ "GenSigSwitchedByIgnition" SG_ 2463978889 Mem_HBFSFo_Sperre_Sitzdisplay 0;
BA_ "GenSigSendType" SG_ 2463978889 Mem_HBFSFo_Status_Schalter_Ki_Si 3;
BA_ "GenSigStartValue" SG_ 2463978889 Mem_HBFSFo_Status_Schalter_Ki_Si 2;
BA_ "GenSigSwitchedByIgnition" SG_ 2463978889 Mem_HBFSFo_Status_Schalter_Ki_Si 0;
BA_ "Fehlerwert" SG_ 2463978889 Mem_HBFSFo_Status_Schalter_Ki_Si 3;
BA_ "GenSigSendType" SG_ 2463978889 Mem_HBFSFo_Stoerung 3;
BA_ "GenSigSwitchedByIgnition" SG_ 2463978889 Mem_HBFSFo_Stoerung 0;
BA_ "GenSigSendType" SG_ 2463978889 Mem_HBFSFo_STV_aktiv 3;
BA_ "GenSigSwitchedByIgnition" SG_ 2463978889 Mem_HBFSFo_STV_aktiv 0;
BA_ "GenSigSendType" SG_ 2463978889 Mem_HBFSFo_Verr_Sensor_oben_re 3;
BA_ "GenSigSwitchedByIgnition" SG_ 2463978889 Mem_HBFSFo_Verr_Sensor_oben_re 0;
BA_ "Fehlerwert" SG_ 2463978889 Mem_HBFSFo_Verr_Sensor_oben_re 5;
BA_ "GenSigSendType" SG_ 2463978889 Mem_HBFSFo_Verr_Sensor_unten_re 3;
BA_ "GenSigSwitchedByIgnition" SG_ 2463978889 Mem_HBFSFo_Verr_Sensor_unten_re 0;
BA_ "Fehlerwert" SG_ 2463978889 Mem_HBFSFo_Verr_Sensor_unten_re 5;
BA_ "GenSigSendType" SG_ 2463978889 Mem_HBFSFo_Warnung_Softstop 3;
BA_ "GenSigSwitchedByIgnition" SG_ 2463978889 Mem_HBFSFo_Warnung_Softstop 0;
BA_ "Fehlerwert" SG_ 2463978889 Mem_HBFSFo_Warnung_Softstop 3;
BA_ "GenSigSendType" SG_ 1178 FS_BFS_Fond_Verst_enable 3;
BA_ "GenSigSwitchedByIgnition" SG_ 1178 FS_BFS_Fond_Verst_enable 0;
BA_ "GenSigSendType" SG_ 1178 FS_BFS_KSS_Anfahrt 3;
BA_ "GenSigSwitchedByIgnition" SG_ 1178 FS_BFS_KSS_Anfahrt 0;
BA_ "GenSigSendType" SG_ 1178 FS_BFS_Sitzsym_Anfahrt 3;
BA_ "GenSigSwitchedByIgnition" SG_ 1178 FS_BFS_Sitzsym_Anfahrt 0;
BA_ "GenSigSendType" SG_ 1178 FS_EE_BFS_enable 3;
BA_ "GenSigSwitchedByIgnition" SG_ 1178 FS_EE_BFS_enable 0;
BA_ "GenSigSendType" SG_ 1178 FS_EE_Fond_BFS_enable 3;
BA_ "GenSigSwitchedByIgnition" SG_ 1178 FS_EE_Fond_BFS_enable 0;
BA_ "GenSigSendType" SG_ 1178 FS_EE_Fond_FS_enable 3;
BA_ "GenSigSwitchedByIgnition" SG_ 1178 FS_EE_Fond_FS_enable 0;
BA_ "GenSigSendType" SG_ 1178 FS_Fond_Bed_enable 3;
BA_ "GenSigSwitchedByIgnition" SG_ 1178 FS_Fond_Bed_enable 0;
BA_ "GenSigSendType" SG_ 1178 FS_GHV_aktiv 3;
BA_ "GenSigSwitchedByIgnition" SG_ 1178 FS_GHV_aktiv 0;
BA_ "GenSigSendType" SG_ 1178 FS_Gurtbringer_Sperre 0;
BA_ "GenSigSwitchedByIgnition" SG_ 1178 FS_Gurtbringer_Sperre 0;
BA_ "GenSigSendType" SG_ 1178 FS_KSV_aktiv 3;
BA_ "GenSigSwitchedByIgnition" SG_ 1178 FS_KSV_aktiv 0;
BA_ "GenSigSendType" SG_ 1178 FS_Lehne_nicht_verriegelt 3;
BA_ "GenSigSwitchedByIgnition" SG_ 1178 FS_Lehne_nicht_verriegelt 0;
BA_ "GenSigSendType" SG_ 1178 FS_LHV_aktiv 3;
BA_ "GenSigSwitchedByIgnition" SG_ 1178 FS_LHV_aktiv 0;
BA_ "GenSigSendType" SG_ 1178 FS_LKV_aktiv 3;
BA_ "GenSigSwitchedByIgnition" SG_ 1178 FS_LKV_aktiv 0;
BA_ "GenSigSendType" SG_ 1178 FS_LNV_aktiv 3;
BA_ "GenSigSwitchedByIgnition" SG_ 1178 FS_LNV_aktiv 0;
BA_ "GenSigSendType" SG_ 1178 FS_LWV_aktiv 3;
BA_ "GenSigSwitchedByIgnition" SG_ 1178 FS_LWV_aktiv 0;
BA_ "GenSigSendType" SG_ 1178 FS_MMB_glob_stop 3;
BA_ "GenSigSwitchedByIgnition" SG_ 1178 FS_MMB_glob_stop 0;
BA_ "GenSigSendType" SG_ 1178 FS_MMB_lokal_Stop 3;
BA_ "GenSigSwitchedByIgnition" SG_ 1178 FS_MMB_lokal_Stop 0;
BA_ "GenSigSendType" SG_ 1178 FS_MMB_storage 3;
BA_ "GenSigSwitchedByIgnition" SG_ 1178 FS_MMB_storage 0;
BA_ "GenSigSendType" SG_ 1178 FS_MMB_storage_beep 3;
BA_ "GenSigSwitchedByIgnition" SG_ 1178 FS_MMB_storage_beep 0;
BA_ "GenSigSendType" SG_ 1178 FS_MMB_store 3;
BA_ "GenSigSwitchedByIgnition" SG_ 1178 FS_MMB_store 0;
BA_ "GenSigSendType" SG_ 1178 FS_MMB_store_LED_on 3;
BA_ "GenSigSwitchedByIgnition" SG_ 1178 FS_MMB_store_LED_on 0;
BA_ "GenSigSendType" SG_ 1178 FS_MMB_tast 3;
BA_ "GenSigSwitchedByIgnition" SG_ 1178 FS_MMB_tast 0;
BA_ "GenSigSendType" SG_ 1178 FS_MMB_tipp 3;
BA_ "GenSigSwitchedByIgnition" SG_ 1178 FS_MMB_tipp 0;
BA_ "GenSigSendType" SG_ 1178 FS_SHV_aktiv 3;
BA_ "GenSigSwitchedByIgnition" SG_ 1178 FS_SHV_aktiv 0;
BA_ "GenSigSendType" SG_ 1178 FS_Sitzfahrt_aktiv 3;
BA_ "GenSigSwitchedByIgnition" SG_ 1178 FS_Sitzfahrt_aktiv 0;
BA_ "GenSigSendType" SG_ 1178 FS_SLV_aktiv 3;
BA_ "GenSigSwitchedByIgnition" SG_ 1178 FS_SLV_aktiv 0;
BA_ "GenSigSendType" SG_ 1178 FS_SNV_aktiv 3;
BA_ "GenSigSwitchedByIgnition" SG_ 1178 FS_SNV_aktiv 0;
BA_ "GenSigSendType" SG_ 1178 FS_Spezialposition_anfahren 3;
BA_ "GenSigSwitchedByIgnition" SG_ 1178 FS_Spezialposition_anfahren 0;
BA_ "GenSigSendType" SG_ 1178 FS_STV_aktiv 3;
BA_ "GenSigSwitchedByIgnition" SG_ 1178 FS_STV_aktiv 0;
BA_ "GenSigSendType" SG_ 1178 Mem_FS_01_MQB_BZ 0;
BA_ "GenSigFuncType" SG_ 1178 Mem_FS_01_MQB_BZ 1;
BA_ "GenSigSwitchedByIgnition" SG_ 1178 Mem_FS_01_MQB_BZ 0;
BA_ "GenSigSendType" SG_ 1178 Mem_FS_01_MQB_CRC 0;
BA_ "GenSigFuncType" SG_ 1178 Mem_FS_01_MQB_CRC 2;
BA_ "GenSigSwitchedByIgnition" SG_ 1178 Mem_FS_01_MQB_CRC 0;
BA_ "GenSigSendType" SG_ 956 Mem_FS_Fond_01_BZ 0;
BA_ "GenSigFuncType" SG_ 956 Mem_FS_Fond_01_BZ 1;
BA_ "GenSigSwitchedByIgnition" SG_ 956 Mem_FS_Fond_01_BZ 0;
BA_ "GenSigSendType" SG_ 956 Mem_FS_Fond_01_CRC 0;
BA_ "GenSigFuncType" SG_ 956 Mem_FS_Fond_01_CRC 2;
BA_ "GenSigSwitchedByIgnition" SG_ 956 Mem_FS_Fond_01_CRC 0;
BA_ "GenSigSendType" SG_ 956 Mem_FSFo_Business_anfahren 3;
BA_ "GenSigSwitchedByIgnition" SG_ 956 Mem_FSFo_Business_anfahren 0;
BA_ "GenSigSendType" SG_ 956 Mem_FSFo_Lordose_hoch 3;
BA_ "GenSigSwitchedByIgnition" SG_ 956 Mem_FSFo_Lordose_hoch 0;
BA_ "GenSigSendType" SG_ 956 Mem_FSFo_Lordose_runter 3;
BA_ "GenSigSwitchedByIgnition" SG_ 956 Mem_FSFo_Lordose_runter 0;
BA_ "GenSigSendType" SG_ 956 Mem_FSFo_Lordose_vor 3;
BA_ "GenSigSwitchedByIgnition" SG_ 956 Mem_FSFo_Lordose_vor 0;
BA_ "GenSigSendType" SG_ 956 Mem_FSFo_Lordose_zurueck 3;
BA_ "GenSigSwitchedByIgnition" SG_ 956 Mem_FSFo_Lordose_zurueck 0;
BA_ "GenSigSendType" SG_ 956 Mem_FSFo_Massage_Geschw 3;
BA_ "GenSigSwitchedByIgnition" SG_ 956 Mem_FSFo_Massage_Geschw 0;
BA_ "GenSigSendType" SG_ 956 Mem_FSFo_Massage_Intens 3;
BA_ "GenSigSwitchedByIgnition" SG_ 956 Mem_FSFo_Massage_Intens 0;
BA_ "GenSigSendType" SG_ 956 Mem_FSFo_Massage_Prg 3;
BA_ "GenSigSwitchedByIgnition" SG_ 956 Mem_FSFo_Massage_Prg 0;
BA_ "GenSigSendType" SG_ 956 Mem_FSFo_MMB_glob_Stop 3;
BA_ "GenSigSwitchedByIgnition" SG_ 956 Mem_FSFo_MMB_glob_Stop 0;
BA_ "GenSigSendType" SG_ 956 Mem_FSFo_MMB_lokal_Stop 3;
BA_ "GenSigSwitchedByIgnition" SG_ 956 Mem_FSFo_MMB_lokal_Stop 0;
BA_ "GenSigSendType" SG_ 956 Mem_FSFo_MMB_storage 3;
BA_ "GenSigSwitchedByIgnition" SG_ 956 Mem_FSFo_MMB_storage 0;
BA_ "GenSigSendType" SG_ 956 Mem_FSFo_MMB_storage_beep 3;
BA_ "GenSigSwitchedByIgnition" SG_ 956 Mem_FSFo_MMB_storage_beep 0;
BA_ "GenSigSendType" SG_ 956 Mem_FSFo_MMB_store 3;
BA_ "GenSigSwitchedByIgnition" SG_ 956 Mem_FSFo_MMB_store 0;
BA_ "GenSigSendType" SG_ 956 Mem_FSFo_MMB_store_LED_on 3;
BA_ "GenSigSwitchedByIgnition" SG_ 956 Mem_FSFo_MMB_store_LED_on 0;
BA_ "GenSigSendType" SG_ 956 Mem_FSFo_MMB_tast 3;
BA_ "GenSigSwitchedByIgnition" SG_ 956 Mem_FSFo_MMB_tast 0;
BA_ "GenSigSendType" SG_ 956 Mem_FSFo_MMB_tipp 3;
BA_ "GenSigSwitchedByIgnition" SG_ 956 Mem_FSFo_MMB_tipp 0;
BA_ "GenSigSendType" SG_ 956 Mem_FSFo_Relax_anfahren 3;
BA_ "GenSigSwitchedByIgnition" SG_ 956 Mem_FSFo_Relax_anfahren 0;
BA_ "GenSigSendType" SG_ 956 Mem_FSFo_Sitzfahrt_aktiv 3;
BA_ "GenSigSwitchedByIgnition" SG_ 956 Mem_FSFo_Sitzfahrt_aktiv 0;
BA_ "GenSigSendType" SG_ 956 Mem_FSFo_Sitztiefe_vor 3;
BA_ "GenSigSwitchedByIgnition" SG_ 956 Mem_FSFo_Sitztiefe_vor 0;
BA_ "GenSigSendType" SG_ 956 Mem_FSFo_Sitztiefe_zur 3;
BA_ "GenSigSwitchedByIgnition" SG_ 956 Mem_FSFo_Sitztiefe_zur 0;
BA_ "GenSigSendType" SG_ 956 Mem_FSFo_Warn_Dreh_entriegelt 3;
BA_ "GenSigSwitchedByIgnition" SG_ 956 Mem_FSFo_Warn_Dreh_entriegelt 0;
BA_ "GenSigSendType" SG_ 956 Mem_FSFo_Warn_Verriegelung 3;
BA_ "GenSigSwitchedByIgnition" SG_ 956 Mem_FSFo_Warn_Verriegelung 0;
BA_ "GenSigSendType" SG_ 956 Mem_HFS_Seat_Attention 3;
BA_ "GenSigSwitchedByIgnition" SG_ 956 Mem_HFS_Seat_Attention 0;
BA_ "Fehlerwert" SG_ 956 Mem_HFS_Seat_Attention 7;
BA_ "GenSigSendType" SG_ 956 Mem_HFSFo_EA_Taster 3;
BA_ "GenSigSwitchedByIgnition" SG_ 956 Mem_HFSFo_EA_Taster 0;
BA_ "GenSigSendType" SG_ 956 Mem_HFSFo_Unlocked 3;
BA_ "GenSigSwitchedByIgnition" SG_ 956 Mem_HFSFo_Unlocked 0;
BA_ "GenSigSendType" SG_ 2463978890 Mem_FS_Fond_03_BZ 0;
BA_ "GenSigFuncType" SG_ 2463978890 Mem_FS_Fond_03_BZ 1;
BA_ "GenSigSwitchedByIgnition" SG_ 2463978890 Mem_FS_Fond_03_BZ 0;
BA_ "GenSigSendType" SG_ 2463978890 Mem_FS_Fond_03_CRC 0;
BA_ "GenSigFuncType" SG_ 2463978890 Mem_FS_Fond_03_CRC 2;
BA_ "GenSigSwitchedByIgnition" SG_ 2463978890 Mem_FS_Fond_03_CRC 0;
BA_ "GenSigSendType" SG_ 2463978890 Mem_HFSFo_Abschaltanf_SRAB 3;
BA_ "GenSigStartValue" SG_ 2463978890 Mem_HFSFo_Abschaltanf_SRAB 2;
BA_ "GenSigSwitchedByIgnition" SG_ 2463978890 Mem_HFSFo_Abschaltanf_SRAB 0;
BA_ "Fehlerwert" SG_ 2463978890 Mem_HFSFo_Abschaltanf_SRAB 3;
BA_ "GenSigSendType" SG_ 2463978890 Mem_HFSFo_Anzeige_Komfort_HFS 3;
BA_ "GenSigSwitchedByIgnition" SG_ 2463978890 Mem_HFSFo_Anzeige_Komfort_HFS 0;
BA_ "GenSigSendType" SG_ 2463978890 Mem_HFSFo_ARMTuer_aktiv 3;
BA_ "GenSigSwitchedByIgnition" SG_ 2463978890 Mem_HFSFo_ARMTuer_aktiv 0;
BA_ "GenSigSendType" SG_ 2463978890 Mem_HFSFo_ARMTunnel_aktiv 3;
BA_ "GenSigSwitchedByIgnition" SG_ 2463978890 Mem_HFSFo_ARMTunnel_aktiv 0;
BA_ "GenSigSendType" SG_ 2463978890 Mem_HFSFo_BANV_aktiv 3;
BA_ "GenSigSwitchedByIgnition" SG_ 2463978890 Mem_HFSFo_BANV_aktiv 0;
BA_ "GenSigSendType" SG_ 2463978890 Mem_HFSFo_BATV_aktiv 3;
BA_ "GenSigSwitchedByIgnition" SG_ 2463978890 Mem_HFSFo_BATV_aktiv 0;
BA_ "GenSigSendType" SG_ 2463978890 Mem_HFSFo_EA_Position 3;
BA_ "GenSigSwitchedByIgnition" SG_ 2463978890 Mem_HFSFo_EA_Position 0;
BA_ "GenSigSendType" SG_ 2463978890 Mem_HFSFo_EE_Verr_Sensor_li 3;
BA_ "GenSigSwitchedByIgnition" SG_ 2463978890 Mem_HFSFo_EE_Verr_Sensor_li 0;
BA_ "Fehlerwert" SG_ 2463978890 Mem_HFSFo_EE_Verr_Sensor_li 5;
BA_ "GenSigSendType" SG_ 2463978890 Mem_HFSFo_globaler_Lehnenwinkel 0;
BA_ "GenSigStartValue" SG_ 2463978890 Mem_HFSFo_globaler_Lehnenwinkel 254;
BA_ "GenSigSwitchedByIgnition" SG_ 2463978890 Mem_HFSFo_globaler_Lehnenwinkel 0;
BA_ "Fehlerwert" SG_ 2463978890 Mem_HFSFo_globaler_Lehnenwinkel 255;
BA_ "GenSigSendType" SG_ 2463978890 Mem_HFSFo_globaler_Sitzflachenwi 0;
BA_ "GenSigStartValue" SG_ 2463978890 Mem_HFSFo_globaler_Sitzflachenwi 254;
BA_ "GenSigSwitchedByIgnition" SG_ 2463978890 Mem_HFSFo_globaler_Sitzflachenwi 0;
BA_ "Fehlerwert" SG_ 2463978890 Mem_HFSFo_globaler_Sitzflachenwi 255;
BA_ "GenSigSendType" SG_ 2463978890 Mem_HFSFo_KSV_aktiv 3;
BA_ "GenSigSwitchedByIgnition" SG_ 2463978890 Mem_HFSFo_KSV_aktiv 0;
BA_ "GenSigSendType" SG_ 2463978890 Mem_HFSFo_LED_EA_Taster 3;
BA_ "GenSigSwitchedByIgnition" SG_ 2463978890 Mem_HFSFo_LED_EA_Taster 0;
BA_ "GenSigSendType" SG_ 2463978890 Mem_HFSFo_LKV_aktiv 3;
BA_ "GenSigSwitchedByIgnition" SG_ 2463978890 Mem_HFSFo_LKV_aktiv 0;
BA_ "GenSigSendType" SG_ 2463978890 Mem_HFSFo_LNV_aktiv 3;
BA_ "GenSigSwitchedByIgnition" SG_ 2463978890 Mem_HFSFo_LNV_aktiv 0;
BA_ "GenSigSendType" SG_ 2463978890 Mem_HFSFo_SHV_aktiv 3;
BA_ "GenSigSwitchedByIgnition" SG_ 2463978890 Mem_HFSFo_SHV_aktiv 0;
BA_ "GenSigSendType" SG_ 2463978890 Mem_HFSFo_SLV_aktiv 3;
BA_ "GenSigSwitchedByIgnition" SG_ 2463978890 Mem_HFSFo_SLV_aktiv 0;
BA_ "GenSigSendType" SG_ 2463978890 Mem_HFSFo_SLV_hinten 3;
BA_ "GenSigSwitchedByIgnition" SG_ 2463978890 Mem_HFSFo_SLV_hinten 0;
BA_ "GenSigSendType" SG_ 2463978890 Mem_HFSFo_SNV_aktiv 3;
BA_ "GenSigSwitchedByIgnition" SG_ 2463978890 Mem_HFSFo_SNV_aktiv 0;
BA_ "GenSigSendType" SG_ 2463978890 Mem_HFSFo_Sperre_Sitzdisplay 3;
BA_ "GenSigSwitchedByIgnition" SG_ 2463978890 Mem_HFSFo_Sperre_Sitzdisplay 0;
BA_ "GenSigSendType" SG_ 2463978890 Mem_HFSFo_Status_Schalter_Ki_Si 3;
BA_ "GenSigStartValue" SG_ 2463978890 Mem_HFSFo_Status_Schalter_Ki_Si 2;
BA_ "GenSigSwitchedByIgnition" SG_ 2463978890 Mem_HFSFo_Status_Schalter_Ki_Si 0;
BA_ "Fehlerwert" SG_ 2463978890 Mem_HFSFo_Status_Schalter_Ki_Si 3;
BA_ "GenSigSendType" SG_ 2463978890 Mem_HFSFo_Stoerung 3;
BA_ "GenSigSwitchedByIgnition" SG_ 2463978890 Mem_HFSFo_Stoerung 0;
BA_ "GenSigSendType" SG_ 2463978890 Mem_HFSFo_STV_aktiv 3;
BA_ "GenSigSwitchedByIgnition" SG_ 2463978890 Mem_HFSFo_STV_aktiv 0;
BA_ "GenSigSendType" SG_ 2463978890 Mem_HFSFo_Verr_Sensor_oben_li 3;
BA_ "GenSigSwitchedByIgnition" SG_ 2463978890 Mem_HFSFo_Verr_Sensor_oben_li 0;
BA_ "Fehlerwert" SG_ 2463978890 Mem_HFSFo_Verr_Sensor_oben_li 5;
BA_ "GenSigSendType" SG_ 2463978890 Mem_HFSFo_Verr_Sensor_unten_li 3;
BA_ "GenSigSwitchedByIgnition" SG_ 2463978890 Mem_HFSFo_Verr_Sensor_unten_li 0;
BA_ "Fehlerwert" SG_ 2463978890 Mem_HFSFo_Verr_Sensor_unten_li 5;
BA_ "GenSigSendType" SG_ 2463978890 Mem_HFSFo_Warnung_Softstop 3;
BA_ "GenSigSwitchedByIgnition" SG_ 2463978890 Mem_HFSFo_Warnung_Softstop 0;
BA_ "Fehlerwert" SG_ 2463978890 Mem_HFSFo_Warnung_Softstop 3;
BA_ "GenSigSendType" SG_ 1171 MF_Abzugssperre 3;
BA_ "GenSigSwitchedByIgnition" SG_ 1171 MF_Abzugssperre 0;
BA_ "GenSigSendType" SG_ 1171 MF_Alarm_Blinker 3;
BA_ "GenSigSwitchedByIgnition" SG_ 1171 MF_Alarm_Blinker 0;
BA_ "GenSigSendType" SG_ 1171 MF_Alarm_Blinkertakt 3;
BA_ "GenSigSwitchedByIgnition" SG_ 1171 MF_Alarm_Blinkertakt 0;
BA_ "GenSigSendType" SG_ 1171 MF_Anlassersperre 3;
BA_ "GenSigSwitchedByIgnition" SG_ 1171 MF_Anlassersperre 0;
BA_ "GenSigSendType" SG_ 1171 MF_Blk_li 3;
BA_ "GenSigSwitchedByIgnition" SG_ 1171 MF_Blk_li 0;
BA_ "GenSigSendType" SG_ 1171 MF_Blk_re 3;
BA_ "GenSigSwitchedByIgnition" SG_ 1171 MF_Blk_re 0;
BA_ "GenSigSendType" SG_ 1171 MF_BT_entriegeln 3;
BA_ "GenSigSwitchedByIgnition" SG_ 1171 MF_BT_entriegeln 0;
BA_ "GenSigSendType" SG_ 1171 MF_BT_verriegeln 3;
BA_ "GenSigSwitchedByIgnition" SG_ 1171 MF_BT_verriegeln 0;
BA_ "GenSigSendType" SG_ 1171 MF_Fahrlicht 3;
BA_ "GenSigSwitchedByIgnition" SG_ 1171 MF_Fahrlicht 0;
BA_ "GenSigSendType" SG_ 1171 MF_Fernbed_ein 3;
BA_ "GenSigSwitchedByIgnition" SG_ 1171 MF_Fernbed_ein 0;
BA_ "GenSigSendType" SG_ 1171 MF_Fernlicht 3;
BA_ "GenSigSwitchedByIgnition" SG_ 1171 MF_Fernlicht 0;
BA_ "GenSigSendType" SG_ 1171 MF_FH_BT_hoch 3;
BA_ "GenSigSwitchedByIgnition" SG_ 1171 MF_FH_BT_hoch 0;
BA_ "GenSigSendType" SG_ 1171 MF_FH_BT_tief 3;
BA_ "GenSigSwitchedByIgnition" SG_ 1171 MF_FH_BT_tief 0;
BA_ "GenSigSendType" SG_ 1171 MF_FH_FT_hoch 3;
BA_ "GenSigSwitchedByIgnition" SG_ 1171 MF_FH_FT_hoch 0;
BA_ "GenSigSendType" SG_ 1171 MF_FH_FT_tief 3;
BA_ "GenSigSwitchedByIgnition" SG_ 1171 MF_FH_FT_tief 0;
BA_ "GenSigSendType" SG_ 1171 MF_Frontintervall 3;
BA_ "GenSigSwitchedByIgnition" SG_ 1171 MF_Frontintervall 0;
BA_ "GenSigSendType" SG_ 1171 MF_Frontwaschen 3;
BA_ "GenSigSwitchedByIgnition" SG_ 1171 MF_Frontwaschen 0;
BA_ "GenSigSendType" SG_ 1171 MF_FT_entriegeln 3;
BA_ "GenSigSwitchedByIgnition" SG_ 1171 MF_FT_entriegeln 0;
BA_ "GenSigSendType" SG_ 1171 MF_FT_verriegeln 3;
BA_ "GenSigSwitchedByIgnition" SG_ 1171 MF_FT_verriegeln 0;
BA_ "GenSigSendType" SG_ 1171 MF_Fussraumbel 3;
BA_ "GenSigSwitchedByIgnition" SG_ 1171 MF_Fussraumbel 0;
BA_ "GenSigSendType" SG_ 1171 MF_HBFS_entriegeln 3;
BA_ "GenSigSwitchedByIgnition" SG_ 1171 MF_HBFS_entriegeln 0;
BA_ "GenSigSendType" SG_ 1171 MF_HBFS_verriegeln 3;
BA_ "GenSigSwitchedByIgnition" SG_ 1171 MF_HBFS_verriegeln 0;
BA_ "GenSigSendType" SG_ 1171 MF_Heckintervall 3;
BA_ "GenSigSwitchedByIgnition" SG_ 1171 MF_Heckintervall 0;
BA_ "GenSigSendType" SG_ 1171 MF_Heckwaschen 3;
BA_ "GenSigSwitchedByIgnition" SG_ 1171 MF_Heckwaschen 0;
BA_ "GenSigSendType" SG_ 1171 MF_HFS_entriegeln 3;
BA_ "GenSigSwitchedByIgnition" SG_ 1171 MF_HFS_entriegeln 0;
BA_ "GenSigSendType" SG_ 1171 MF_HFS_verriegeln 3;
BA_ "GenSigSwitchedByIgnition" SG_ 1171 MF_HFS_verriegeln 0;
BA_ "GenSigSendType" SG_ 1171 MF_Innenraumbel 3;
BA_ "GenSigSwitchedByIgnition" SG_ 1171 MF_Innenraumbel 0;
BA_ "GenSigSendType" SG_ 1171 MF_Innenraumbel_Unterdrueck 3;
BA_ "GenSigSwitchedByIgnition" SG_ 1171 MF_Innenraumbel_Unterdrueck 0;
BA_ "GenSigSendType" SG_ 1171 MF_interm_Fahrlicht 3;
BA_ "GenSigSwitchedByIgnition" SG_ 1171 MF_interm_Fahrlicht 0;
BA_ "GenSigSendType" SG_ 1171 MF_interm_Fernlicht 3;
BA_ "GenSigSwitchedByIgnition" SG_ 1171 MF_interm_Fernlicht 0;
BA_ "GenSigSendType" SG_ 1171 MF_interm_Takt 3;
BA_ "GenSigSwitchedByIgnition" SG_ 1171 MF_interm_Takt 0;
BA_ "GenSigSendType" SG_ 1171 MF_Laderelais 3;
BA_ "GenSigSwitchedByIgnition" SG_ 1171 MF_Laderelais 0;
BA_ "GenSigSendType" SG_ 1171 MF_Lichthupe 3;
BA_ "GenSigSwitchedByIgnition" SG_ 1171 MF_Lichthupe 0;
BA_ "GenSigSendType" SG_ 1171 MF_Motorweiterlauf 3;
BA_ "GenSigSwitchedByIgnition" SG_ 1171 MF_Motorweiterlauf 0;
BA_ "GenSigSendType" SG_ 1171 MF_nachtr_Stopp_Anf 0;
BA_ "GenSigSwitchedByIgnition" SG_ 1171 MF_nachtr_Stopp_Anf 0;
BA_ "GenSigSendType" SG_ 1171 MF_Notstart 3;
BA_ "GenSigSwitchedByIgnition" SG_ 1171 MF_Notstart 0;
BA_ "GenSigSendType" SG_ 1171 MF_Schluessel_scan 3;
BA_ "GenSigSwitchedByIgnition" SG_ 1171 MF_Schluessel_scan 0;
BA_ "GenSigSendType" SG_ 1171 MF_Signalhorn 3;
BA_ "GenSigSwitchedByIgnition" SG_ 1171 MF_Signalhorn 0;
BA_ "GenSigSendType" SG_ 1171 MF_Standlicht 3;
BA_ "GenSigSwitchedByIgnition" SG_ 1171 MF_Standlicht 0;
BA_ "GenSigSendType" SG_ 1171 MF_StartStopp_Info 0;
BA_ "GenSigSwitchedByIgnition" SG_ 1171 MF_StartStopp_Info 0;
BA_ "GenSigSendType" SG_ 1171 MF_Summer 3;
BA_ "GenSigSwitchedByIgnition" SG_ 1171 MF_Summer 0;
BA_ "GenSigSendType" SG_ 1171 MF_TFL_Abschaltung 3;
BA_ "GenSigSwitchedByIgnition" SG_ 1171 MF_TFL_Abschaltung 0;
BA_ "GenSigSendType" SG_ 1171 MF_Tippwischen 3;
BA_ "GenSigSwitchedByIgnition" SG_ 1171 MF_Tippwischen 0;
BA_ "GenSigSendType" SG_ 1171 MF_Tuerentriegelung_hinten 3;
BA_ "GenSigSwitchedByIgnition" SG_ 1171 MF_Tuerentriegelung_hinten 0;
BA_ "GenSigSendType" SG_ 1171 MF_Variante 3;
BA_ "GenSigSwitchedByIgnition" SG_ 1171 MF_Variante 0;
BA_ "GenSigSendType" SG_ 1171 MF_Warnblinker 3;
BA_ "GenSigSwitchedByIgnition" SG_ 1171 MF_Warnblinker 0;
BA_ "GenSigSendType" SG_ 1171 MF_Wischerstufe_1 3;
BA_ "GenSigSwitchedByIgnition" SG_ 1171 MF_Wischerstufe_1 0;
BA_ "GenSigSendType" SG_ 1171 MF_Wischerstufe_2 3;
BA_ "GenSigSwitchedByIgnition" SG_ 1171 MF_Wischerstufe_2 0;
BA_ "GenSigSendType" SG_ 1171 MF_ZV_Lock 3;
BA_ "GenSigSwitchedByIgnition" SG_ 1171 MF_ZV_Lock 0;
BA_ "GenSigSendType" SG_ 1171 MFG_01_BZ 0;
BA_ "GenSigFuncType" SG_ 1171 MFG_01_BZ 1;
BA_ "GenSigSwitchedByIgnition" SG_ 1171 MFG_01_BZ 0;
BA_ "GenSigSendType" SG_ 1171 MFG_01_CRC 0;
BA_ "GenSigFuncType" SG_ 1171 MFG_01_CRC 2;
BA_ "GenSigSwitchedByIgnition" SG_ 1171 MFG_01_CRC 0;
BA_ "GenSigSendType" SG_ 1165 MF_ADR_Anforderung 0;
BA_ "GenSigSendType" SG_ 1165 MF_ADR_Fahrpedalsperre 0;
BA_ "GenSigSwitchedByIgnition" SG_ 1165 MF_ADR_Fahrpedalsperre 0;
BA_ "GenSigSendType" SG_ 1165 MF_ADR_neg_Rampe 0;
BA_ "GenSigSwitchedByIgnition" SG_ 1165 MF_ADR_neg_Rampe 0;
BA_ "GenSigSendType" SG_ 1165 MF_ADR_pos_Rampe 0;
BA_ "GenSigSendType" SG_ 1165 MF_ADR_Solldrehzahl 0;
BA_ "GenSigSendType" SG_ 1165 MF_MFSS_aktiv 0;
BA_ "GenSigSendType" SG_ 1165 MF_MFSS_kodiert 0;
BA_ "GenSigSwitchedByIgnition" SG_ 1165 MF_MFSS_kodiert 0;
BA_ "GenSigSendType" SG_ 1165 MF_VBEG_Anforderung 0;
BA_ "GenSigSendType" SG_ 1165 MF_VBEG_Geschwindigkeit 0;
BA_ "GenSigStartValue" SG_ 1165 MF_VBEG_Geschwindigkeit 255;
BA_ "GenSigSendType" SG_ 1165 MFG_02_BZ 0;
BA_ "GenSigFuncType" SG_ 1165 MFG_02_BZ 1;
BA_ "GenSigSendType" SG_ 1165 MFG_02_CRC 0;
BA_ "GenSigFuncType" SG_ 1165 MFG_02_CRC 2;
BA_ "GenSigSendType" SG_ 1165 MFG_Heizstufe_LSH 0;
BA_ "GenSigSwitchedByIgnition" SG_ 1165 MFG_Heizstufe_LSH 0;
BA_ "Fehlerwert" SG_ 1165 MFG_Heizstufe_LSH 15;
BA_ "GenSigSendType" SG_ 1165 MFG_Status_SREG 0;
BA_ "GenSigSwitchedByIgnition" SG_ 1165 MFG_Status_SREG 0;
BA_ "GenSigSendType" SG_ 1165 MFG_Taster_SREG 0;
BA_ "GenSigStartValue" SG_ 1165 MFG_Taster_SREG 2;
BA_ "GenSigSwitchedByIgnition" SG_ 1165 MFG_Taster_SREG 0;
BA_ "Fehlerwert" SG_ 1165 MFG_Taster_SREG 3;
BA_ "GenSigSendType" SG_ 1165 MFG_Taster_VREG 0;
BA_ "GenSigStartValue" SG_ 1165 MFG_Taster_VREG 2;
BA_ "GenSigSwitchedByIgnition" SG_ 1165 MFG_Taster_VREG 0;
BA_ "Fehlerwert" SG_ 1165 MFG_Taster_VREG 3;
BA_ "GenSigSendType" SG_ 1165 MFG_Zuheizer_Freigabe 0;
BA_ "GenSigSwitchedByIgnition" SG_ 1165 MFG_Zuheizer_Freigabe 0;
BA_ "GenSigSendType" SG_ 1164 MF_2BatSOCzugering 0;
BA_ "GenSigSendType" SG_ 1164 MF_2BattAb 0;
BA_ "GenSigSendType" SG_ 1164 MF_2BattHlkAnf 0;
BA_ "GenSigSendType" SG_ 1164 MF_2BattLadWarn 0;
BA_ "GenSigSendType" SG_ 1164 MF_2BattLlaAnf 0;
BA_ "GenSigSendType" SG_ 1164 MF_2BattSpannungsAnf 0;
BA_ "GenSigSendType" SG_ 1164 MF_Batteriediagnose 0;
BA_ "GenSigSwitchedByIgnition" SG_ 1164 MF_Batteriediagnose 0;
BA_ "Fehlerwert" SG_ 1164 MF_Batteriediagnose 7;
BA_ "GenSigSendType" SG_ 1164 MF_Blinker_L_Sta 3;
BA_ "GenSigSwitchedByIgnition" SG_ 1164 MF_Blinker_L_Sta 0;
BA_ "GenSigSendType" SG_ 1164 MF_Blinker_R_Sta 3;
BA_ "GenSigSwitchedByIgnition" SG_ 1164 MF_Blinker_R_Sta 0;
BA_ "GenSigSendType" SG_ 1164 MF_ExterneLadungWarn 0;
BA_ "GenSigSendType" SG_ 1164 MF_Fahrerhinweis 0;
BA_ "GenSigSendType" SG_ 1164 MF_Generatordiagnose 0;
BA_ "GenSigStartValue" SG_ 1164 MF_Generatordiagnose 3;
BA_ "GenSigSwitchedByIgnition" SG_ 1164 MF_Generatordiagnose 0;
BA_ "GenSigSendType" SG_ 1164 MF_Heck_entriegeln 0;
BA_ "GenSigSendType" SG_ 1164 MF_Heck_verriegeln 0;
BA_ "GenSigSendType" SG_ 1164 MF_interm_Nebelscheinwerfer 0;
BA_ "GenSigSwitchedByIgnition" SG_ 1164 MF_interm_Nebelscheinwerfer 0;
BA_ "GenSigSendType" SG_ 1164 MF_Lampenausfall 0;
BA_ "GenSigSwitchedByIgnition" SG_ 1164 MF_Lampenausfall 0;
BA_ "GenSigSendType" SG_ 1164 MF_LSH_Abschaltstufe 0;
BA_ "GenSigSwitchedByIgnition" SG_ 1164 MF_LSH_Abschaltstufe 0;
BA_ "GenSigSendType" SG_ 1164 MF_LSH_Einschaltverbot 0;
BA_ "GenSigSwitchedByIgnition" SG_ 1164 MF_LSH_Einschaltverbot 0;
BA_ "GenSigSendType" SG_ 1164 MF_LSH_Zielzeit 0;
BA_ "GenSigStartValue" SG_ 1164 MF_LSH_Zielzeit 14;
BA_ "GenSigSwitchedByIgnition" SG_ 1164 MF_LSH_Zielzeit 0;
BA_ "Fehlerwert" SG_ 1164 MF_LSH_Zielzeit 15;
BA_ "GenSigSendType" SG_ 1164 MF_NotStartAktiv 0;
BA_ "GenSigSendType" SG_ 1164 MF_Radiomute 3;
BA_ "GenSigSwitchedByIgnition" SG_ 1164 MF_Radiomute 0;
BA_ "GenSigSendType" SG_ 1164 MF_Relais_2_Batterie 3;
BA_ "GenSigSwitchedByIgnition" SG_ 1164 MF_Relais_2_Batterie 0;
BA_ "GenSigSendType" SG_ 1164 MF_Tuerverriegelung_hinten 3;
BA_ "GenSigSwitchedByIgnition" SG_ 1164 MF_Tuerverriegelung_hinten 0;
BA_ "GenSigSendType" SG_ 1164 MF_ZV_Unlock 0;
BA_ "GenSigSwitchedByIgnition" SG_ 1164 MF_ZV_Unlock 0;
BA_ "GenSigSendType" SG_ 1164 MFG_AppConnect_Anf 4;
BA_ "GenSigSwitchedByIgnition" SG_ 1164 MFG_AppConnect_Anf 0;
BA_ "GenSigSendType" SG_ 1164 MFG_Infotainment_Autark 0;
BA_ "GenSigSwitchedByIgnition" SG_ 1164 MFG_Infotainment_Autark 0;
BA_ "GenSigSendType" SG_ 1164 MFG_Klappe_Status 0;
BA_ "GenSigSwitchedByIgnition" SG_ 1164 MFG_Klappe_Status 0;
BA_ "GenSigSendType" SG_ 1164 MFG_LSH_Ansteuerung 0;
BA_ "GenSigSwitchedByIgnition" SG_ 1164 MFG_LSH_Ansteuerung 0;
BA_ "GenSigSendType" SG_ 1164 MFG_LSH_Betriebsdauer 0;
BA_ "GenSigSwitchedByIgnition" SG_ 1164 MFG_LSH_Betriebsdauer 0;
BA_ "GenSigSendType" SG_ 1164 MFG_LSH_DBetr_Bestaet 0;
BA_ "GenSigSwitchedByIgnition" SG_ 1164 MFG_LSH_DBetr_Bestaet 0;
BA_ "GenSigSendType" SG_ 1164 MFG_LSH_DBetr_Ein 0;
BA_ "GenSigSwitchedByIgnition" SG_ 1164 MFG_LSH_DBetr_Ein 0;
BA_ "GenSigSendType" SG_ 2463978883 MF_DCDC_Istmodus 0;
BA_ "GenSigStartValue" SG_ 2463978883 MF_DCDC_Istmodus 7;
BA_ "GenSigSwitchedByIgnition" SG_ 2463978883 MF_DCDC_Istmodus 0;
BA_ "Fehlerwert" SG_ 2463978883 MF_DCDC_Istmodus 5;
BA_ "GenSigSendType" SG_ 2463978883 MF_Fahrerhinweis_2 0;
BA_ "GenSigSwitchedByIgnition" SG_ 2463978883 MF_Fahrerhinweis_2 0;
BA_ "GenSigSendType" SG_ 2463978883 MF_I_U_VorgabeZwang 0;
BA_ "GenSigSwitchedByIgnition" SG_ 2463978883 MF_I_U_VorgabeZwang 0;
BA_ "GenSigSendType" SG_ 2463978883 MF_U2Batt 0;
BA_ "GenSigStartValue" SG_ 2463978883 MF_U2Batt 255;
BA_ "GenSigSwitchedByIgnition" SG_ 2463978883 MF_U2Batt 0;
BA_ "GenSigSendType" SG_ 2463978883 MF_UBattVorgabe 0;
BA_ "GenSigStartValue" SG_ 2463978883 MF_UBattVorgabe 63;
BA_ "GenSigSwitchedByIgnition" SG_ 2463978883 MF_UBattVorgabe 0;
BA_ "GenSigSendType" SG_ 2463978883 MF_Vorfeldbel_Spiegel 0;
BA_ "GenSigSwitchedByIgnition" SG_ 2463978883 MF_Vorfeldbel_Spiegel 0;
BA_ "GenSigSendType" SG_ 1471 MFL_Eventcode_1 9;
BA_ "GenSigSwitchedByIgnition" SG_ 1471 MFL_Eventcode_1 0;
BA_ "GenSigSendType" SG_ 1471 MFL_Eventcode_2 9;
BA_ "GenSigSwitchedByIgnition" SG_ 1471 MFL_Eventcode_2 0;
BA_ "GenSigFuncType" SG_ 1471 MFL_Marke 8;
BA_ "GenSigSwitchedByIgnition" SG_ 1471 MFL_Marke 0;
BA_ "GenSigSendType" SG_ 1471 MFL_Tastencode_1 9;
BA_ "GenSigSwitchedByIgnition" SG_ 1471 MFL_Tastencode_1 0;
BA_ "GenSigSendType" SG_ 1471 MFL_Tastencode_2 9;
BA_ "GenSigSwitchedByIgnition" SG_ 1471 MFL_Tastencode_2 0;
BA_ "GenSigFuncType" SG_ 1471 MFL_Variante 8;
BA_ "GenSigSwitchedByIgnition" SG_ 1471 MFL_Variante 0;
BA_ "GenSigSendType" SG_ 1600 MO_Absperrventil_oeffnen 0;
BA_ "GenSigSwitchedByIgnition" SG_ 1600 MO_Absperrventil_oeffnen 0;
BA_ "GenSigSendType" SG_ 1600 MO_aktives_Getriebeheizen 0;
BA_ "GenSigSwitchedByIgnition" SG_ 1600 MO_aktives_Getriebeheizen 0;
BA_ "GenSigSendType" SG_ 1600 MO_Ansaugluft_Temp 0;
BA_ "GenSigStartValue" SG_ 1600 MO_Ansaugluft_Temp 254;
BA_ "GenSigSwitchedByIgnition" SG_ 1600 MO_Ansaugluft_Temp 0;
BA_ "Fehlerwert" SG_ 1600 MO_Ansaugluft_Temp 255;
BA_ "GenSigSendType" SG_ 1600 MO_Getriebe_kuehlen 0;
BA_ "GenSigSwitchedByIgnition" SG_ 1600 MO_Getriebe_kuehlen 0;
BA_ "GenSigSendType" SG_ 1600 MO_Heizungspumpenansteuerung 0;
BA_ "GenSigStartValue" SG_ 1600 MO_Heizungspumpenansteuerung 14;
BA_ "GenSigSwitchedByIgnition" SG_ 1600 MO_Heizungspumpenansteuerung 0;
BA_ "Fehlerwert" SG_ 1600 MO_Heizungspumpenansteuerung 13;
BA_ "GenSigSendType" SG_ 1600 MO_Hoeheninfo 0;
BA_ "GenSigSwitchedByIgnition" SG_ 1600 MO_Hoeheninfo 0;
BA_ "Fehlerwert" SG_ 1600 MO_Hoeheninfo 255;
BA_ "GenSigSendType" SG_ 1600 MO_HYB_Fehler_HV_Netz 0;
BA_ "GenSigSwitchedByIgnition" SG_ 1600 MO_HYB_Fehler_HV_Netz 0;
BA_ "GenSigSendType" SG_ 1600 MO_Kennfeldk 0;
BA_ "GenSigSwitchedByIgnition" SG_ 1600 MO_Kennfeldk 0;
BA_ "GenSigSendType" SG_ 1600 MO_KL15_Abschaltempfehlung 0;
BA_ "GenSigSwitchedByIgnition" SG_ 1600 MO_KL15_Abschaltempfehlung 0;
BA_ "GenSigSendType" SG_ 1600 MO_Kuehlmittel_Temp 0;
BA_ "GenSigStartValue" SG_ 1600 MO_Kuehlmittel_Temp 254;
BA_ "GenSigSwitchedByIgnition" SG_ 1600 MO_Kuehlmittel_Temp 0;
BA_ "Fehlerwert" SG_ 1600 MO_Kuehlmittel_Temp 255;
BA_ "GenSigSendType" SG_ 1600 MO_Mom_Traegheit_02 0;
BA_ "GenSigSwitchedByIgnition" SG_ 1600 MO_Mom_Traegheit_02 0;
BA_ "GenSigSendType" SG_ 1600 MO_Nachlaufzeit_Heizungspumpe 0;
BA_ "GenSigSwitchedByIgnition" SG_ 1600 MO_Nachlaufzeit_Heizungspumpe 0;
BA_ "GenSigSendType" SG_ 1600 MO_Oel_Temp 0;
BA_ "GenSigStartValue" SG_ 1600 MO_Oel_Temp 254;
BA_ "GenSigSwitchedByIgnition" SG_ 1600 MO_Oel_Temp 0;
BA_ "Fehlerwert" SG_ 1600 MO_Oel_Temp 255;
BA_ "GenSigSendType" SG_ 1600 MO_QBit_Ansaugluft_Temp 0;
BA_ "GenSigStartValue" SG_ 1600 MO_QBit_Ansaugluft_Temp 1;
BA_ "GenSigSwitchedByIgnition" SG_ 1600 MO_QBit_Ansaugluft_Temp 0;
BA_ "GenSigSendType" SG_ 1600 MO_QBit_Hoeheninfo 0;
BA_ "GenSigStartValue" SG_ 1600 MO_QBit_Hoeheninfo 1;
BA_ "GenSigSwitchedByIgnition" SG_ 1600 MO_QBit_Hoeheninfo 0;
BA_ "GenSigSendType" SG_ 1600 MO_QBit_Kuehlmittel_Temp 0;
BA_ "GenSigStartValue" SG_ 1600 MO_QBit_Kuehlmittel_Temp 1;
BA_ "GenSigSwitchedByIgnition" SG_ 1600 MO_QBit_Kuehlmittel_Temp 0;
BA_ "GenSigSendType" SG_ 1600 MO_QBit_Oel_Temp 0;
BA_ "GenSigStartValue" SG_ 1600 MO_QBit_Oel_Temp 1;
BA_ "GenSigSwitchedByIgnition" SG_ 1600 MO_QBit_Oel_Temp 0;
BA_ "GenSigSendType" SG_ 1600 MO_SpannungsAnf 0;
BA_ "GenSigSwitchedByIgnition" SG_ 1600 MO_SpannungsAnf 0;
BA_ "GenSigSendType" SG_ 1600 MO_Versionsinfo_02 0;
BA_ "GenSigSwitchedByIgnition" SG_ 1600 MO_Versionsinfo_02 0;
BA_ "GenSigSendType" SG_ 1607 MO_CO2_Faktor 0;
BA_ "GenSigSwitchedByIgnition" SG_ 1607 MO_CO2_Faktor 0;
BA_ "Fehlerwert" SG_ 1607 MO_CO2_Faktor 4095;
BA_ "GenSigSendType" SG_ 1607 MO_E85_Sensor 0;
BA_ "GenSigStartValue" SG_ 1607 MO_E85_Sensor 14;
BA_ "GenSigSwitchedByIgnition" SG_ 1607 MO_E85_Sensor 0;
BA_ "Fehlerwert" SG_ 1607 MO_E85_Sensor 15;
BA_ "GenSigSendType" SG_ 1607 MO_Ethanol_Spuelhinweis 0;
BA_ "GenSigSwitchedByIgnition" SG_ 1607 MO_Ethanol_Spuelhinweis 0;
BA_ "GenSigSendType" SG_ 1607 MO_ITM_Kuehlmittel_Temp 0;
BA_ "GenSigStartValue" SG_ 1607 MO_ITM_Kuehlmittel_Temp 1;
BA_ "GenSigSwitchedByIgnition" SG_ 1607 MO_ITM_Kuehlmittel_Temp 0;
BA_ "Fehlerwert" SG_ 1607 MO_ITM_Kuehlmittel_Temp 2;
BA_ "GenSigSendType" SG_ 1607 MO_Kraftstofffilter_Wasser 0;
BA_ "GenSigSwitchedByIgnition" SG_ 1607 MO_Kraftstofffilter_Wasser 0;
BA_ "GenSigSwitchedByIgnition" SG_ 1607 MO_MKB_01 0;
BA_ "GenSigSwitchedByIgnition" SG_ 1607 MO_MKB_02 0;
BA_ "GenSigSwitchedByIgnition" SG_ 1607 MO_MKB_03 0;
BA_ "GenSigSwitchedByIgnition" SG_ 1607 MO_MKB_04 0;
BA_ "GenSigSendType" SG_ 1607 MO_MKB_MUX 0;
BA_ "GenSigSwitchedByIgnition" SG_ 1607 MO_MKB_MUX 0;
BA_ "GenSigSendType" SG_ 1607 SCR_Akustik 0;
BA_ "GenSigSwitchedByIgnition" SG_ 1607 SCR_Akustik 0;
BA_ "GenSigSendType" SG_ 1607 SCR_Anz_Motorstarts 0;
BA_ "GenSigStartValue" SG_ 1607 SCR_Anz_Motorstarts 15;
BA_ "GenSigSwitchedByIgnition" SG_ 1607 SCR_Anz_Motorstarts 0;
BA_ "GenSigSendType" SG_ 1607 SCR_Inducement_Strategie 0;
BA_ "GenSigSwitchedByIgnition" SG_ 1607 SCR_Inducement_Strategie 0;
BA_ "GenSigSendType" SG_ 1607 SCR_Reichweite 0;
BA_ "GenSigStartValue" SG_ 1607 SCR_Reichweite 32767;
BA_ "GenSigSwitchedByIgnition" SG_ 1607 SCR_Reichweite 0;
BA_ "GenSigSendType" SG_ 1607 SCR_Systemfehler 0;
BA_ "GenSigSwitchedByIgnition" SG_ 1607 SCR_Systemfehler 0;
BA_ "GenSigSendType" SG_ 1607 SCR_Text 0;
BA_ "GenSigSwitchedByIgnition" SG_ 1607 SCR_Text 0;
BA_ "GenSigSendType" SG_ 1607 SCR_verbaut 0;
BA_ "GenSigFuncType" SG_ 1607 SCR_verbaut 8;
BA_ "GenSigSwitchedByIgnition" SG_ 1607 SCR_verbaut 0;
BA_ "GenSigSendType" SG_ 1607 SCR_Warnstufe_1 0;
BA_ "GenSigSwitchedByIgnition" SG_ 1607 SCR_Warnstufe_1 0;
BA_ "GenSigSendType" SG_ 1607 SCR_Warnstufe_2 0;
BA_ "GenSigSwitchedByIgnition" SG_ 1607 SCR_Warnstufe_2 0;
BA_REL_ "GenSigTimeoutTime" BU_SG_REL_ Gateway_Max SG_ 2527679633 LSH_LED 2000;
BA_REL_ "GenSigTimeoutTime" BU_SG_REL_ Gateway_Max SG_ 1171 MF_Laderelais 2000;
BA_REL_ "GenSigTimeoutTime" BU_SG_REL_ Gateway_Max SG_ 1171 MF_StartStopp_Info 2000;
BA_REL_ "GenSigTimeoutTime" BU_SG_REL_ Gateway_Max SG_ 1164 MF_Relais_2_Batterie 2000;
BA_REL_ "GenSigTimeoutTime" BU_SG_REL_ Gateway_Max SG_ 1164 MF_2BattHlkAnf 2000;
BA_REL_ "GenSigTimeoutTime" BU_SG_REL_ Gateway_Max SG_ 1164 MF_2BattLlaAnf 2000;
BA_REL_ "GenSigTimeoutTime" BU_SG_REL_ Gateway_Max SG_ 1164 MF_2BattSpannungsAnf 2000;
BA_REL_ "GenSigTimeoutTime" BU_SG_REL_ Gateway_Max SG_ 2463978883 MF_U2Batt 1000;
BA_REL_ "GenSigTimeoutTime" BU_SG_REL_ Gateway_Max SG_ 2463978883 MF_UBattVorgabe 1000;
BA_REL_ "GenSigTimeoutTime" BU_SG_REL_ Gateway_Max SG_ 2463978883 MF_I_U_VorgabeZwang 1000;
BA_REL_ "GenSigTimeoutTime" BU_SG_REL_ Gateway_Max SG_ 2463978883 MF_DCDC_Istmodus 1000;
BA_REL_ "GenSigTimeoutTime" BU_SG_REL_ HUD SG_ 2463978598 LoGeWa_C2C_Event_Einheit 2000;
BA_REL_ "GenSigTimeoutTime" BU_SG_REL_ HUD SG_ 2463978598 LoGeWa_C2C_Event_Richtung 2000;
BA_REL_ "GenSigTimeoutTime" BU_SG_REL_ HUD SG_ 2463978598 LoGeWa_C2C_Event_Status 2000;
BA_REL_ "GenSigTimeoutTime" BU_SG_REL_ HUD SG_ 2463978598 LoGeWa_C2C_Event_Warnung 2000;
BA_REL_ "GenSigTimeoutTime" BU_SG_REL_ HUD SG_ 2463978598 LoGeWa_C2C_Event_Entfernung 2000;
BA_REL_ "GenSigTimeoutTime" BU_SG_REL_ HUD SG_ 1153 Nav_FoD_Status 5000;
BA_REL_ "GenSigTimeoutTime" BU_SG_REL_ HUD SG_ 1471 MFL_Tastencode_1 5000;
BA_REL_ "GenSigTimeoutTime" BU_SG_REL_ HUD SG_ 1471 MFL_Tastencode_2 5000;
BA_REL_ "GenSigTimeoutTime" BU_SG_REL_ HUD SG_ 1471 MFL_Eventcode_1 5000;
BA_REL_ "GenSigTimeoutTime" BU_SG_REL_ HUD SG_ 1471 MFL_Eventcode_2 5000;
BA_REL_ "GenSigTimeoutTime" BU_SG_REL_ HUD SG_ 1471 MFL_Marke 5000;
BA_REL_ "GenSigTimeoutTime" BU_SG_REL_ HUD SG_ 1471 MFL_Variante 5000;
BA_REL_ "GenSigTimeoutTime" BU_SG_REL_ HUD SG_ 1600 MO_Oel_Temp 5000;
BA_REL_ "GenSigTimeoutTime" BU_SG_REL_ Kombi SG_ 1624 LV_Standlicht_Anzeige 5000;
BA_REL_ "GenSigTimeoutTime" BU_SG_REL_ Kombi SG_ 1624 LV_Abblendlicht_Anzeige 5000;
BA_REL_ "GenSigTimeoutTime" BU_SG_REL_ Kombi SG_ 1624 LV_Fernlicht_Anzeige 5000;
BA_REL_ "GenSigTimeoutTime" BU_SG_REL_ Kombi SG_ 1624 LV_Nebellicht_Anzeige 5000;
BA_REL_ "GenSigTimeoutTime" BU_SG_REL_ Kombi SG_ 1624 LV_Nebelschlusslicht_Anzeige 5000;
BA_REL_ "GenSigTimeoutTime" BU_SG_REL_ Kombi SG_ 1624 LV_Tagfahrlicht_Anzeige 5000;
BA_REL_ "GenSigTimeoutTime" BU_SG_REL_ Kombi SG_ 1624 LV_AFL_aktiv_Anzeige 5000;
BA_REL_ "GenSigTimeoutTime" BU_SG_REL_ Kombi SG_ 1624 LV_AFL_defekt 5000;
BA_REL_ "GenSigTimeoutTime" BU_SG_REL_ Kombi SG_ 1624 LV_Blinker_li_def 5000;
BA_REL_ "GenSigTimeoutTime" BU_SG_REL_ Kombi SG_ 1624 LV_Standlicht_li_def 5000;
BA_REL_ "GenSigTimeoutTime" BU_SG_REL_ Kombi SG_ 1624 LV_Abblendlicht_li_def 5000;
BA_REL_ "GenSigTimeoutTime" BU_SG_REL_ Kombi SG_ 1624 LV_Fernlicht_li_def 5000;
BA_REL_ "GenSigTimeoutTime" BU_SG_REL_ Kombi SG_ 1624 LV_Nebellicht_li_def 5000;
BA_REL_ "GenSigTimeoutTime" BU_SG_REL_ Kombi SG_ 1624 LV_Blk_li_Seite_def 5000;
BA_REL_ "GenSigTimeoutTime" BU_SG_REL_ Kombi SG_ 1624 LV_Tagfahrlicht_li_def 5000;
BA_REL_ "GenSigTimeoutTime" BU_SG_REL_ Kombi SG_ 1624 LV_FLA_aktiv_Anzeige 5000;
BA_REL_ "GenSigTimeoutTime" BU_SG_REL_ Kombi SG_ 1624 LV_FLA_defekt 5000;
BA_REL_ "GenSigTimeoutTime" BU_SG_REL_ Kombi SG_ 1624 LV_FLA_Sensor_blockiert 5000;
BA_REL_ "GenSigTimeoutTime" BU_SG_REL_ Kombi SG_ 1624 LV_Blinker_re_def 5000;
BA_REL_ "GenSigTimeoutTime" BU_SG_REL_ Kombi SG_ 1624 LV_Standlicht_re_def 5000;
BA_REL_ "GenSigTimeoutTime" BU_SG_REL_ Kombi SG_ 1624 LV_Abblendlicht_re_def 5000;
BA_REL_ "GenSigTimeoutTime" BU_SG_REL_ Kombi SG_ 1624 LV_Fernlicht_re_def 5000;
BA_REL_ "GenSigTimeoutTime" BU_SG_REL_ Kombi SG_ 1624 LV_Nebellicht_re_def 5000;
BA_REL_ "GenSigTimeoutTime" BU_SG_REL_ Kombi SG_ 1624 LV_Blk_re_Seite_def 5000;
BA_REL_ "GenSigTimeoutTime" BU_SG_REL_ Kombi SG_ 1624 LV_Tagfahrlicht_re_def 5000;
BA_REL_ "GenSigTimeoutTime" BU_SG_REL_ Kombi SG_ 1624 LV_Aussenlicht_def 5000;
BA_REL_ "GenSigTimeoutTime" BU_SG_REL_ Kombi SG_ 1624 LV_Abblendlicht_TFL_li_def 5000;
BA_REL_ "GenSigTimeoutTime" BU_SG_REL_ Kombi SG_ 1624 LV_Nebellicht_TFL_li_def 5000;
BA_REL_ "GenSigTimeoutTime" BU_SG_REL_ Kombi SG_ 1624 LV_Standlicht_TFL_li_def 5000;
BA_REL_ "GenSigTimeoutTime" BU_SG_REL_ Kombi SG_ 1624 LV_Abblend_Fernlicht_li_def 5000;
BA_REL_ "GenSigTimeoutTime" BU_SG_REL_ Kombi SG_ 1624 LV_Abblendlicht_TFL_re_def 5000;
BA_REL_ "GenSigTimeoutTime" BU_SG_REL_ Kombi SG_ 1624 LV_Nebellicht_TFL_re_def 5000;
BA_REL_ "GenSigTimeoutTime" BU_SG_REL_ Kombi SG_ 1624 LV_Standlicht_TFL_re_def 5000;
BA_REL_ "GenSigTimeoutTime" BU_SG_REL_ Kombi SG_ 1624 LV_Abblend_Fernlicht_re_def 5000;
BA_REL_ "GenSigTimeoutTime" BU_SG_REL_ Kombi SG_ 1624 LV_Abbiegelicht_li_def 5000;
BA_REL_ "GenSigTimeoutTime" BU_SG_REL_ Kombi SG_ 1624 LV_Abbiegelicht_re_def 5000;
BA_REL_ "GenSigTimeoutTime" BU_SG_REL_ Kombi SG_ 1624 BCM1_Licht_Dunkelheit_aktiv 5000;
BA_REL_ "GenSigTimeoutTime" BU_SG_REL_ Kombi SG_ 1624 LV_LED_Scheinwerfer_li_def 5000;
BA_REL_ "GenSigTimeoutTime" BU_SG_REL_ Kombi SG_ 1624 LV_LED_Scheinwerfer_re_def 5000;
BA_REL_ "GenSigTimeoutTime" BU_SG_REL_ Kombi SG_ 2463978598 LoGeWa_C2C_Event_Einheit 2000;
BA_REL_ "GenSigTimeoutTime" BU_SG_REL_ Kombi SG_ 2463978598 LoGeWa_C2C_Event_Richtung 2000;
BA_REL_ "GenSigTimeoutTime" BU_SG_REL_ Kombi SG_ 2463978598 LoGeWa_C2C_Event_Status 2000;
BA_REL_ "GenSigTimeoutTime" BU_SG_REL_ Kombi SG_ 2463978598 LoGeWa_C2C_Event_Warnung 2000;
BA_REL_ "GenSigTimeoutTime" BU_SG_REL_ Kombi SG_ 2463978598 LoGeWa_C2C_Event_Entfernung 2000;
BA_REL_ "GenSigTimeoutTime" BU_SG_REL_ Kombi SG_ 917 AFS_Lampe 1000;
BA_REL_ "GenSigTimeoutTime" BU_SG_REL_ Kombi SG_ 917 LWR_Lampe 1000;
BA_REL_ "GenSigTimeoutTime" BU_SG_REL_ Kombi SG_ 917 AFS_Fehlertext 1000;
BA_REL_ "GenSigTimeoutTime" BU_SG_REL_ Kombi SG_ 917 AFS_LED_Blinkmode 1000;
BA_REL_ "GenSigTimeoutTime" BU_SG_REL_ Kombi SG_ 917 LWR_Reisemodus_Texte 1000;
BA_REL_ "GenSigTimeoutTime" BU_SG_REL_ Kombi SG_ 1153 ZR_LoGeWa_Event_Kombiwarnung 5000;
BA_REL_ "GenSigTimeoutTime" BU_SG_REL_ Kombi SG_ 1153 Nav_FoD_Status 5000;
BA_REL_ "GenSigTimeoutTime" BU_SG_REL_ Kombi SG_ 1153 DSSS_Warning 5000;
BA_REL_ "GenSigTimeoutTime" BU_SG_REL_ Kombi SG_ 1639 BFS_MMB_storage_beep 1000;
BA_REL_ "GenSigTimeoutTime" BU_SG_REL_ Kombi SG_ 2463978884 Mem_BFS_Fond_02_CRC 1000;
BA_REL_ "GenSigTimeoutTime" BU_SG_REL_ Kombi SG_ 2463978884 Mem_BFS_Fond_02_BZ 1000;
BA_REL_ "GenSigTimeoutTime" BU_SG_REL_ Kombi SG_ 2463978884 Mem_BFSFo_Warn_Dreh_entriegelt 1000;
BA_REL_ "GenSigTimeoutTime" BU_SG_REL_ Kombi SG_ 2463978889 Mem_BFS_Fond_03_CRC 2000;
BA_REL_ "GenSigTimeoutTime" BU_SG_REL_ Kombi SG_ 2463978889 Mem_BFS_Fond_03_BZ 2000;
BA_REL_ "GenSigTimeoutTime" BU_SG_REL_ Kombi SG_ 2463978889 Mem_HBFSFo_Stoerung 2000;
BA_REL_ "GenSigTimeoutTime" BU_SG_REL_ Kombi SG_ 2463978889 Mem_HBFSFo_Anzeige_Komfort_HBFS 2000;
BA_REL_ "GenSigTimeoutTime" BU_SG_REL_ Kombi SG_ 1178 FS_MMB_storage_beep 1000;
BA_REL_ "GenSigTimeoutTime" BU_SG_REL_ Kombi SG_ 956 Mem_FS_Fond_01_CRC 1000;
BA_REL_ "GenSigTimeoutTime" BU_SG_REL_ Kombi SG_ 956 Mem_FS_Fond_01_BZ 1000;
BA_REL_ "GenSigTimeoutTime" BU_SG_REL_ Kombi SG_ 956 Mem_FSFo_Warn_Dreh_entriegelt 1000;
BA_REL_ "GenSigTimeoutTime" BU_SG_REL_ Kombi SG_ 2463978890 Mem_FS_Fond_03_CRC 2000;
BA_REL_ "GenSigTimeoutTime" BU_SG_REL_ Kombi SG_ 2463978890 Mem_FS_Fond_03_BZ 2000;
BA_REL_ "GenSigTimeoutTime" BU_SG_REL_ Kombi SG_ 2463978890 Mem_HFSFo_Stoerung 2000;
BA_REL_ "GenSigTimeoutTime" BU_SG_REL_ Kombi SG_ 2463978890 Mem_HFSFo_Anzeige_Komfort_HFS 2000;
BA_REL_ "GenSigTimeoutTime" BU_SG_REL_ Kombi SG_ 1171 MF_Motorweiterlauf 2000;
BA_REL_ "GenSigTimeoutTime" BU_SG_REL_ Kombi SG_ 1171 MF_Summer 2000;
BA_REL_ "GenSigTimeoutTime" BU_SG_REL_ Kombi SG_ 1164 MF_2BatSOCzugering 2000;
BA_REL_ "GenSigTimeoutTime" BU_SG_REL_ Kombi SG_ 1164 MF_Fahrerhinweis 2000;
BA_REL_ "GenSigTimeoutTime" BU_SG_REL_ Kombi SG_ 1164 MF_2BattAb 2000;
BA_REL_ "GenSigTimeoutTime" BU_SG_REL_ Kombi SG_ 1164 MF_2BattLadWarn 2000;
BA_REL_ "GenSigTimeoutTime" BU_SG_REL_ Kombi SG_ 1164 MF_NotStartAktiv 2000;
BA_REL_ "GenSigTimeoutTime" BU_SG_REL_ Kombi SG_ 1164 MF_ExterneLadungWarn 2000;
BA_REL_ "GenSigTimeoutTime" BU_SG_REL_ Kombi SG_ 2463978883 MF_Fahrerhinweis_2 1000;
BA_REL_ "GenSigTimeoutTime" BU_SG_REL_ Kombi SG_ 1471 MFL_Tastencode_1 5000;
BA_REL_ "GenSigTimeoutTime" BU_SG_REL_ Kombi SG_ 1471 MFL_Tastencode_2 5000;
BA_REL_ "GenSigTimeoutTime" BU_SG_REL_ Kombi SG_ 1471 MFL_Eventcode_1 5000;
BA_REL_ "GenSigTimeoutTime" BU_SG_REL_ Kombi SG_ 1471 MFL_Eventcode_2 5000;
BA_REL_ "GenSigTimeoutTime" BU_SG_REL_ Kombi SG_ 1471 MFL_Marke 5000;
BA_REL_ "GenSigTimeoutTime" BU_SG_REL_ Kombi SG_ 1471 MFL_Variante 5000;
BA_REL_ "GenSigTimeoutTime" BU_SG_REL_ Kombi SG_ 1600 MO_QBit_Kuehlmittel_Temp 5000;
BA_REL_ "GenSigTimeoutTime" BU_SG_REL_ Kombi SG_ 1600 MO_Oel_Temp 5000;
BA_REL_ "GenSigTimeoutTime" BU_SG_REL_ Kombi SG_ 1600 MO_Kuehlmittel_Temp 5000;
BA_REL_ "GenSigTimeoutTime" BU_SG_REL_ Kombi SG_ 1607 MO_ITM_Kuehlmittel_Temp 5000;
BA_REL_ "GenSigTimeoutTime" BU_SG_REL_ Kombi SG_ 1607 SCR_verbaut 5000;
BA_REL_ "GenSigTimeoutTime" BU_SG_REL_ Kombi SG_ 1607 MO_Kraftstofffilter_Wasser 5000;
BA_REL_ "GenSigTimeoutTime" BU_SG_REL_ Kombi SG_ 1607 MO_MKB_MUX 5000;
BA_REL_ "GenSigTimeoutTime" BU_SG_REL_ Kombi SG_ 1607 MO_MKB_01 5000;
BA_REL_ "GenSigTimeoutTime" BU_SG_REL_ Kombi SG_ 1607 MO_MKB_02 5000;
BA_REL_ "GenSigTimeoutTime" BU_SG_REL_ Kombi SG_ 1607 MO_MKB_03 5000;
BA_REL_ "GenSigTimeoutTime" BU_SG_REL_ Kombi SG_ 1607 MO_MKB_04 5000;
VAL_ 1624 LV_Standlicht_Anzeige 0 "nicht aktiv" 1 "aktiv" ;
VAL_ 1624 LV_Abblendlicht_Anzeige 0 "inaktiv" 1 "aktiv" ;
VAL_ 1624 LV_Fernlicht_Anzeige 0 "nicht aktiv" 1 "aktiv" ;
VAL_ 1624 LV_Nebellicht_Anzeige 0 "nicht aktiv" 1 "aktiv" ;
VAL_ 1624 LV_Nebelschlusslicht_Anzeige 0 "nicht aktiv" 1 "aktiv" ;
VAL_ 1624 LV_Tagfahrlicht_Anzeige 0 "nicht aktiv" 1 "aktiv" ;
VAL_ 1624 LV_AFL_aktiv_Anzeige 0 "nicht aktiv" 1 "aktiv" ;
VAL_ 1624 LV_AFL_defekt 0 "OK" 1 "defekt" ;
VAL_ 1624 LV_Blinker_li_def 0 "OK" 1 "defekt" ;
VAL_ 1624 LV_Standlicht_li_def 0 "OK" 1 "defekt" ;
VAL_ 1624 LV_Abblendlicht_li_def 0 "OK" 1 "defekt" ;
VAL_ 1624 LV_Fernlicht_li_def 0 "OK" 1 "defekt" ;
VAL_ 1624 LV_Nebellicht_li_def 0 "OK" 1 "defekt" ;
VAL_ 1624 LV_Blk_li_Seite_def 0 "OK" 1 "defekt" ;
VAL_ 1624 LV_Tagfahrlicht_li_def 0 "OK" 1 "defekt" ;
VAL_ 1624 LV_FLA_aktiv_Anzeige 0 "aus" 1 "ein" ;
VAL_ 1624 LV_FLA_defekt 0 "i.O." 1 "FLA defekt" ;
VAL_ 1624 LV_FLA_Sensor_blockiert 0 "i.O." 1 "FLA-Sensor blockiert" ;
VAL_ 1624 LV_Blinker_re_def 0 "OK" 1 "defekt" ;
VAL_ 1624 LV_Standlicht_re_def 0 "OK" 1 "defekt" ;
VAL_ 1624 LV_Abblendlicht_re_def 0 "OK" 1 "defekt" ;
VAL_ 1624 LV_Fernlicht_re_def 0 "OK" 1 "defekt" ;
VAL_ 1624 LV_Nebellicht_re_def 0 "OK" 1 "defekt" ;
VAL_ 1624 LV_Blk_re_Seite_def 0 "OK" 1 "defekt" ;
VAL_ 1624 LV_Tagfahrlicht_re_def 0 "OK" 1 "defekt" ;
VAL_ 1624 LV_Aussenlicht_def 0 "OK" 1 "defekt" ;
VAL_ 1624 LV_Abblendlicht_TFL_li_def 0 "OK" 1 "defekt" ;
VAL_ 1624 LV_Nebellicht_TFL_li_def 0 "OK" 1 "defekt" ;
VAL_ 1624 LV_Standlicht_TFL_li_def 0 "OK" 1 "defekt" ;
VAL_ 1624 LV_Abblend_Fernlicht_li_def 0 "OK" 1 "defekt" ;
VAL_ 1624 LV_Abblendlicht_TFL_re_def 0 "OK" 1 "defekt" ;
VAL_ 1624 LV_Nebellicht_TFL_re_def 0 "OK" 1 "defekt" ;
VAL_ 1624 LV_Standlicht_TFL_re_def 0 "OK" 1 "defekt" ;
VAL_ 1624 LV_Abblend_Fernlicht_re_def 0 "OK" 1 "defekt" ;
VAL_ 1624 LV_Abbiegelicht_li_def 0 "OK" 1 "defekt" ;
VAL_ 1624 LV_Abbiegelicht_re_def 0 "OK" 1 "defekt" ;
VAL_ 1624 BCM1_Linksverkehr 0 "Rechtsverkehr" 1 "Linksverkehr" ;
VAL_ 1624 BCM1_Licht_Dunkelheit_aktiv 0 "inaktiv" 1 "aktiv" ;
VAL_ 1624 LV_LED_Scheinwerfer_li_def 0 "OK" 1 "defekt" ;
VAL_ 1624 LV_LED_Scheinwerfer_re_def 0 "OK" 1 "defekt" ;
VAL_ 1624 LV_Blinker_VL_aktiv 0 "inaktiv" 1 "aktiv" ;
VAL_ 1624 LV_Blinker_VR_aktiv 0 "inaktiv" 1 "aktiv" ;
VAL_ 1624 LV_MXB_Status_Anzeige 0 "MXB_aus" 1 "MXB_regelt" 2 "MXB_volles_Fernlicht" 3 "MXB_und_Laser_aktiv" ;
VAL_ 2463978598 LoGeWa_C2C_Anf_Audioabsenkung 0 "nicht_aktiv" 1 "aktiv" ;
VAL_ 2463978598 LoGeWa_C2C_Event_Einheit 0 "Init" 1 "Meter" 2 "Kilometer" 3 "Yard" 4 "Meilen" ;
VAL_ 2463978598 LoGeWa_C2C_Event_Richtung 0 "Init_keine_Richtungsanzeige" 1 "voraus" 2 "von_rechts_naehernd" 3 "von_links_naehernd" 4 "von_hinten_naehernd" 5 "mehrere_Richtungen" ;
VAL_ 2463978598 LoGeWa_C2C_Event_Status 0 "Init_keine_Anzeige" 1 "Info_ohne_Infogong" 2 "Info_mit_Infogong" 3 "Warnung_ohne_Warngong" 4 "Warnung_mit_Warngong" ;
VAL_ 2463978598 LoGeWa_C2C_Event_Warnung 0 "Init" 1 "Unfall" 2 "Traktionsverlust" 3 "Panne" 4 "Sichtbehinderung" 5 "Stauende" 6 "Stau" 7 "Eingriff_Sicherheitssystem" 8 "statisches_SEF" 9 "dynamisches_SEF" 10 "mehrere_dynamische_SEF" 11 "Sperranhaenger" 12 "generisches_statisches_Event" 13 "Stehenbleiber" 14 "Car2X_system_eingeschraenkt" 15 "Car2X_eingeschraenkt_geofencing" 16 "dynamische_SEF_ohneAbsenkung" 17 "mehrere_dyn_SEF_ohneAbsenkung" 18 "Strong_Wind" 19 "Obstacle_on_Road" 20 "Person_on_Road" 21 "Animal_on_Road" 22 "Public_Tranport_Vehicle_Crossing" 23 "Slow_Vehicle" 24 "Wrong_Way_Driving" 25 "Generic_Adverse_Weather" 26 "Water_Accumulation" 27 "Fire" 28 "Facility_Damaged" 29 "Traffic_Light_Failure" 30 "Traffic_Accident" ;
VAL_ 2463978598 LoGeWa_C2C_Event_Entfernung 65535 "Init_keine_Entfernung" ;
VAL_ 822 LR_HZG_Temp_Sensor 253 "KS_Plus__Unterbrechung" 254 "Init" 255 "Tempsensor_fehlerhaft__KS_GND" ;
VAL_ 822 LR_HZG_Taster_on_off 0 "nicht_betaetigt" 1 "betaetigt" ;
VAL_ 822 LR_HZG_Konfiguration 0 "Init" 1 "Parametersatz_1" 2 "Parametersatz_2" 3 "Parametersatz_3" 4 "Parametersatz_4" 5 "Parametersatz_5" 6 "Parametersatz_6" 7 "Parametersatz_7" ;
VAL_ 2527679633 LSH_Geblaese_aktiv 0 "Geblaese_inaktiv" 1 "Geblaese_aktiv" ;
VAL_ 2527679633 LSH_LED 0 "keine_Rueckmeldung" 1 "Rueckmeldung_in_Betrieb" ;
VAL_ 2527679633 LSH_Servicemode 0 "inaktiv" 1 "aktiv" ;
VAL_ 2527679633 LSH_Funk_aus 0 "kein_Funkbefehl_erhalten" 1 "Funkbefehl_erhalten" ;
VAL_ 2527679633 LSH_Funk_ein 0 "kein_Funkbefehl_erhalten" 1 "Funkbefehl_erhalten" ;
VAL_ 2527679633 LSH_Klappe_Status 0 "Init" 1 "Front" 2 "Heck" 3 "Front_u_Heck" 4 "misch_Front_u_Heck" ;
VAL_ 2527679633 LSH_Start_folgt 0 "kein_Start_folgt" 1 "Start_folgt" ;
VAL_ 2527679633 LSH_Heiztemp 254 "Init" 255 "Fehler" ;
VAL_ 2527679633 LSH_Empf_Heizstufe 0 "Init" 1 "Stufe_1" 2 "Stufe_2" 3 "Stufe_3" 4 "Stufe_4" 5 "Stufe_5" 6 "Stufe_6" 7 "Stufe_7" 8 "Stufe_8" 9 "Stufe_9" 10 "Stufe_10" 15 "Fehler" ;
VAL_ 2527679633 LSH_Texte 0 "keine_Anzeige" 1 "Batteriemanagementeinschraenkung" 2 "Kraftstoffmangel" 3 "interner_Systemfehler" 4 "Heizzeitueberschreitung" ;
VAL_ 2527679633 LSH_Waermeeintrag 510 "Init" 511 "Fehler" ;
VAL_ 2527679633 LSH_Ansaug_Fuell_1 254 "Init" 255 "Fehler" ;
VAL_ 2527679633 LSH_Ansaug_Fuell_2 254 "Init" 255 "Fehler" ;
VAL_ 2527679634 LSH_Zuheizen 0 "Aus" 1 "Ein" ;
VAL_ 2527679634 LSH_KVS_Ueberlauf 0 "kein_Ueberlauf" 1 "Kraftstoff_Ueberlauf_erkannt" ;
VAL_ 2527679634 LSH_KL_DBetr_Anf 0 "nicht_angefordert" 1 "angefordert" ;
VAL_ 2527679634 LSH_Fehlerstatus 0 "kein_Fehler" 1 "Unterspannung" 2 "Tankfuellstand_zu_gering" 3 "Fehler_Betrieb_verhindert" 4 "Heizgeraet_verriegelt" 5 "Fehler_Betrieb_nicht_verhindert" 6 "Emissionsueberschreitung" ;
VAL_ 917 AFS_Abbiegelicht_li_Anf 0 "Abbiegelicht_aus" 1 "Abbiegelicht_ein" ;
VAL_ 917 AFS_Abbiegelicht_re_Anf 0 "Abbiegelicht_aus" 1 "Abbiegelicht_ein" ;
VAL_ 917 AFS_Abbiegelicht_Dimm_Anf 0 "Dimmung_angefordert" 1 "keine_Dimmung" ;
VAL_ 917 AFS_Verfuegbarkeit_GLW 0 "GLW_nicht_verfuegbar" 1 "GLW_verfuegbar" ;
VAL_ 917 AFS_Status_adaptive_LV 0 "adaptive_Lichtverteilung_aus" 1 "adaptive_Lichtverteilung_an" ;
VAL_ 917 AFS_Fernlicht_li_defekt 0 "Fernlicht_in_Ordnung" 1 "Fernlicht_defekt" ;
VAL_ 917 AFS_Fernlicht_re_defekt 0 "Fernlicht_in_Ordnung" 1 "Fernlicht_defekt" ;
VAL_ 917 AFS_Fernlicht_Status 0 "Fernlicht_aus" 1 "Fernlicht_ein" ;
VAL_ 917 AFS_Lampe 0 "Aus" 1 "Ein" ;
VAL_ 917 LWR_Lampe 0 "LWR Fehlerlampe aus" 1 "LWR Fehlerlampe ein" ;
VAL_ 917 AFS_Fehlertext 0 "kein Text" 1 "AFS ohne Funktion" ;
VAL_ 917 AFS_LED_Blinkmode 0 "kein Blinkmode angefordert" 1 "Blinkmode angefordert" ;
VAL_ 917 LWR_Touristenmodus_aktiv 0 "Touristenmodus inaktiv" 1 "Touristenmodus aktiv" ;
VAL_ 917 AFS_Charisma_FahrPr 0 "keine_Funktion" 1 "Programm_1" 2 "Programm_2" 3 "Programm_3" 4 "Programm_4" 5 "Programm_5" 6 "Programm_6" 7 "Programm_7" 8 "Programm_8" 9 "Programm_9" 10 "Programm_10" 11 "Programm_11" 12 "Programm_12" 13 "Programm_13" 14 "Programm_14" 15 "Programm_15" ;
VAL_ 917 AFS_Charisma_Status 0 "Init" 1 "verfuegbar" 2 "nicht_verfuegbar" 3 "asynchron_durch_Fahrerwunsch" ;
VAL_ 917 AFS_Allwetterlicht 0 "Allwetterlicht_nicht_aktiv" 1 "Allwetterlicht_aktiv" ;
VAL_ 917 LWR_Touristenmodus_verbaut 0 "Touristenmodus_nicht_verbaut" 1 "Touristenmodus_verbaut" ;
VAL_ 917 AFS_adaptive_LV_verbaut 0 "adaptive_Lichtverteilung_nicht_verbaut" 1 "adaptive_Lichtverteilung_verbaut" ;
VAL_ 917 LWR_Reisemodus_Texte 0 "keine_Anzeige" 1 "Umschaltung_auf_Linksverkehr_aktiv" 2 "Umschaltung_auf_Rechtsverkehr_aktiv" ;
VAL_ 917 GLW_Sensor_blockiert 0 "Kamera_Sensor_nicht_blockiert" 1 "Kamera_Sensor_blockiert" ;
VAL_ 917 LWR_Pos_Schrittmotor 254 "Init" 255 "Fehler" ;
VAL_ 917 LWR_Hoehenwert_VL 254 "nicht_initialisiert" 255 "Fehler" ;
VAL_ 917 LWR_Hoehenwert_HL 254 "nicht_initialisiert" 255 "Fehler" ;
VAL_ 917 AFS_Ersatzlicht_Links 0 "keine Ersatzlichtfunktion links" 1 "Ersatzlichtfunktion links" ;
VAL_ 917 AFS_Ersatzlicht_Rechts 0 "keine Ersatzlichtfunktion rechts" 1 "Ersatzlichtfunktion rechts" ;
VAL_ 917 LWR_AFS_Grundeinstellung 0 "Grundeinstellung nicht erfolgt" 1 "Grundeinstellung erfolgt" ;
VAL_ 917 LWR_AFS_Parametrisierung 0 "Parametrisierung nicht erfolgt" 1 "Parametrisierung erfolgt" ;
VAL_ 917 LWR_Initialisierungslauf 0 "Initialisierungslauf nicht erfolgt" 1 "Initialisierungslauf erfolgt" ;
VAL_ 917 LWR_Sicherheitsposition 0 "Sicherheitsposition aus" 1 "Sicherheitsposition ein" ;
VAL_ 917 LWR_Modus 0 "LWR statisch" 1 "LWR dynamisch" ;
VAL_ 1153 ZR_LoGeWa_Event_Kombiwarnung 0 "Init" 1 "Unfall" 2 "Traktionsverlust" 3 "Panne" 4 "Sichtbehinderung" 5 "Aquaplaning" 6 "EEBL" 7 "SEF_stat" 8 "SEF_dyn_allgemein" 9 "SEF_dyn_vorne" 10 "SEF_dyn_hinten" 11 "SEF_dyn_links" 12 "SEF_dyn_rechts" 13 "Stauende" ;
VAL_ 1153 Nav_FoD_Status 0 "Init" 1 "Nav_permanently_available" 2 "FoD_Nav_not_activated" 3 "FoD_Nav_activated" 4 "R4N_Nav_not_activated" ;
VAL_ 1153 MIB_ASW_Diagnose 0 "ASW_Warnton_nicht_verfuegbar" 1 "ASW_Warnton_verfuegbar" ;
VAL_ 1153 ZR_Lichter_Tag 0 "Nacht" 1 "Tag" ;
VAL_ 1153 MIB_Tongenerator_PH_verfuegbar 0 "Tongenerator_nicht_verfuegbar" 1 "Tongenerator_vorne_verfuegbar" 2 "Tongenerator_hinten_verfuegbar" 3 "Tongenerator_gesamt_verfuegbar" 4 "Tongenerator_im_AMP" ;
VAL_ 1153 DSSS_Warning 0 "No_Warning" 1 "Red_traffic_light_guidance" 2 "Stop_sign_warning" 3 "Rear_end_collision_avoidance_warning" 4 "Intersection_collision_avoidance_warning_right" 5 "Intersection_collision_avoidance_warning_left" 6 "turn_right_collision_avoidance" 7 "turn_left_collision_avoidance" 8 "pedestrian_crossing_right" 9 "pedestrian_crossing_left" 10 "bicycle_collision_right" 11 "bicycle_collision_left" ;
VAL_ 1153 ZR_Kindersicherung_RSE 0 "inaktiv" 1 "aktiv" ;
VAL_ 1153 ZR_RSE_aktivieren 0 "inaktiv" 1 "aktiv" ;
VAL_ 1153 MMI_SDS_aktiv 0 "inaktiv" 1 "aktiv" ;
VAL_ 1153 MU_SecondDisplay 0 "Init" 1 "gueltige_Karte" 2 "ungueltiges_Signal" 3 "Nicht_Verbaut" ;
VAL_ 1153 MMI_Telefon_aktiv 0 "Telefongespraech_nicht_aktiv" 1 "Telefongespraech_aktiv" ;
VAL_ 1153 MMI_Gurt_Mic_ref 0 "Downlink_inaktiv" 1 "Downlink_aktiv" ;
VAL_ 1153 ZR_Sta_Inszenierung 0 "Init" 1 "Inszenierung_deaktiviert" 2 "Inszenierung_Start" 3 "Inszenierung_Stop" ;
VAL_ 1153 ZR_AppConnect_Zustand 0 "AppConnect_nicht_in_Anzeige" 1 "AppConnect_in_Anzeige" ;
VAL_ 1153 ZR_Parken_Sondermodus 0 "Init" 1 "Sondermodus_aktiv" 2 "Sondermodus_nicht_verfuegbar" 3 "WLAN_aus" 4 "WLAN_auscodiert" 15 "keine_WLAN_HW" ;
VAL_ 1639 BFS_Fond_Bed_Ack 0 "nicht aktiviert" 1 "aktiviert" ;
VAL_ 1639 BFS_Lehne_nicht_verriegelt 0 "keine Anzeige" 1 "Lehne_nicht_verriegelt" ;
VAL_ 1639 BFS_Klapptisch_offen 0 "inaktiv" 1 "aktiv" ;
VAL_ 1639 BFS_Gurtbringer_Sperre 0 "Gurtzubringer_freigegeben" 1 "Gurtzubringer_gesperrt" ;
VAL_ 1639 BFS_Sitzsym_Fahrt_aktiv 0 "inaktiv" 1 "aktiv" ;
VAL_ 1639 BFS_Sitzfahrt_aktiv 0 "Init" 1 "Sitz in Bewegung" ;
VAL_ 1639 BFS_SLV_aktiv 0 "nicht_aktiv" 1 "Sitzlaengsverstellung aktiv" ;
VAL_ 1639 BFS_SHV_aktiv 0 "nicht_aktiv" 1 "Sitzhoehenverstellung aktiv" ;
VAL_ 1639 BFS_LNV_aktiv 0 "inaktiv" 1 "aktiv" ;
VAL_ 1639 BFS_SNV_aktiv 0 "nicht_aktiv" 1 "Sitzneigungsverstellung aktiv" ;
VAL_ 1639 BFS_KSV_aktiv 0 "nicht_aktiv" 1 "Kopfstuetzenverstellung aktiv" ;
VAL_ 1639 BFS_LKV_aktiv 0 "nicht_aktiv" 1 "aktiv" ;
VAL_ 1639 BFS_STV_aktiv 0 "inaktiv" 1 "Sitztiefeverstellung aktiv" ;
VAL_ 1639 BFS_LHV_aktiv 0 "inaktiv" 1 "aktiv" ;
VAL_ 1639 BFS_LWV_aktiv 0 "nicht_aktiv" 1 "aktiv" ;
VAL_ 1639 BFS_GHV_aktiv 0 "nicht_aktiv" 1 "Gurthoehe Verstellung aktiv" ;
VAL_ 1639 BFS_KSS_Fahrt_aktiv 0 "nicht_aktiv" 1 "Komfortseitensichtfahrt aktiv" ;
VAL_ 1639 BFS_MMB_lokal_Stop 0 "kein_Abbruch" 1 "lokaler_Abbruch" ;
VAL_ 1639 BFS_Ruhestellung_Status 0 "inakiv" 1 "Ruhestellung_aktiv" ;
VAL_ 1639 BFS_Seat_Locked 0 "nicht_gesperrt" 1 "gesperrt" ;
VAL_ 1639 BFS_MMB_storage 0 "keine Zuweisung" 1 "P1/FP1 Pos Zuweisung" 2 "P2/FP2 Pos Zuweisung" 3 "P3/FP3 Pos Zuweisung" 4 "P4/FP4 Pos Zuweisung an den im System aktiven Funkschlüssel/FPI ID über MMI" 5 "FS1" 6 "FS2" 7 "FS3" 8 "FS4" ;
VAL_ 1639 BFS_MMB_tipp 0 "kein_Tippbetrieb" 1 "Tippbetrieb" ;
VAL_ 1639 BFS_MMB_tast 0 "kein_Tastbetrieb" 1 "Tastbetrieb" ;
VAL_ 1639 BFS_MMB_store_LED_on 0 "LED_aus" 1 "LED_ein" ;
VAL_ 1639 BFS_MMB_storage_beep 0 "beep_aus" 1 "beep ein" ;
VAL_ 1639 BFS_MMB_store 0 "nicht speichern" 1 "speichern" ;
VAL_ 1639 BFS_MMB_glob_stop 0 "kein globaler Abbruch" 1 "globaler Abbruch" ;
VAL_ 1639 BFS_FSV_ausgeklappt 0 "FSV_nicht_ausgeklappt" 1 "FSV_ausgeklappt" ;
VAL_ 1639 BFS_Klappfunktion_Aktiv 0 "inaktiv" 1 "aktiv" ;
VAL_ 1639 BFS_Klappfunktion_Bed_Ack 0 "inaktiv" 1 "klappen" 2 "aufrichten" 3 "reserve" ;
VAL_ 1639 BFS_Klappfunktion_Beschraenkung 0 "inaktiv" 1 "aktiv" 2 "reserve" 3 "reserve" ;
VAL_ 1639 BFS_Klappfunktion_Status 0 "init" 1 "Status1" 2 "Status2" 3 "Status3" ;
VAL_ 2463978884 Mem_BFSFo_Warn_Dreh_entriegelt 0 "inaktiv_Init" 1 "Notentriegelung_HBFS_akiv" 2 "Notentriegelung_HBFS_inaktiv" 3 "Lehnenneigung_falsch_HBFS_akiv" 4 "Lehnenneigung_falsh_HBFS_inaktiv" 5 "Kissenneigung_falsch_HBFS_akiv" 6 "Kissenneigung_falsh_HBFS_inaktiv" 7 "Fehler_aktiv" ;
VAL_ 2463978884 Mem_BFSFo_Warn_Verriegelung 0 "inaktiv_Init" 1 "Sitzdrehung_hinten_rechts_aktiv" 2 "Sitzdrehung_hinte_rechts_inaktiv" ;
VAL_ 2463978884 HBFS_Kopfst_unten 0 "nicht_unten" 1 "unten" ;
VAL_ 2463978884 HBFS_Fahrposition 0 "Ladeboden" 1 "Fahrposition" ;
VAL_ 2463978884 Mem_HBFS_Seat_Attention 0 "init" 1 "Armlehne" 2 "Sitzlehne" 3 "Sitzhoehe" 4 "Sitzlaenge" 5 "Sitzneigung" 6 "Beinauflage" 7 "Fehler" ;
VAL_ 2463978884 HBFS_Komfortposition_Status 0 "init" 1 "Status1" 2 "Status2" 3 "Status3" ;
VAL_ 2463978884 HBFS_Komfortposition_Beschraenku 0 "inaktiv" 1 "aktiv" 2 "reserve" 3 "reserve" ;
VAL_ 2463978884 HBFS_Komfortposition_Aktiv 0 "inaktiv" 1 "aktiv" ;
VAL_ 2463978884 HBFS_Anfahrt_Komfortposition 0 "init" 1 "Position1" 2 "Position2" 3 "Position3" ;
VAL_ 2463978884 HBFS_Anfahrt_Klappfunktion 0 "init" 1 "Position1" 2 "Position2" 3 "Position3" ;
VAL_ 2463978884 HBFS_Klappfunktion_Status 0 "init" 1 "Status1" 2 "Status2" 3 "Status3" ;
VAL_ 2463978884 HBFS_Klappfunktion_Beschraenkung 0 "inaktiv" 1 "aktiv" 2 "reserve" 3 "reserve" ;
VAL_ 2463978884 HBFS_EasyEntry_Aktiv 0 "inaktiv" 1 "aktiv" ;
VAL_ 2463978884 HBFS_EasyEntry_Beschraenkung 0 "inaktiv" 1 "aktiv" 2 "reserve" 3 "reserve" ;
VAL_ 2463978884 HBFS_EasyEntry_Status 0 "init" 1 "Status1" 2 "Status2" 3 "Status3" ;
VAL_ 2463978884 HBFS_Anfahrt_EasyEntry 0 "init" 1 "Position1" 2 "Position2" 3 "Position3" ;
VAL_ 2463978884 HBFS_Klappfunktion_Aktiv 0 "inaktiv" 1 "aktiv" ;
VAL_ 2463978889 Mem_HBFSFo_Warnung_Softstop 0 "keine_Warnmeldung" 1 "Warnmeldung" 2 "Reserve" 3 "Fehler" ;
VAL_ 2463978889 Mem_HBFSFo_Stoerung 0 "kein_Fehler_Sitz" 1 "Fehler_Sitz_aktiv" ;
VAL_ 2463978889 Mem_HBFSFo_globaler_Lehnenwinkel 254 "init" 255 "Fehler" ;
VAL_ 2463978889 Mem_HBFSFo_globaler_Sitzflachenw 254 "init" 255 "Fehler" ;
VAL_ 2463978889 Mem_HBFSFo_Sperre_Sitzdisplay 0 "Displaysperre_HBFS_aus" 1 "Displaysperre_HBFS_an" ;
VAL_ 2463978889 Mem_HBFSFo_Abschaltanf_SRAB 0 "Einschaltung_SRAB" 1 "Abschaltung_SRAB" 2 "Init" 3 "Fehler" ;
VAL_ 2463978889 Mem_HBFSFo_Anzeige_Komfort_HBFS 0 "keine_Statusanzeige" 1 "Anzeige_Lehne_ein_mitTon" 2 "Anzeige_SNV_ein_mitTon" 3 "Anzeige_Lehne_UND_SNV_ein_mitTon" 4 "Anzeige_Lehne_ein_oTon" 5 "Anzeige_SNV_ein_oTon" 6 "Anzeige_Lehne_UND_SNV_ein_oTon" ;
VAL_ 2463978889 Mem_HBFSFo_Status_Schalter_Ki_Si 0 "Schalter_Kindersitz_ein" 1 "Schalter_Kindersitz_aus" 2 "Init" 3 "Fehler" ;
VAL_ 2463978889 Mem_HBFSFo_ARMTuer_aktiv 0 "inaktiv" 1 "aktiv" ;
VAL_ 2463978889 Mem_HBFSFo_ARMTunnel_aktiv 0 "inaktiv" 1 "aktiv" ;
VAL_ 2463978889 Mem_HBFSFo_SHV_aktiv 0 "inaktiv" 1 "aktiv" ;
VAL_ 2463978889 Mem_HBFSFo_SLV_aktiv 0 "inaktiv" 1 "aktiv" ;
VAL_ 2463978889 Mem_HBFSFo_SLV_hinten 0 "nicht_hinten" 1 "hinten" ;
VAL_ 2463978889 Mem_HBFSFo_BATV_aktiv 0 "inaktiv" 1 "aktiv" ;
VAL_ 2463978889 Mem_HBFSFo_EE_Entriegl_Motor 0 "geschlossen" 1 "offen" ;
VAL_ 2463978889 Mem_HBFSFo_EE_Verr_Sensor_re 0 "init" 1 "offen" 2 "geschlossen_innen" 3 "geschlossen_aussen" 4 "geschlossen_beide" 5 "Fehler" ;
VAL_ 2463978889 Mem_HBFSFo_Verr_Sensor_oben_re 0 "init" 1 "offen" 2 "geschlossen_innen" 3 "geschlossen_aussen" 4 "geschlossen_beide" 5 "Fehler" ;
VAL_ 2463978889 Mem_HBFSFo_Verr_Sensor_unten_re 0 "init" 1 "offen" 2 "geschlossen_innen" 3 "geschlossen_aussen" 4 "geschlossen_beide" 5 "Fehler" ;
VAL_ 2463978889 Mem_HBFSFo_LNV_aktiv 0 "inaktiv" 1 "aktiv" ;
VAL_ 2463978889 Mem_HBFSFo_SNV_aktiv 0 "inaktiv" 1 "aktiv" ;
VAL_ 2463978889 Mem_HBFSFo_KSV_aktiv 0 "inaktiv" 1 "aktiv" ;
VAL_ 2463978889 Mem_HBFSFo_LKV_aktiv 0 "inaktiv" 1 "aktiv" ;
VAL_ 2463978889 Mem_HBFSFo_STV_aktiv 0 "inaktiv" 1 "aktiv" ;
VAL_ 2463978889 Mem_HBFSFo_BANV_aktiv 0 "inaktiv" 1 "aktiv" ;
VAL_ 2463978889 Mem_HBFSFo_LED_EA_Taster 0 "aus" 1 "Blinken_1Hz" 2 "Blinken_2Hz" 3 "an" ;
VAL_ 1178 FS_Fond_Bed_enable 0 "disable" 1 "enable" ;
VAL_ 1178 FS_Lehne_nicht_verriegelt 0 "keine Anzeige" 1 "Lehne_nicht_verriegelt" ;
VAL_ 1178 FS_Spezialposition_anfahren 0 "Fkt_inaktiv" 1 "Fkt_aktiv" ;
VAL_ 1178 FS_Gurtbringer_Sperre 0 "Gurtzubringer_freigegeben" 1 "Gurtzubringer_gesperrt" ;
VAL_ 1178 FS_BFS_Sitzsym_Anfahrt 0 "keine Sitzsymetrie Anfahrt BFS" 1 "Sitzsymetrie Anfahrt BFS" ;
VAL_ 1178 FS_Sitzfahrt_aktiv 0 "Sitz_nicht_in_Bewegung" 1 "Sitz_in_Bewegung" ;
VAL_ 1178 FS_SLV_aktiv 0 "nicht_aktiv" 1 "Sitzlaengsverstellung aktiv" ;
VAL_ 1178 FS_SHV_aktiv 0 "nicht_aktiv" 1 "Sitzhoehenverstellung aktiv" ;
VAL_ 1178 FS_LNV_aktiv 0 "nicht_aktiv" 1 "Lehnenneigungverstellung aktiv" ;
VAL_ 1178 FS_SNV_aktiv 0 "nicht_aktiv" 1 "Sitzneigungsverstellung_aktiv" ;
VAL_ 1178 FS_KSV_aktiv 0 "nicht_aktiv" 1 "Kopfstuetzenverstellung aktiv" ;
VAL_ 1178 FS_LKV_aktiv 0 "nicht_aktiv" 1 "Lehnenkopfverstellung aktiv" ;
VAL_ 1178 FS_STV_aktiv 0 "nicht_aktiv" 1 "Sitztiefeverstellung aktiv" ;
VAL_ 1178 FS_LHV_aktiv 0 "nicht_aktiv" 1 "Lordose Höhe Verstellung aktiv" ;
VAL_ 1178 FS_LWV_aktiv 0 "nicht_aktiv" 1 "Lordose W Verstellung aktiv" ;
VAL_ 1178 FS_GHV_aktiv 0 "nicht_aktiv" 1 "Gurthoehenverstellung aktiv" ;
VAL_ 1178 FS_BFS_KSS_Anfahrt 0 "keine Anfahrt KSS BFS" 1 "Anfahrt KSS BFS" ;
VAL_ 1178 FS_MMB_lokal_Stop 0 "kein_Abbruch" 1 "lokaler_Abbruch" ;
VAL_ 1178 FS_MMB_storage 0 "keine_Zuweisung" 1 "P1_FP1_Pos_Zuweisung" 2 "P2_FP2_Pos_Zuweisung" 3 "P3_FP3_Pos_Zuweisung" 4 "P4_FP4_Pos_Zuweisung" 5 "FS1_bzw_Benutzerkonto_1" 6 "FS2_bzw_Benutzerkonto_2" 7 "FS3_bzw_Benutzerkonto_3" 8 "FS4_bzw_Benutzerkonto_4" 9 "FS5_bzw_Benutzerkonto_5" 10 "FS6_bzw_Benutzerkonto_6" 11 "FS7_bzw_Benutzerkonto_7" ;
VAL_ 1178 FS_MMB_tipp 0 "kein_Tippbetrieb" 1 "Tippbetrieb__automatisches_Funks" ;
VAL_ 1178 FS_MMB_tast 0 "kein_Tastbetrieb" 1 "Tastbetrieb__Fingerprintautomati" ;
VAL_ 1178 FS_MMB_store_LED_on 0 "LED_aus" 1 "LED_ein" ;
VAL_ 1178 FS_MMB_storage_beep 0 "beep aus" 1 "beep ein" ;
VAL_ 1178 FS_MMB_store 0 "nicht_speichern__kein_keyless_ve" 1 "abspeichern__keyless_verbaut" ;
VAL_ 1178 FS_MMB_glob_stop 0 "kein_globaler_Abbrucht" 1 "globaler_Abbruch" ;
VAL_ 1178 FS_EE_Fond_FS_enable 0 "EE Fond links deaktiv" 1 "EE Fond links aktiv (default) vom MMI" ;
VAL_ 1178 FS_EE_Fond_BFS_enable 0 "EE Fond rechts deaktiv" 1 "EE Fond rechts aktiv (default) vom MMI" ;
VAL_ 1178 FS_EE_BFS_enable 0 "keine_EE_Freigabe" 1 "EE_Freigabe" ;
VAL_ 956 Mem_FSFo_Lordose_hoch 0 "Aus" 1 "Ein" ;
VAL_ 956 Mem_FSFo_Lordose_runter 0 "Aus" 1 "Ein" ;
VAL_ 956 Mem_FSFo_Lordose_vor 0 "Aus" 1 "Ein" ;
VAL_ 956 Mem_FSFo_Lordose_zurueck 0 "Aus" 1 "Ein" ;
VAL_ 956 Mem_FSFo_Massage_Geschw 0 "Aus" 1 "Stufe1" 2 "Stufe2" 3 "Stufe3" 4 "Stufe4" 5 "Stufe5" ;
VAL_ 956 Mem_FSFo_Massage_Intens 0 "Aus" 1 "Stufe1" 2 "Stufe2" 3 "Stufe3" 4 "Stufe4" 5 "Stufe5" ;
VAL_ 956 Mem_FSFo_MMB_storage 0 "keine_Zuweisung" 1 "P1/FP1_MemoryPos" 2 "P2/FP2_MemoryPos" 3 "P3/FP3_MemoryPos" ;
VAL_ 956 Mem_FSFo_Massage_Prg 0 "Aus" 1 "Programm1" 2 "Programm2" 3 "Programm3" 4 "Programm4" 5 "Programm5" ;
VAL_ 956 Mem_FSFo_MMB_tast 0 "kein_Tastbetrieb" 1 "Tastbetrieb" ;
VAL_ 956 Mem_FSFo_MMB_tipp 0 "kein_Tippbetrieb" 1 "Tippbetrieb" ;
VAL_ 956 Mem_FSFo_MMB_glob_Stop 0 "kein_Abbruch" 1 "Abbruch" ;
VAL_ 956 Mem_FSFo_Sitztiefe_vor 0 "Aus" 1 "Ein" ;
VAL_ 956 Mem_FSFo_Sitztiefe_zur 0 "Aus" 1 "Ein" ;
VAL_ 956 Mem_FSFo_MMB_store 0 "nicht_speichern" 1 "speichern" ;
VAL_ 956 Mem_FSFo_MMB_storage_beep 0 "Beep_aus" 1 "Beep_ein" ;
VAL_ 956 Mem_FSFo_MMB_store_LED_on 0 "LED_aus" 1 "LED_ein" ;
VAL_ 956 Mem_HFSFo_EA_Taster 0 "nicht_betaetigt" 1 "betaetigt" ;
VAL_ 956 Mem_FSFo_MMB_lokal_Stop 0 "kein_Abbruch" 1 "lokaler_Abbruch" ;
VAL_ 956 Mem_FSFo_Sitzfahrt_aktiv 0 "nicht_aktiv" 1 "Sitzfahrt_Aktiv" ;
VAL_ 956 Mem_HFSFo_Unlocked 0 "init" 1 "verriegelt" 2 "entriegelt" ;
VAL_ 956 Mem_FSFo_Warn_Verriegelung 0 "inaktiv_Init" 1 "Sitzdrehung_hinten_links_aktiv" 2 "Sitzdrehung_hinten_links_inaktiv" 3 "Fehler_aktiv" ;
VAL_ 956 Mem_FSFo_Business_anfahren 0 "inaktiv" 1 "Business_anfahren" ;
VAL_ 956 Mem_FSFo_Relax_anfahren 0 "inaktiv" 1 "Relax_aktivieren" ;
VAL_ 956 Mem_FSFo_Warn_Dreh_entriegelt 0 "inaktiv_Init" 1 "Notentriegelung_HFS_akiv" 2 "Notentriegelung_HFS_inaktiv" 3 "Lehnenneigung_falsch_HFS_akiv" 4 "Lehnenneigung_falsch_HFS_inaktiv" 5 "Kissenneigung_falsch_HFS_akiv" 6 "Kissenneigung_falsch_HFS_inaktiv" 7 "Fehler_aktiv" ;
VAL_ 956 Mem_HFS_Seat_Attention 0 "init" 1 "Armlehne" 2 "Sitzlehne" 3 "Sitzhoehe" 4 "Sitzlaenge" 5 "Sitzneigung" 6 "Beinauflage" 7 "Fehler" ;
VAL_ 2463978890 Mem_HFSFo_Warnung_Softstop 0 "keine_Warnmeldung" 1 "Warnmeldung" 2 "Reserve" 3 "Fehler" ;
VAL_ 2463978890 Mem_HFSFo_Stoerung 0 "kein_Fehler_Sitz" 1 "Fehler_Sitz_aktiv" ;
VAL_ 2463978890 Mem_HFSFo_globaler_Lehnenwinkel 254 "init" 255 "Fehler" ;
VAL_ 2463978890 Mem_HFSFo_globaler_Sitzflachenwi 254 "init" 255 "Fehler" ;
VAL_ 2463978890 Mem_HFSFo_Sperre_Sitzdisplay 0 "Displaysperre_HFS_aus" 1 "Displaysperre_HFS_an" ;
VAL_ 2463978890 Mem_HFSFo_Abschaltanf_SRAB 0 "Einschaltung_SRAB" 1 "Abschaltung_SRAB" 2 "Init" 3 "Fehler" ;
VAL_ 2463978890 Mem_HFSFo_Anzeige_Komfort_HFS 0 "keine_Statusanzeige" 1 "Anzeige_Lehne_ein_mitTon" 2 "Anzeige_SNV_ein_mitTon" 3 "Anzeige_Lehne_UND_SNV_ein_mitTon" 4 "Anzeige_Lehne_ein_oTon" 5 "Anzeige_SNV_ein_oTon" 6 "Anzeige_Lehne_UND_SNV_ein_oTon" ;
VAL_ 2463978890 Mem_HFSFo_Status_Schalter_Ki_Si 0 "Schalter_Kindersitz_ein" 1 "Schalter_Kindersitz_aus" 2 "Init" 3 "Fehler" ;
VAL_ 2463978890 Mem_HFSFo_ARMTuer_aktiv 0 "inaktiv" 1 "aktiv" ;
VAL_ 2463978890 Mem_HFSFo_ARMTunnel_aktiv 0 "inaktiv" 1 "aktiv" ;
VAL_ 2463978890 Mem_HFSFo_SHV_aktiv 0 "inaktiv" 1 "aktiv" ;
VAL_ 2463978890 Mem_HFSFo_SLV_aktiv 0 "inaktiv" 1 "aktiv" ;
VAL_ 2463978890 Mem_HFSFo_SLV_hinten 0 "nicht_hinten" 1 "hinten" ;
VAL_ 2463978890 Mem_HFSFo_BATV_aktiv 0 "inaktiv" 1 "aktiv" ;
VAL_ 2463978890 Mem_HFSFo_EE_Verr_Sensor_li 0 "init" 1 "offen" 2 "geschlossen_innen" 3 "geschlossen_aussen" 4 "geschlossen_beide" 5 "Fehler" ;
VAL_ 2463978890 Mem_HFSFo_Verr_Sensor_oben_li 0 "init" 1 "offen" 2 "geschlossen_innen" 3 "geschlossen_aussen" 4 "geschlossen_beide" 5 "Fehler" ;
VAL_ 2463978890 Mem_HFSFo_Verr_Sensor_unten_li 0 "init" 1 "offen" 2 "geschlossen_innen" 3 "geschlossen_aussen" 4 "geschlossen_beide" 5 "Fehler" ;
VAL_ 2463978890 Mem_HFSFo_LNV_aktiv 0 "inaktiv" 1 "aktiv" ;
VAL_ 2463978890 Mem_HFSFo_SNV_aktiv 0 "inaktiv" 1 "aktiv" ;
VAL_ 2463978890 Mem_HFSFo_KSV_aktiv 0 "inaktiv" 1 "aktiv" ;
VAL_ 2463978890 Mem_HFSFo_LKV_aktiv 0 "inaktiv" 1 "aktiv" ;
VAL_ 2463978890 Mem_HFSFo_STV_aktiv 0 "inaktiv" 1 "aktiv" ;
VAL_ 2463978890 Mem_HFSFo_BANV_aktiv 0 "inaktiv" 1 "aktiv" ;
VAL_ 2463978890 Mem_HFSFo_LED_EA_Taster 0 "aus" 1 "Blinken_1Hz" 2 "Blinken_2Hz" 3 "an" ;
VAL_ 2463978890 Mem_HFSFo_EA_Position 0 "nicht_EA_Position" 1 "EA_Position" ;
VAL_ 1171 MF_ZV_Lock 0 "Locktaster_nicht_betaetigt" 1 "Locktaster_betaetigt" ;
VAL_ 1171 MF_Motorweiterlauf 0 "inaktiv" 1 "aktiv" ;
VAL_ 1171 MF_Abzugssperre 0 "inaktiv" 1 "aktiv" ;
VAL_ 1171 MF_Anlassersperre 0 "inaktiv" 1 "aktiv" ;
VAL_ 1171 MF_Variante 0 "keine_Sonderfunktion" 1 "Sondersignalfahrzeug" 2 "Taxi" 3 "Fahrhilfe" 4 "Fahrschule_Extra" 5 "SSF" 6 "DBMC" 7 "Arbeitsmaschine" ;
VAL_ 1171 MF_Schluessel_scan 0 "inaktiv" 1 "aktiv" ;
VAL_ 1171 MF_Laderelais 0 "Relais_offen" 1 "Relais_geschlossen" ;
VAL_ 1171 MF_StartStopp_Info 0 "Motorlauf_nicht_notwendig_(Stoppfreigabe)" 1 "Motoranlauf_nicht_zwingend_notwendig_(Stoppverbot,keine_Startanforderung)" 2 "Motoranlauf_zwingend_notwendig_(Startanforderung)" 3 "Systemfehler" ;
VAL_ 1171 MF_Fernbed_ein 0 "inaktiv" 1 "aktiv" ;
VAL_ 1171 MF_Standlicht 0 "inaktiv" 1 "aktiv" ;
VAL_ 1171 MF_Fahrlicht 0 "inaktiv" 1 "aktiv" ;
VAL_ 1171 MF_interm_Fernlicht 0 "inaktiv" 1 "aktiv" ;
VAL_ 1171 MF_Warnblinker 0 "inaktiv" 1 "aktiv" ;
VAL_ 1171 MF_Fussraumbel 0 "inaktiv" 1 "aktiv" ;
VAL_ 1171 MF_Innenraumbel 0 "inaktiv" 1 "aktiv" ;
VAL_ 1171 MF_Innenraumbel_Unterdrueck 0 "inaktiv" 1 "aktiv" ;
VAL_ 1171 MF_Notstart 0 "kein_Notstart" 1 "Notstart" ;
VAL_ 1171 MF_Blk_li 0 "inaktiv" 1 "aktiv" ;
VAL_ 1171 MF_Blk_re 0 "inaktiv" 1 "aktiv" ;
VAL_ 1171 MF_Lichthupe 0 "inaktiv" 1 "aktiv" ;
VAL_ 1171 MF_Fernlicht 0 "inaktiv" 1 "aktiv" ;
VAL_ 1171 MF_HFS_verriegeln 0 "nicht_verriegeln" 1 "verriegeln" ;
VAL_ 1171 MF_HFS_entriegeln 0 "nicht_entriegeln" 1 "entriegeln" ;
VAL_ 1171 MF_HBFS_verriegeln 0 "nicht_verriegeln" 1 "verriegeln" ;
VAL_ 1171 MF_HBFS_entriegeln 0 "nicht_entriegeln" 1 "entriegeln" ;
VAL_ 1171 MF_Tippwischen 0 "inaktiv" 1 "aktiv" ;
VAL_ 1171 MF_Frontintervall 0 "inaktiv" 1 "aktiv" ;
VAL_ 1171 MF_Wischerstufe_1 0 "inaktiv" 1 "aktiv" ;
VAL_ 1171 MF_Wischerstufe_2 0 "inaktiv" 1 "aktiv" ;
VAL_ 1171 MF_Frontwaschen 0 "inaktiv" 1 "aktiv" ;
VAL_ 1171 MF_nachtr_Stopp_Anf 0 "nicht_angefordert" 1 "angefordert" ;
VAL_ 1171 MF_Heckintervall 0 "inaktiv" 1 "aktiv" ;
VAL_ 1171 MF_Heckwaschen 0 "inaktiv" 1 "aktiv" ;
VAL_ 1171 MF_Summer 0 "inaktiv" 1 "aktiv" ;
VAL_ 1171 MF_Alarm_Blinkertakt 0 "inaktiv" 1 "aktiv" ;
VAL_ 1171 MF_Alarm_Blinker 0 "inaktiv" 1 "aktiv" ;
VAL_ 1171 MF_TFL_Abschaltung 0 "inaktiv" 1 "aktiv" ;
VAL_ 1171 MF_interm_Takt 0 "inaktiv" 1 "aktiv" ;
VAL_ 1171 MF_Tuerentriegelung_hinten 0 "inaktiv" 1 "aktiv" ;
VAL_ 1171 MF_interm_Fahrlicht 0 "inaktiv" 1 "aktiv" ;
VAL_ 1171 MF_Signalhorn 0 "inaktiv" 1 "aktiv" ;
VAL_ 1171 MF_FH_FT_hoch 0 "inaktiv" 1 "aktiv" ;
VAL_ 1171 MF_FH_FT_tief 0 "inaktiv" 1 "aktiv" ;
VAL_ 1171 MF_FH_BT_hoch 0 "inaktiv" 1 "aktiv" ;
VAL_ 1171 MF_FH_BT_tief 0 "inaktiv" 1 "aktiv" ;
VAL_ 1171 MF_FT_verriegeln 0 "nicht_verriegeln" 1 "verriegeln" ;
VAL_ 1171 MF_FT_entriegeln 0 "nicht_entriegeln" 1 "entriegeln" ;
VAL_ 1171 MF_BT_verriegeln 0 "nicht_verriegeln" 1 "verriegeln" ;
VAL_ 1171 MF_BT_entriegeln 0 "nicht_entriegeln" 1 "entriegeln" ;
VAL_ 1165 MF_VBEG_Anforderung 0 "nicht_angefordert" 1 "angefordert" ;
VAL_ 1165 MF_MFSS_aktiv 0 "inaktiv" 1 "aktiv" ;
VAL_ 1165 MF_MFSS_kodiert 0 "auskodiert" 1 "kodiert" ;
VAL_ 1165 MFG_Status_SREG 0 "Sperrung_SREG" 1 "Keine_SREG_Sperrung" ;
VAL_ 1165 MFG_Taster_SREG 0 "Taster_SREG_inaktiv" 1 "Taster_SREG_aktiviert" 2 "Init" 3 "Fehler" ;
VAL_ 1165 MFG_Taster_VREG 0 "Taster_VREG_inaktiv" 1 "Taster_VREG_aktiviert" 2 "Init" 3 "Fehler" ;
VAL_ 1165 MFG_Heizstufe_LSH 0 "Init" 1 "Stufe_1" 2 "Stufe_2" 3 "Stufe_3" 4 "Stufe_4" 5 "Stufe_5" 6 "Stufe_6" 7 "Stufe_7" 8 "Stufe_8" 9 "Stufe_9" 10 "Stufe_10" 15 "Fehler" ;
VAL_ 1165 MFG_Zuheizer_Freigabe 0 "keine_Freigabe_Zuheizer" 1 "Zuheizerfreigabe" ;
VAL_ 1165 MF_VBEG_Geschwindigkeit 255 "Init" ;
VAL_ 1165 MF_ADR_Fahrpedalsperre 0 "inaktiv" 1 "aktiv" ;
VAL_ 1165 MF_ADR_Anforderung 0 "nicht_angefordert" 1 "angefordert" ;
VAL_ 1164 MFG_Infotainment_Autark 0 "Autarkie_no" 1 "Autarkie_yes" ;
VAL_ 1164 MFG_Klappe_Status 0 "Init" 1 "Front" 2 "Heck" 3 "Front_u_Heck" 4 "misch_Front_u_Heck" ;
VAL_ 1164 MFG_LSH_DBetr_Ein 0 "Dauerbetrieb_nicht_gefordert" 1 "Dauerbetrieb_gefordert" ;
VAL_ 1164 MFG_LSH_Betriebsdauer 127 "Dauerbetrieb" ;
VAL_ 1164 MFG_LSH_DBetr_Bestaet 0 "kein_Dauerbetrieb" 1 "Dauerbetrieb_bestaetigt" ;
VAL_ 1164 MFG_LSH_Ansteuerung 0 "Aus" 1 "Ein" 2 "Kombi_Betrieb" 3 "Heizleistung_reduziert" ;
VAL_ 1164 MF_Radiomute 0 "Kein_Mute" 1 "Mute" ;
VAL_ 1164 MF_Relais_2_Batterie 0 "nicht_betaetigt" 1 "betaetigt" ;
VAL_ 1164 MF_Batteriediagnose 0 "keine_Anzeige" 1 "Anzeige_Batterieservice" 2 "Anzeige_aberkannte_Batterie" 3 "Anzeige_schwache_Batterie" 4 "Anzeige_Batterie_OK" 5 "Anzeige_Batterie_Laden" 6 "Anzeige_Batterie_Pruefen" 7 "Fehler" ;
VAL_ 1164 MFG_AppConnect_Anf 0 "AppConnect_keine_Anforderung" 1 "AppConnect_Anforderung" 2 "AppConnect_Darstellungsrueckgabe" ;
VAL_ 1164 MF_Lampenausfall 0 "iO" 1 "defekt" ;
VAL_ 1164 MF_Blinker_L_Sta 0 "inaktiv" 1 "aktiv" ;
VAL_ 1164 MF_Blinker_R_Sta 0 "inaktiv" 1 "aktiv" ;
VAL_ 1164 MF_interm_Nebelscheinwerfer 0 "inaktiv" 1 "aktiv" ;
VAL_ 1164 MF_Generatordiagnose 0 "keine_Warnung" 1 "Warnung_Stufe_1" 2 "Warnung_Stufe_2" 3 "Nicht_verbaut" ;
VAL_ 1164 MF_Heck_entriegeln 0 "nicht_entriegeln" 1 "entriegeln" ;
VAL_ 1164 MF_Heck_verriegeln 0 "nicht_verriegeln" 1 "verriegeln" ;
VAL_ 1164 MF_2BatSOCzugering 0 "inaktiv" 1 "aktiv" ;
VAL_ 1164 MF_Fahrerhinweis 0 "keine_Anzeige" 1 "Warnung_Verrollsicherheit" 2 "Warnung_Fahrzeug_im_Freien" 3 "Warnung_Verlassen_Verriegeln" 4 "reserved" 5 "reserved" 6 "reserved" 7 "reserved" ;
VAL_ 1164 MF_ZV_Unlock 0 "nicht_entriegeln" 1 "entriegeln" ;
VAL_ 1164 MF_Tuerverriegelung_hinten 0 "inaktiv" 1 "aktiv" ;
VAL_ 1164 MF_2BattAb 0 "inaktiv" 1 "aktiv" ;
VAL_ 1164 MF_2BattHlkAnf 0 "inaktiv" 1 "aktiv" ;
VAL_ 1164 MF_2BattLadWarn 0 "inaktiv" 1 "aktiv" ;
VAL_ 1164 MF_2BattLlaAnf 0 "inaktiv" 1 "aktiv" ;
VAL_ 1164 MF_2BattSpannungsAnf 0 "keine_Anforderung" 1 "Anforderung_Stufe1" 2 "Anforderung_Stufe2" 3 "Anforderung_Stufe3" ;
VAL_ 1164 MF_NotStartAktiv 0 "inaktiv" 1 "aktiv" ;
VAL_ 1164 MF_ExterneLadungWarn 0 "inaktiv" 1 "aktiv" ;
VAL_ 1164 MF_LSH_Zielzeit 14 "Init" 15 "Fehler" ;
VAL_ 1164 MF_LSH_Abschaltstufe 0 "Init" 1 "Stufe1" 2 "Stufe2" 3 "Stufe3" 4 "Transportmodus" 7 "Ruhestrommessmodus" ;
VAL_ 1164 MF_LSH_Einschaltverbot 0 "Init_volleVerfuegbarkeit" 1 "Standheizung_bzw_lueftung_nicht_aktivierbar" ;
VAL_ 2463978883 MF_Fahrerhinweis_2 0 "keine_Anzeige" 1 "Dach_zu_oft_bewegt" 2 "Aufstellvorbedingungen" 3 "Absenkvorbedingungen" 4 "Fehler_Aufstelldach_Werkstatt" 5 "Aufstelldach_offen" 6 "Aufstelldach_klemmt" 7 "Fehler_Aufstelldach_manuell" 8 "Aufstelldach_Endposition" 9 "Waehrend_Fahrt_nicht_moeglich" 10 "Zur_Zeit_nicht_moeglich" 11 "Batterie_schwach_Motorlauf" 12 "Ladestecker_ist_gesteckt" ;
VAL_ 2463978883 MF_U2Batt 251 "U_kleiner_min" 252 "U_groesser_max" 255 "init" ;
VAL_ 2463978883 MF_UBattVorgabe 63 "init" ;
VAL_ 2463978883 MF_I_U_VorgabeZwang 0 "Wunschvorgabe" 1 "Zwangsvorgabe" ;
VAL_ 2463978883 MF_Vorfeldbel_Spiegel 0 "Serienvorfeldbeleuchtung" 1 "Vorfeldbeleuchtung_Spiegel_aktiv" ;
VAL_ 2463978883 MF_DCDC_Istmodus 0 "Standby" 2 "Strom_ZusBn_ErstBn" 3 "Strom_ErstBn_ZusBn" 4 "Startunterstuetzung_ZusBn" 5 "Fehler" 7 "Init" 14 "Bypass" ;
VAL_ 1471 MFL_Tastencode_1 0 "Key_Released__No_Key" 1 "Context_Menu" 2 "Menu_Up__Next_Screen" 3 "Menu_Down__Previous_Screen" 4 "Up" 5 "Down" 6 "Up__Down_ThumbWheel" 7 "OK__ThumbWheel_Button" 8 "Cancel__Escape" 9 "Main_Menu" 10 "Side_Menu_left" 11 "Side_Menu_right" 12 "FAS_Menu" 13 "Left__Right_ThumbWheel" 14 "FAS_Menu_ThumbWheel" 16 "Volume_Up" 17 "Volume_Down" 18 "Volume_Up__Down_ThumbWheel" 19 "Volume_ThumbWheel_Button" 20 "Audio_Source" 21 "Arrow_A_Up__Right" 22 "Arrow_A_Down__Left" 23 "Arrow_B_Up__Right" 24 "Arrow_B_Down__Left" 25 "PTT__PushToTalk" 26 "PTT_Cancel" 27 "Route_Info" 28 "Hook" 29 "Hang_Up" 30 "Off_Hook" 31 "Light_On__Off" 32 "Mute" 33 "Joker1" 34 "Joker2" 35 "View" 36 "Arrow_A_Up__Down_ThumbWheel" 37 "Lenkradheizung" 38 "Rekuperation" 39 "Tube_Toggle" 40 "DRS_Drag_Reduction_System" 41 "Stopwatch_Start_Stop" 42 "Stopwatch_Nextlap" 100 "MAP" 101 "MAP_Boost" 102 "Turn_signal_left" 103 "Turn_signal_right" 104 "Turn_signal_off" 105 "Flashlight" 106 "Highbeam" 107 "Washer_button" 108 "Wiper_button_left" 109 "Wiper_button_right" 110 "Wiper_button_cancel" 111 "Exhaust_Sound" 112 "Drive_Select_button" 113 "Sport_button" 114 "ESP_Drift_Selection_ThumbWheel" 115 "PTT_special_vehicle" 116 "TravelAssist" 117 "Launch_Control" 118 "Drift_Mode_Button_Increase" 119 "Drift_Mode_Button_Decrease" 120 "Drift_Mode_Button_Select" 121 "Drive_Mode_Button_Increase" 122 "Drive_Mode_Button_Decrease" 123 "Drive_Mode_Button_Select" 124 "E_Boost_Button_Increase" 125 "E_Boost_Button_Decrease" 126 "E_Boost_Button_Select" 127 "PerformanceHybridButton_Increase" 128 "PerformanceHybridButton_Decrease" 129 "EV_Mode_Button" 130 "HUD_Button" 131 "PASM_Wheel" 132 "PASM_Button" 133 "PTV_Wheel" 134 "PTV_Button" 135 "TC_ESC_Wheel" 136 "TC_ESC_Button" 240 "Startup_Reset" 241 "Initialization" ;
VAL_ 1471 MFL_Tastencode_2 0 "Key_Released__No_Key" 1 "Context_Menu" 2 "Menu_Up__Next_Screen" 3 "Menu_Down__Previous_Screen" 4 "Up" 5 "Down" 6 "Up__Down_ThumbWheel" 7 "OK__ThumbWheel_Button" 8 "Cancel__Escape" 9 "Main_Menu" 10 "Side_Menu_left" 11 "Side_Menu_right" 12 "FAS_Menu" 13 "Left__Right_ThumbWheel" 14 "FAS_Menu_ThumbWheel" 16 "Volume_Up" 17 "Volume_Down" 18 "Volume_Up__Down_ThumbWheel" 19 "Volume_ThumbWheel_Button" 20 "Audio_Source" 21 "Arrow_A_Up__Right" 22 "Arrow_A_Down__Left" 23 "Arrow_B_Up__Right" 24 "Arrow_B_Down__Left" 25 "PTT__PushToTalk" 26 "PTT_Cancel" 27 "Route_Info" 28 "Hook" 29 "Hang_Up" 30 "Off_Hook" 31 "Light_On__Off" 32 "Mute" 33 "Joker1" 34 "Joker2" 35 "View" 36 "Arrow_A_Up_Right_Down_Left_ThumbWheel" 37 "Lenkradheizung" 38 "Rekuperation" 39 "Tube_Toggle" 40 "DRS_Drag_Reduction_System" 41 "Stopwatch_Start_Stop" 42 "Stopwatch_Nextlap" 100 "MAP" 101 "MAP_Boost" 102 "Turn_signal_left" 103 "Turn_signal_right" 104 "Turn_signal_off" 105 "Flashlight" 106 "Highbeam" 107 "Washer_button" 108 "Wiper_button_left" 109 "Wiper_button_right" 110 "Wiper_button_cancel" 111 "Exhaust_Sound" 112 "Drive_Select_button" 113 "Sport_button" 114 "ESP_Drift_Selection_ThumbWheel" 115 "PTT_special_vehicle" 116 "TravelAssist" 117 "Launch_Control" 118 "Drift_Mode_Button_Increase" 119 "Drift_Mode_Button_Decrease" 120 "Drift_Mode_Button_Select" 121 "Drive_Mode_Button_Increase" 122 "Drive_Mode_Button_Decrease" 123 "Drive_Mode_Button_Select" 124 "E_Boost_Button_Increase" 125 "E_Boost_Button_Decrease" 126 "E_Boost_Button_Select" 127 "PerformanceHybridButton_Increase" 128 "PerformanceHybridButton_Decrease" 129 "EV_Mode_Button" 130 "HUD_Button" 131 "PASM_Wheel" 132 "PASM_Button" 133 "PTV_Wheel" 134 "PTV_Button" 135 "TC_ESC_Wheel" 136 "TC_ESC_Button" 240 "Startup_Reset" 241 "Initialization" ;
VAL_ 1471 MFL_Eventcode_1 0 "W_no_event____T_no_event" 1 "W_1_Tick_up__T_pressed_normal" 2 "W_2_Ticks_up__T_touched" 3 "W_3_Ticks_up__T_double_click_nor" 4 "W_4_Ticks_up__T_long_press_nor_1" 5 "W_5_Ticks_up__T_long_press_nor_2" 6 "W_6_Ticks_up__T_long_press_nor_3" 7 "W_7_Ticks_up" 9 "W_7_Ticks_dn__T_pressed_strong" 10 "W_6_Ticks_dn" 11 "W_5_Ticks_dn__T_double_click_str" 12 "W_4_Ticks_dn__T_long_press_str_1" 13 "W_3_Ticks_dn__T_long_press_str_2" 14 "W_2_Ticks_dn__T_long_press_str_3" 15 "W_1_Tick_dn" ;
VAL_ 1471 MFL_Eventcode_2 0 "W_no_event____T_no_event" 1 "W_1_Tick_up__T_pressed_normal" 2 "W_2_Ticks_up__T_touched" 3 "W_3_Ticks_up__T_double_click_nor" 4 "W_4_Ticks_up__T_long_press_nor_1" 5 "W_5_Ticks_up__T_long_press_nor_2" 6 "W_6_Ticks_up__T_long_press_nor_3" 7 "W_7_Ticks_up" 9 "W_7_Ticks_dn__T_pressed_strong" 10 "W_6_Ticks_dn" 11 "W_5_Ticks_dn__T_double_click_str" 12 "W_4_Ticks_dn__T_long_press_str_1" 13 "W_3_Ticks_dn__T_long_press_str_2" 14 "W_2_Ticks_dn__T_long_press_str_3" 15 "W_1_Tick_dn" ;
VAL_ 1471 MFL_Marke 0 "VW" 1 "Audi" 2 "Seat" 3 "Skoda" 4 "VW_Nutzf" 5 "Bugatti" 6 "Lamborghini" 7 "Bentley" 8 "Rolls Royce" 9 "Quattro" 10 "kein_Hersteller_1" 11 "kein_Hersteller_2" 12 "kein_Hersteller_3" 13 "kein_Hersteller_4" 14 "Ford" 15 "Porsche" ;
VAL_ 1600 MO_QBit_Ansaugluft_Temp 0 "gueltiger_Wert" 1 "Ersatz_Init_oder_Fehlerwert" ;
VAL_ 1600 MO_QBit_Oel_Temp 0 "gueltiger_Wert" 1 "Ersatz_Init_oder_Fehlerwert" ;
VAL_ 1600 MO_QBit_Kuehlmittel_Temp 0 "gueltiger_Wert" 1 "Ersatz_Init_oder_Fehlerwert" ;
VAL_ 1600 MO_KL15_Abschaltempfehlung 0 "Keine Empfehlung" 1 "Abschaltempfehlung" ;
VAL_ 1600 MO_HYB_Fehler_HV_Netz 0 "i_O" 1 "kein_generatorischer_Betrieb_moeglich" ;
VAL_ 1600 MO_aktives_Getriebeheizen 0 "kein_Ventil_ansteuern" 1 "Ventil_muss_angesteuert_werden" ;
VAL_ 1600 MO_Absperrventil_oeffnen 0 "nicht_verfuegbar" 1 "Ansteuerung_Ventil_zulaessig" 2 "Ventil_oeffnen_oder_geoeffnet" 3 "Ventil_schliessen_oder_geschlossen" ;
VAL_ 1600 MO_Ansaugluft_Temp 254 "Init" 255 "Fehler" ;
VAL_ 1600 MO_Oel_Temp 253 "nicht_verbaut" 254 "Init" 255 "Fehler" ;
VAL_ 1600 MO_Kuehlmittel_Temp 254 "Init" 255 "Fehler" ;
VAL_ 1600 MO_Hoeheninfo 255 "Fehler" ;
VAL_ 1600 MO_Kennfeldk 0 "keine Kennfeldkühlung vorhanden" 1 "Kennfeldkühlung vorhanden" ;
VAL_ 1600 MO_Versionsinfo_02 0 "zum_Projektbeginn_aufgeraeumter_CAN" 1 "Motor_03_mit_10ms" 16 "MQB_mit_neuer_Momentenschnittstelle" ;
VAL_ 1600 MO_QBit_Hoeheninfo 0 "gueltiger_Wert" 1 "Ersatz_Init_oder_Fehlerwert" ;
VAL_ 1600 MO_Getriebe_kuehlen 0 "nicht_kuehlen" 1 "kuehlen" ;
VAL_ 1600 MO_Heizungspumpenansteuerung 13 "Fehler" 14 "Init" 15 "nicht_verbaut" ;
VAL_ 1600 MO_SpannungsAnf 0 "keine_Anforderung" 1 "Anforderung" ;
VAL_ 1607 MO_ITM_Kuehlmittel_Temp 0 "nicht_verbaut" 1 "Init" 2 "Fehler" ;
VAL_ 1607 MO_E85_Sensor 13 "nicht_verbaut" 14 "Init" 15 "Fehler" ;
VAL_ 1607 SCR_Anz_Motorstarts 0 "Anzahl_moeglicher_Restarts" 1 "Anzahl_moeglicher_Restarts" 2 "Anzahl_moeglicher_Restarts" 3 "Anzahl_moeglicher_Restarts" 4 "Anzahl_moeglicher_Restarts" 5 "Anzahl_moeglicher_Restarts" 6 "Anzahl_moeglicher_Restarts" 7 "Anzahl_moeglicher_Restarts" 8 "Anzahl_moeglicher_Restarts" 9 "Anzahl_moeglicher_Restarts" 10 "Anzahl_moeglicher_Restarts" 11 "Anzahl_moeglicher_Restarts" 12 "Anzahl_moeglicher_Restarts" 13 "Anzahl_moeglicher_Restarts" 14 "Fahrbarkeitseinschraenkung" 15 "keine_Einschraenkung" ;
VAL_ 1607 SCR_Reichweite 32767 "keine_Anzeige" ;
VAL_ 1607 MO_Ethanol_Spuelhinweis 0 "Kein_Hinweis" 1 "Spuelhinweis_aktiv" ;
VAL_ 1607 SCR_Warnstufe_1 0 "nicht_aktiv" 1 "Warnstufe_1_aktiv" ;
VAL_ 1607 SCR_Warnstufe_2 0 "nicht_aktiv" 1 "Warnstufe_2_aktiv" ;
VAL_ 1607 SCR_Text 0 "kein_Text" 1 "Warntext_1" 2 "Warntext_2" 3 "Hinweis_Fuellstand" 4 "Reserve" 5 "SysFehler_1" 6 "SysFehler_2" 7 "Hinweis_Systemfehler" ;
VAL_ 1607 SCR_Akustik 0 "keine_Akustik" 1 "Akustik_1" 2 "Akustik_2" 3 "Akustik_bei_Hinweis" ;
VAL_ 1607 SCR_verbaut 0 "kein_SCR" 1 "SCR_verbaut" ;
VAL_ 1607 MO_Kraftstofffilter_Wasser 0 "keine_Anzeige" 1 "Abscheidevolumen_erschoepft" ;
VAL_ 1607 SCR_Systemfehler 0 "Warnung_nicht_aktiv" 1 "Warnung_aktiv" ;
VAL_ 1607 SCR_Inducement_Strategie 0 "Restart_Strategie" 1 "Reduced_Drivability_Strategie" ;
VAL_ 1607 MO_CO2_Faktor 0 "nicht_verbaut" 4095 "Fehler" ;
VAL_ 1607 MO_MKB_MUX 0 "MKB_01" 1 "MKB_02" 2 "MKB_03" 3 "MKB_04" ;
VAL_ 1607 MO_MKB_01 0 "Minus" 1 "A" 2 "B" 3 "C" 4 "D" 5 "E" 6 "F" 7 "G" 8 "H" 9 "I" 10 "J" 11 "K" 12 "L" 13 "M" 14 "N" 15 "O" 16 "P" 17 "Q" 18 "R" 19 "S" 20 "T" 21 "U" 22 "V" 23 "W" 24 "X" 25 "Y" 26 "Z" 27 "Leerzeichen" 28 "Leerzeichen" 29 "Leerzeichen" 30 "Leerzeichen" 31 "Unterstrich" ;
VAL_ 1607 MO_MKB_02 0 "Minus" 1 "A" 2 "B" 3 "C" 4 "D" 5 "E" 6 "F" 7 "G" 8 "H" 9 "I" 10 "J" 11 "K" 12 "L" 13 "M" 14 "N" 15 "O" 16 "P" 17 "Q" 18 "R" 19 "S" 20 "T" 21 "U" 22 "V" 23 "W" 24 "X" 25 "Y" 26 "Z" 27 "Leerzeichen" 28 "Leerzeichen" 29 "Leerzeichen" 30 "Leerzeichen" 31 "Unterstrich" ;
VAL_ 1607 MO_MKB_03 0 "Minus" 1 "A" 2 "B" 3 "C" 4 "D" 5 "E" 6 "F" 7 "G" 8 "H" 9 "I" 10 "J" 11 "K" 12 "L" 13 "M" 14 "N" 15 "O" 16 "P" 17 "Q" 18 "R" 19 "S" 20 "T" 21 "U" 22 "V" 23 "W" 24 "X" 25 "Y" 26 "Z" 27 "Leerzeichen" 28 "Leerzeichen" 29 "Leerzeichen" 30 "Leerzeichen" 31 "Unterstrich" ;
VAL_ 1607 MO_MKB_04 0 "Minus" 1 "A" 2 "B" 3 "C" 4 "D" 5 "E" 6 "F" 7 "G" 8 "H" 9 "I" 10 "J" 11 "K" 12 "L" 13 "M" 14 "N" 15 "O" 16 "P" 17 "Q" 18 "R" 19 "S" 20 "T" 21 "U" 22 "V" 23 "W" 24 "X" 25 "Y" 26 "Z" 27 "Leerzeichen" 28 "Leerzeichen" 29 "Leerzeichen" 30 "Leerzeichen" 31 "Unterstrich" ;
